VERSION ""

NS_ :

BS_:
BU_: ACC GW LAS BDC

BO_ 943 GW_3AF: 64 GW
 SG_ HU_RampInfo_EU : 263|2@0+ (1.0000000000,0.0000000000) [0.0000000000|3.0000000000] ""  ACC,LAS,mADC
 SG_ HU_MaxNavSpeed : 127|8@0+ (1.0000000000,0.0000000000) [0.0000000000|255.0000000000] ""  ACC,LAS,mADC
 SG_ HU_MapStatus : 114|3@0+ (1.0000000000,0.0000000000) [0.0000000000|7.0000000000] ""  ACC,LAS,mADC
 SG_ HU_NavSpeedLimit_EU : 487|8@0+ (1.0000000000,0.0000000000) [0.0000000000|255.0000000000] ""  ACC,LAS,mADC
 SG_ HU_ForwardRoadType_EU : 287|3@0+ (1.0000000000,0.0000000000) [0.0000000000|7.0000000000] ""  ACC,LAS,mADC
 SG_ HU_NavCurrentRoadType_EU : 284|3@0+ (1.0000000000,0.0000000000) [0.0000000000|7.0000000000] ""  ACC,LAS,mADC
 SG_ HU_NavCountryCode_EU : 447|8@0+ (1.0000000000,0.0000000000) [0.0000000000|255.0000000000] ""  ACC,LAS,mADC
 SG_ HU_realtimeNavRoadSpeedLimitType : 311|2@0+ (1.0000000000,0.0000000000) [0.0000000000|3.0000000000] ""  ACC,LAS,mADC
 SG_ HU_realtimeNavSpeedLimit : 439|8@0+ (1.0000000000,0.0000000000) [0.0000000000|255.0000000000] ""  ACC,LAS,mADC
 SG_ HU_FogSpeedLimit : 303|8@0+ (1.0000000000,0.0000000000) [0.0000000000|255.0000000000] ""  ACC,LAS,mADC
 SG_ HU_NavRoadSpeedLimitType : 309|2@0+ (1.0000000000,0.0000000000) [0.0000000000|3.0000000000] ""  ACC,LAS,mADC
 SG_ HU_SnowSpeedLimit : 63|8@0+ (1.0000000000,0.0000000000) [0.0000000000|255.0000000000] ""  ACC,LAS,mADC
 SG_ HU_RainSpeedLimit : 55|8@0+ (1.0000000000,0.0000000000) [0.0000000000|255.0000000000] ""  ACC,LAS,mADC
 SG_ HU_CRCCheck_3AF : 503|16@0+ (1.0000000000,0.0000000000) [0.0000000000|65535.0000000000] ""  ACC,LAS
 SG_ HU_RollingCounter_3AF : 491|4@0+ (1.0000000000,0.0000000000) [0.0000000000|15.0000000000] ""  ACC,LAS
 SG_ HU_ADAS_Posn_Offset : 353|13@0+ (1.0000000000,0.0000000000) [0.0000000000|8191.0000000000] "m"  ACC,LAS,mADC
 SG_ HU_ADAS_Posn_Pathldx : 359|6@0+ (1.0000000000,0.0000000000) [0.0000000000|63.0000000000] ""  ACC,LAS,mADC
 SG_ HU_LaneConfluenceDis : 155|6@0+ (10.0000000000,0.0000000000) [0.0000000000|600.0000000000] "m"  ACC,LAS,mADC
 SG_ HU_LaneConfluence : 157|2@0+ (1.0000000000,0.0000000000) [0.0000000000|3.0000000000] ""  ACC,LAS,mADC
 SG_ HU_IntervalVelocityDis : 139|6@0+ (10.0000000000,0.0000000000) [0.0000000000|600.0000000000] "m"  ACC,LAS,mADC
 SG_ HU_IntervalVelocityInfo : 141|2@0+ (1.0000000000,0.0000000000) [0.0000000000|3.0000000000] ""  ACC,LAS,mADC
 SG_ HU_CRCCheck_3AF_3 : 255|8@0+ (1.0000000000,0.0000000000) [0.0000000000|255.0000000000] ""  LAS,ACC,mADC
 SG_ HU_RollingCounter_3AF_3 : 243|4@0+ (1.0000000000,0.0000000000) [0.0000000000|15.0000000000] ""  LAS,ACC,mADC
 SG_ HU_RampDistance : 239|10@0+ (10.0000000000,0.0000000000) [0.0000000000|3000.0000000000] "m"  LAS,ACC,mADC
 SG_ HU_CurveDistance : 229|6@0+ (10.0000000000,0.0000000000) [0.0000000000|600.0000000000] "m"  LAS,ACC,mADC
 SG_ HU_EnterCurveInfo : 220|2@0+ (1.0000000000,0.0000000000) [0.0000000000|3.0000000000] ""  LAS,ACC,mADC
 SG_ HU_EnterRampInfo : 215|2@0+ (1.0000000000,0.0000000000) [0.0000000000|3.0000000000] ""  LAS,ACC,mADC
 SG_ HU_NavStatus : 223|1@0+ (1.0000000000,0.0000000000) [0.0000000000|1.0000000000] ""  LAS,ACC,mADC
 SG_ HU_NavSpeedLimitUnits : 213|2@0+ (1.0000000000,0.0000000000) [0.0000000000|3.0000000000] ""  ACC,LAS,mADC
 SG_ HU_NavSpeedLimitStatus : 211|2@0+ (1.0000000000,0.0000000000) [0.0000000000|3.0000000000] ""  ACC,LAS,mADC
 SG_ HU_CRCCheck_3BB : 319|8@0+ (1.0000000000,0.0000000000) [0.0000000000|255.0000000000] ""  ACC,LAS
 SG_ HU_RollingCounter_3BB : 307|4@0+ (1.0000000000,0.0000000000) [0.0000000000|15.0000000000] ""  ACC,LAS
 SG_ HU_SlopeGradientFar : 281|10@0+ (0.1000000000,-51.1000000000) [-51.1000000000|51.1000000000] "%"  ACC,LAS,mADC
 SG_ HU_SlopeGradient : 265|10@0+ (0.1000000000,-51.1000000000) [-51.1000000000|51.1000000000] "%"  ACC,LAS,mADC
 SG_ HU_SpeedLimitDistance : 261|6@0+ (10.0000000000,0.0000000000) [0.0000000000|600.0000000000] "m"  ACC,LAS,mADC

BO_ 947 GW_3B3: 8 GW
 SG_ BCM_BrakeLampError : 31|1@0+ (1.0000000000,0.0000000000) [0.0000000000|1.0000000000] ""  ACC,LAS,mADC
 SG_ BCM_RearFoglampStatus : 11|2@0+ (1.0000000000,0.0000000000) [0.0000000000|3.0000000000] ""  ACC,LAS,mADC

BO_ 957 GW_3BD: 64 GW
 SG_ HU_SentryModeSt : 424|3@0+ (1.0000000000,0.0000000000) [0.0000000000|5.0000000000] ""  APA,ACC,LAS,mADC
 SG_ HU_CSLAEnable : 7|2@0+ (1.0000000000,0.0000000000) [0.0000000000|3.0000000000] ""  ACC,LAS
 SG_ HU_TLAEnable : 9|2@0+ (1.0000000000,0.0000000000) [0.0000000000|3.0000000000] ""  LAS,mADC

BO_ 964 GW_3C4: 64 GW
 SG_ HU_BSDLCAMode : 183|3@0+ (1.0000000000,0.0000000000) [0.0000000000|7.0000000000] ""  ACC,LAS,mADC
 SG_ HU_CRCCheck_3C4 : 503|16@0+ (1.0000000000,0.0000000000) [0.0000000000|65535.0000000000] ""  ACC,LAS,mADC
 SG_ HU_RollingCounter_3C4 : 491|4@0+ (1.0000000000,0.0000000000) [0.0000000000|15.0000000000] ""  ACC,LAS,mADC
 SG_ HU_CRCCheck_3C7 : 319|8@0+ (1.0000000000,0.0000000000) [0.0000000000|255.0000000000] ""  LAS,ACC
 SG_ HU_RollingCounter_3C7 : 307|4@0+ (1.0000000000,0.0000000000) [0.0000000000|15.0000000000] ""  LAS,ACC
 SG_ HU_CRCCheck_3C6 : 255|8@0+ (1.0000000000,0.0000000000) [0.0000000000|255.0000000000] ""  LAS,ACC
 SG_ HU_RollingCounter_3C6 : 243|4@0+ (1.0000000000,0.0000000000) [0.0000000000|15.0000000000] ""  LAS,ACC
 SG_ HU_CRCCheck_3C4_2 : 191|8@0+ (1.0000000000,0.0000000000) [0.0000000000|255.0000000000] ""  LAS,ACC
 SG_ HU_RollingCounter_3C4_2 : 179|4@0+ (1.0000000000,0.0000000000) [0.0000000000|15.0000000000] ""  LAS,ACC
 SG_ HU_CRCCheck_3C2 : 127|8@0+ (1.0000000000,0.0000000000) [0.0000000000|255.0000000000] ""  LAS,ACC
 SG_ HU_RollingCounter_3C2 : 115|4@0+ (1.0000000000,0.0000000000) [0.0000000000|15.0000000000] ""  LAS,ACC
 SG_ HU_MapDataUpdateStatus : 118|3@0+ (1.0000000000,0.0000000000) [0.0000000000|7.0000000000] ""  LAS,ACC,mADC
 SG_ HU_RoadCurvature_600m : 281|10@0+ (1.0000000000,0.0000000000) [0.0000000000|1023.0000000000] "1/m"  LAS,ACC,mADC
 SG_ HU_RoadCurvature_400m : 275|10@0+ (1.0000000000,0.0000000000) [0.0000000000|1023.0000000000] "1/m"  LAS,ACC,mADC
 SG_ HU_RoadCurvature_300m : 269|10@0+ (1.0000000000,0.0000000000) [0.0000000000|1023.0000000000] "1/m"  LAS,ACC,mADC
 SG_ HU_RoadCurvature_100m : 263|10@0+ (1.0000000000,0.0000000000) [0.0000000000|1023.0000000000] "1/m"  LAS,ACC,mADC
 SG_ HU_RoadCurvature_90m : 239|10@0+ (1.0000000000,0.0000000000) [0.0000000000|1023.0000000000] "1/m"  LAS,ACC,mADC
 SG_ HU_RoadCurvature_80m : 217|10@0+ (1.0000000000,0.0000000000) [0.0000000000|1023.0000000000] "1/m"  LAS,ACC,mADC
 SG_ HU_RoadCurvature_70m : 211|10@0+ (1.0000000000,0.0000000000) [0.0000000000|1023.0000000000] "1/m"  LAS,ACC,mADC
 SG_ HU_RoadCurvature_60m : 205|10@0+ (1.0000000000,0.0000000000) [0.0000000000|1023.0000000000] "1/m"  LAS,ACC,mADC
 SG_ HU_RoadCurvature_50m : 199|10@0+ (1.0000000000,0.0000000000) [0.0000000000|1023.0000000000] "1/m"  LAS,ACC,mADC
 SG_ HU_RoadCurvature_40m : 161|10@0+ (1.0000000000,0.0000000000) [0.0000000000|1023.0000000000] "1/m"  LAS,ACC,mADC
 SG_ HU_RoadCurvature_30m : 155|10@0+ (1.0000000000,0.0000000000) [0.0000000000|1023.0000000000] "1/m"  LAS,ACC,mADC
 SG_ HU_RoadCurvature_20m : 149|10@0+ (1.0000000000,0.0000000000) [0.0000000000|1023.0000000000] "1/m"  LAS,ACC,mADC
 SG_ HU_RoadCurvature_10m : 143|10@0+ (1.0000000000,0.0000000000) [0.0000000000|1023.0000000000] "1/m"  LAS,ACC,mADC
 SG_ HU_Road_TrafficFlow : 105|3@0+ (1.0000000000,0.0000000000) [0.0000000000|7.0000000000] ""  LAS,ACC,mADC
 SG_ HU_To_Construction_Dis : 93|6@0+ (10.0000000000,0.0000000000) [0.0000000000|600.0000000000] "m"  LAS,ACC,mADC
 SG_ HU_Construction_Info : 95|2@0+ (1.0000000000,0.0000000000) [0.0000000000|3.0000000000] ""  LAS,ACC,mADC
 SG_ HU_RampSide : 71|2@0+ (1.0000000000,0.0000000000) [0.0000000000|3.0000000000] ""  LAS,ACC,mADC
 SG_ HU_CRCCheck_3B8 : 63|8@0+ (1.0000000000,0.0000000000) [0.0000000000|255.0000000000] ""  LAS,ACC
 SG_ HU_RollingCounter_3B8 : 51|4@0+ (1.0000000000,0.0000000000) [0.0000000000|15.0000000000] ""  LAS,ACC
 SG_ HU_NavGuiganceStatus : 47|2@0+ (1.0000000000,0.0000000000) [0.0000000000|3.0000000000] ""  LAS,ACC,mADC
 SG_ HU_TunnelLength : 37|6@0+ (1.0000000000,0.0000000000) [0.0000000000|63.0000000000] "m"  LAS,ACC,mADC
 SG_ HU_RoadCurvatureFar : 17|10@0+ (1.0000000000,0.0000000000) [0.0000000000|1023.0000000000] ""  LAS,ACC,mADC
 SG_ HU_TunnelDistance : 23|6@0+ (10.0000000000,0.0000000000) [0.0000000000|600.0000000000] "m"  LAS,ACC,mADC
 SG_ HU_RoadCurvature : 1|10@0+ (1.0000000000,0.0000000000) [0.0000000000|1023.0000000000] ""  LAS,ACC,mADC
 SG_ HU_EnterTunnelInfo : 3|2@0+ (1.0000000000,0.0000000000) [0.0000000000|3.0000000000] ""  LAS,ACC,mADC

BO_ 1021 GW_3FD: 8 GW
 SG_ BCM_DriveMode : 7|4@0+ (1.0000000000,0.0000000000) [0.0000000000|15.0000000000] ""  ACC,LAS,mADC
 SG_ BCM_PowerManageLevel : 8|3@0+ (1.0000000000,0.0000000000) [0.0000000000|7.0000000000] ""  mADC,ACC,LAS,APA

BO_ 1023 GW_3FF: 8 GW
 SG_ BCM_AutoHeadlightSts : 22|1@0+ (1.0000000000,0.0000000000) [0.0000000000|1.0000000000] ""  ACC,LAS,mADC
 SG_ BCM_FrontFoglampStatus : 21|2@0+ (1.0000000000,0.0000000000) [0.0000000000|3.0000000000] ""  ACC,LAS,mADC

BO_ 1310 GW_51E: 8 GW
 SG_ TPMS_TireTemperature : 15|8@0+ (1.0000000000,-40.0000000000) [-40.0000000000|215.0000000000] "°C"  ACC,LAS
 SG_ TPMS_TirePosition : 2|3@0+ (1.0000000000,0.0000000000) [0.0000000000|4.0000000000] ""  ACC,LAS

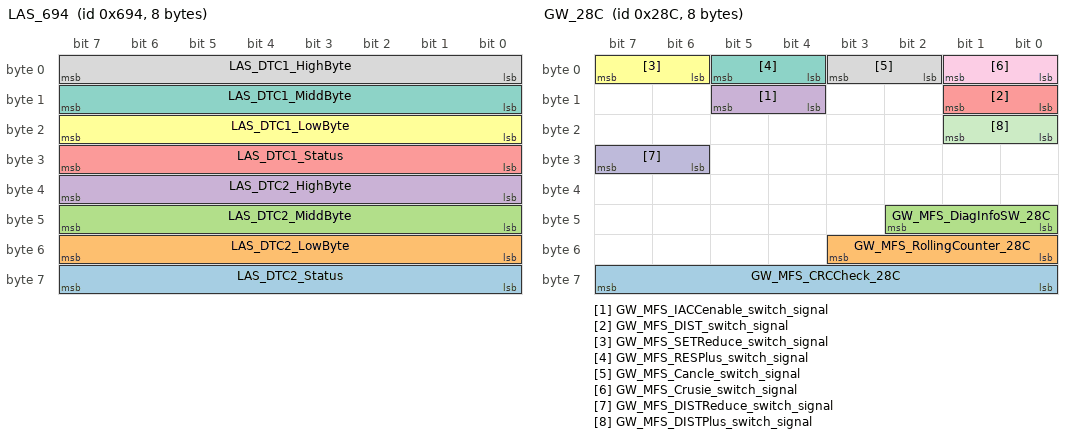
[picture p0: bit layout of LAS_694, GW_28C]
BO_ 1684 LAS_694: 8 LAS
 SG_ LAS_DTC2_Status : 63|8@0+ (1.0000000000,0.0000000000) [0.0000000000|255.0000000000] ""  GW
 SG_ LAS_DTC2_LowByte : 55|8@0+ (1.0000000000,0.0000000000) [0.0000000000|255.0000000000] ""  GW
 SG_ LAS_DTC2_MiddByte : 47|8@0+ (1.0000000000,0.0000000000) [0.0000000000|255.0000000000] ""  GW
 SG_ LAS_DTC2_HighByte : 39|8@0+ (1.0000000000,0.0000000000) [0.0000000000|255.0000000000] ""  GW
 SG_ LAS_DTC1_Status : 31|8@0+ (1.0000000000,0.0000000000) [0.0000000000|255.0000000000] ""  GW
 SG_ LAS_DTC1_LowByte : 23|8@0+ (1.0000000000,0.0000000000) [0.0000000000|255.0000000000] ""  GW
 SG_ LAS_DTC1_MiddByte : 15|8@0+ (1.0000000000,0.0000000000) [0.0000000000|255.0000000000] ""  GW
 SG_ LAS_DTC1_HighByte : 7|8@0+ (1.0000000000,0.0000000000) [0.0000000000|255.0000000000] ""  GW

BO_ 1106 LAS_452: 8 LAS
 SG_ NM_message452 : 0|1@0+ (1.0000000000,0.0000000000) [1.0000000000|1.0000000000] ""  GW,BDC

BO_ 652 GW_28C: 8 GW
 SG_ GW_MFS_CRCCheck_28C : 63|8@0+ (1.0000000000,0.0000000000) [0.0000000000|255.0000000000] ""  ACC,LAS,mADC
 SG_ GW_MFS_RollingCounter_28C : 51|4@0+ (1.0000000000,0.0000000000) [0.0000000000|15.0000000000] ""  ACC,LAS,mADC
 SG_ GW_MFS_DiagInfoSW_28C : 42|3@0+ (1.0000000000,0.0000000000) [0.0000000000|7.0000000000] ""  ACC,LAS,mADC
 SG_ GW_MFS_IACCenable_switch_signal : 13|2@0+ (1.0000000000,0.0000000000) [0.0000000000|3.0000000000] ""  ACC,LAS,mADC
 SG_ GW_MFS_DIST_switch_signal : 9|2@0+ (1.0000000000,0.0000000000) [0.0000000000|3.0000000000] ""  ACC,LAS,mADC
 SG_ GW_MFS_SETReduce_switch_signal : 7|2@0+ (1.0000000000,0.0000000000) [0.0000000000|3.0000000000] ""  ACC,LAS,mADC
 SG_ GW_MFS_RESPlus_switch_signal : 5|2@0+ (1.0000000000,0.0000000000) [0.0000000000|3.0000000000] ""  ACC,LAS,mADC
 SG_ GW_MFS_Cancle_switch_signal : 3|2@0+ (1.0000000000,0.0000000000) [0.0000000000|3.0000000000] ""  ACC,LAS,mADC
 SG_ GW_MFS_Crusie_switch_signal : 1|2@0+ (1.0000000000,0.0000000000) [0.0000000000|3.0000000000] ""  ACC,LAS,mADC
 SG_ GW_MFS_DISTReduce_switch_signal : 31|2@0+ (1.0000000000,0.0000000000) [0.0000000000|3.0000000000] ""  LAS,ACC
 SG_ GW_MFS_DISTPlus_switch_signal : 17|2@0+ (1.0000000000,0.0000000000) [0.0000000000|3.0000000000] ""  LAS,ACC

BO_ 817 GW_331: 8 GW
 SG_ TCU_TransFaultLevel : 54|3@0+ (1.0000000000,0.0000000000) [0.0000000000|7.0000000000] ""  ACC,LAS,APA

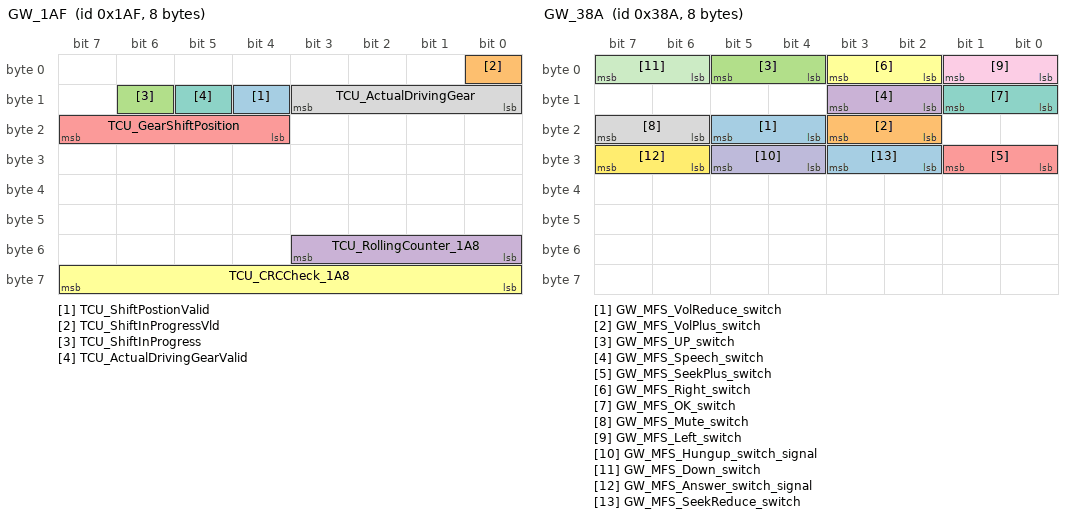
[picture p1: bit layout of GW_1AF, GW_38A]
BO_ 431 GW_1AF: 8 GW
 SG_ TCU_ShiftPostionValid : 12|1@0+ (1.0000000000,0.0000000000) [0.0000000000|1.0000000000] ""  ACC,LAS,APA,mADC
 SG_ TCU_ShiftInProgressVld : 0|1@0+ (1.0000000000,0.0000000000) [0.0000000000|1.0000000000] ""  ACC,LAS
 SG_ TCU_ShiftInProgress : 14|1@0+ (1.0000000000,0.0000000000) [0.0000000000|1.0000000000] ""  ACC,LAS
 SG_ TCU_RollingCounter_1A8 : 51|4@0+ (1.0000000000,0.0000000000) [0.0000000000|15.0000000000] ""  mADC,APA,ACC,LAS
 SG_ TCU_GearShiftPosition : 23|4@0+ (1.0000000000,0.0000000000) [0.0000000000|15.0000000000] ""  APA,ACC,LAS,mADC
 SG_ TCU_CRCCheck_1A8 : 63|8@0+ (1.0000000000,0.0000000000) [0.0000000000|255.0000000000] ""  mADC,APA,ACC,LAS
 SG_ TCU_ActualDrivingGearValid : 13|1@0+ (1.0000000000,0.0000000000) [0.0000000000|1.0000000000] ""  APA,ACC,LAS,mADC
 SG_ TCU_ActualDrivingGear : 11|4@0+ (1.0000000000,0.0000000000) [0.0000000000|15.0000000000] ""  APA,ACC,LAS,mADC

BO_ 800 GW_320: 8 GW
 SG_ GW_ResetReq : 31|7@0+ (1.0000000000,0.0000000000) [0.0000000000|127.0000000000] ""  ACC,LAS,APA,mADC

BO_ 922 LAS_39A: 64 LAS
 SG_ LAS_RoadFeature : 395|4@0+ (1.0000000000,0.0000000000) [0.0000000000|15.0000000000] ""  GW,mADC
 SG_ LAS_RD4LongDistence : 407|8@0+ (1.0000000000,0.0000000000) [0.0000000000|255.0000000000] ""  GW,mADC
 SG_ LAS_RD3LongDistence : 415|8@0+ (1.0000000000,0.0000000000) [0.0000000000|255.0000000000] ""  GW,mADC
 SG_ LAS_RD2LongDistence : 423|8@0+ (1.0000000000,0.0000000000) [0.0000000000|255.0000000000] ""  GW,mADC
 SG_ LAS_RD1LongDistence : 431|8@0+ (1.0000000000,0.0000000000) [0.0000000000|255.0000000000] ""  GW,mADC
 SG_ LAS_RD4RoadInforAvailable : 399|2@0+ (1.0000000000,0.0000000000) [0.0000000000|3.0000000000] ""  GW,mADC
 SG_ LAS_RD3RoadInforAvailable : 439|2@0+ (1.0000000000,0.0000000000) [0.0000000000|3.0000000000] ""  GW,mADC
 SG_ LAS_RD2RoadInforAvailable : 397|2@0+ (1.0000000000,0.0000000000) [0.0000000000|3.0000000000] ""  GW,mADC
 SG_ LAS_RD1RoadInforAvailable : 437|2@0+ (1.0000000000,0.0000000000) [0.0000000000|3.0000000000] ""  GW,mADC
 SG_ LAS_RollingCounter_579 : 435|4@0+ (1.0000000000,0.0000000000) [0.0000000000|15.0000000000] ""  GW,mADC
 SG_ LAS_CRCCheck_579 : 447|8@0+ (1.0000000000,0.0000000000) [0.0000000000|255.0000000000] ""  GW,mADC
 SG_ LAS_TSRSpeedLimitType : 7|2@0+ (1.0000000000,0.0000000000) [0.0000000000|3.0000000000] ""  GW
 SG_ ACC_RollingCounter_39A : 491|4@0+ (1.0000000000,0.0000000000) [0.0000000000|15.0000000000] ""  GW,mADC
 SG_ ACC_CRCCheck_39A : 503|16@0+ (1.0000000000,0.0000000000) [0.0000000000|65535.0000000000] ""  GW,mADC
 SG_ LAS_TSRRightLaneStatus : 55|3@0+ (1.0000000000,0.0000000000) [0.0000000000|7.0000000000] ""  GW,mADC
 SG_ LAS_TSRLeftLaneStatus : 47|3@0+ (1.0000000000,0.0000000000) [0.0000000000|7.0000000000] ""  GW,mADC
 SG_ LAS_CRCCheck_3C0 : 191|8@0+ (1.0000000000,0.0000000000) [0.0000000000|255.0000000000] ""  GW,mADC
 SG_ LAS_RollingCounter_3C0 : 179|4@0+ (1.0000000000,0.0000000000) [0.0000000000|15.0000000000] ""  GW,mADC
 SG_ LAS_TSRRightLaneSpdLimit : 143|8@0+ (1.0000000000,0.0000000000) [0.0000000000|255.0000000000] ""  GW,mADC
 SG_ LAS_TSRLeftLaneSpdLimit : 135|8@0+ (1.0000000000,0.0000000000) [0.0000000000|255.0000000000] ""  GW,mADC
 SG_ LAS_CRCCheck_3D4 : 127|8@0+ (1.0000000000,0.0000000000) [0.0000000000|255.0000000000] ""  GW,mADC
 SG_ LAS_RollingCounter_3D4 : 115|4@0+ (1.0000000000,0.0000000000) [0.0000000000|15.0000000000] ""  GW,mADC
 SG_ LAS_TLAStopLine_HostLane : 111|8@0+ (1.0000000000,0.0000000000) [0.0000000000|255.0000000000] ""  GW,mADC
 SG_ LAS_TLADistance_HostLane : 103|8@0+ (1.0000000000,0.0000000000) [0.0000000000|255.0000000000] ""  GW,mADC
 SG_ LAS_TLACountDownTime_HostLane : 94|7@0+ (1.0000000000,0.0000000000) [0.0000000000|127.0000000000] ""  GW,mADC
 SG_ LAS_TSRMandatorySign : 70|4@0+ (1.0000000000,0.0000000000) [0.0000000000|15.0000000000] ""  GW,mADC
 SG_ LAS_TSRWarningSign : 84|5@0+ (1.0000000000,0.0000000000) [0.0000000000|31.0000000000] ""  GW,mADC
 SG_ LAS_TSRProhibitionSign : 66|5@0+ (1.0000000000,0.0000000000) [0.0000000000|31.0000000000] ""  GW,mADC
 SG_ LAS_CRCCheck_332 : 63|8@0+ (1.0000000000,0.0000000000) [0.0000000000|255.0000000000] ""  GW,mADC
 SG_ LAS_RollingCounter_332 : 51|4@0+ (1.0000000000,0.0000000000) [0.0000000000|15.0000000000] ""  GW,mADC
 SG_ LAS_OverspeedSoundWarningEnSt : 27|1@0+ (1.0000000000,0.0000000000) [0.0000000000|1.0000000000] ""  GW,mADC
 SG_ LAS_TSREnable : 30|1@0+ (1.0000000000,0.0000000000) [0.0000000000|1.0000000000] ""  GW,mADC
 SG_ LAS_HMAEnableStatus : 22|1@0+ (1.0000000000,0.0000000000) [0.0000000000|1.0000000000] ""  GW,mADC
 SG_ LAS_HMALightDistribution : 8|1@0+ (1.0000000000,0.0000000000) [0.0000000000|1.0000000000] ""  GW,mADC
 SG_ LAS_HMAStatus : 44|2@0+ (1.0000000000,0.0000000000) [0.0000000000|3.0000000000] ""  GW,mADC
 SG_ LAS_TSRHostSpdLimitUnits : 41|2@0+ (1.0000000000,0.0000000000) [0.0000000000|3.0000000000] ""  GW,mADC
 SG_ LAS_TSRHostSpdLimit : 39|8@0+ (1.0000000000,0.0000000000) [0.0000000000|255.0000000000] ""  GW,mADC
 SG_ LAS_TSRStatus : 26|3@0+ (1.0000000000,0.0000000000) [0.0000000000|7.0000000000] ""  GW,mADC
 SG_ LAS_FrontCameraCalibrationStatus : 20|2@0+ (1.0000000000,0.0000000000) [0.0000000000|3.0000000000] ""  GW,mADC
 SG_ LAS_FrontCameraFailureStatus : 17|2@0+ (1.0000000000,0.0000000000) [0.0000000000|3.0000000000] ""  GW,mADC
 SG_ LAS_OverspeedWarningOffset : 14|6@0+ (1.0000000000,-10.0000000000) [-10.0000000000|47.0000000000] "km/h"  GW,mADC
 SG_ LAS_OverspeedWarningEnableStatus : 15|1@0+ (1.0000000000,0.0000000000) [0.0000000000|1.0000000000] ""  GW,mADC
 SG_ LAS_OverspeedSoundWarning : 2|1@0+ (1.0000000000,0.0000000000) [0.0000000000|1.0000000000] ""  GW,mADC
 SG_ LAS_OverspeedVisualWarning : 5|1@0+ (1.0000000000,0.0000000000) [0.0000000000|1.0000000000] ""  GW,mADC
 SG_ LAS_CRCCheck_37D : 255|8@0+ (1.0000000000,0.0000000000) [0.0000000000|255.0000000000] ""  GW,mADC
 SG_ LAS_RollingCounter_37D : 243|4@0+ (1.0000000000,0.0000000000) [0.0000000000|15.0000000000] ""  GW,mADC
 SG_ LAS_TLAArrowDirection_RightLane : 236|3@0+ (1.0000000000,0.0000000000) [0.0000000000|7.0000000000] ""  GW,mADC
 SG_ LAS_TLAObjectType_RightLane : 239|3@0+ (1.0000000000,0.0000000000) [0.0000000000|7.0000000000] ""  GW,mADC
 SG_ LAS_TLAObjectStatus_RightLane : 247|2@0+ (1.0000000000,0.0000000000) [0.0000000000|3.0000000000] ""  GW,mADC
 SG_ LAS_TLAObjectColour_RightLane : 225|2@0+ (1.0000000000,0.0000000000) [0.0000000000|3.0000000000] ""  GW,mADC
 SG_ LAS_TLAObjectDetection_RightLane : 227|1@0+ (1.0000000000,0.0000000000) [0.0000000000|1.0000000000] ""  GW,mADC
 SG_ LAS_TLAArrowDirection_LeftLane : 216|3@0+ (1.0000000000,0.0000000000) [0.0000000000|7.0000000000] ""  GW,mADC
 SG_ LAS_TLAObjectType_LeftLane : 219|3@0+ (1.0000000000,0.0000000000) [0.0000000000|7.0000000000] ""  GW,mADC
 SG_ LAS_TLAObjectStatus_LeftLane : 245|2@0+ (1.0000000000,0.0000000000) [0.0000000000|3.0000000000] ""  GW,mADC
 SG_ LAS_TLAObjectColour_LeftLane : 221|2@0+ (1.0000000000,0.0000000000) [0.0000000000|3.0000000000] ""  GW,mADC
 SG_ LAS_TLAObjectDetection_LeftLane : 223|1@0+ (1.0000000000,0.0000000000) [0.0000000000|1.0000000000] ""  GW,mADC
 SG_ LAS_TLAArrowDirection_HostLane : 215|3@0+ (1.0000000000,0.0000000000) [0.0000000000|7.0000000000] ""  GW,mADC
 SG_ LAS_TLAObjectStatus_HostLane : 199|2@0+ (1.0000000000,0.0000000000) [0.0000000000|3.0000000000] ""  GW,mADC
 SG_ LAS_TLAObjectType_HostLane : 212|3@0+ (1.0000000000,0.0000000000) [0.0000000000|7.0000000000] ""  GW,mADC
 SG_ LAS_TLAObjectColour_HostLane : 204|2@0+ (1.0000000000,0.0000000000) [0.0000000000|3.0000000000] ""  GW,mADC
 SG_ LAS_TLAObjectDetection_HostLane : 200|1@0+ (1.0000000000,0.0000000000) [0.0000000000|1.0000000000] ""  GW,mADC
 SG_ LAS_TLAWarninglevel : 197|2@0+ (1.0000000000,0.0000000000) [0.0000000000|3.0000000000] ""  GW,mADC
 SG_ LAS_TLAStatus : 193|2@0+ (1.0000000000,0.0000000000) [0.0000000000|3.0000000000] ""  GW,mADC
 SG_ LAS_TLAEnable : 194|1@0+ (1.0000000000,0.0000000000) [0.0000000000|1.0000000000] ""  GW,mADC
 SG_ LAS_RoadSignCenterLatRange_RLane : 306|9@0+ (0.0500000000,-8.0000000000) [-8.0000000000|17.5500000000] "m"  GW,mADC
 SG_ LAS_RoadSignCenterLngRange_RLane : 299|9@0+ (0.1000000000,0.0000000000) [0.0000000000|51.1000000000] "m"  GW,mADC
 SG_ LAS_RoadSignCenterLatRange_LLane : 292|9@0+ (0.0500000000,-8.0000000000) [-8.0000000000|17.5500000000] "m"  GW,mADC
 SG_ LAS_RoadSignCenterLngRange_LLane : 285|9@0+ (0.1000000000,0.0000000000) [0.0000000000|51.1000000000] "m"  GW,mADC
 SG_ LAS_RoadSignCenterLatRange_HLane : 278|9@0+ (0.0500000000,-8.0000000000) [-8.0000000000|17.5500000000] "m"  GW,mADC
 SG_ LAS_RoadSignCenterLngRange_HLane : 271|9@0+ (0.1000000000,0.0000000000) [0.0000000000|51.1000000000] "m"  GW,mADC
 SG_ LAS_CrosswalkLngRange_HLane : 263|8@0+ (1.0000000000,0.0000000000) [0.0000000000|255.0000000000] ""  GW,mADC
 SG_ LAS_RoadSignType_RLane : 157|5@0+ (1.0000000000,0.0000000000) [0.0000000000|15.0000000000] ""  GW,mADC
 SG_ LAS_RoadSignType_LLane : 146|5@0+ (1.0000000000,0.0000000000) [0.0000000000|15.0000000000] ""  GW,mADC
 SG_ LAS_RoadSignType_HLane : 151|5@0+ (1.0000000000,0.0000000000) [0.0000000000|15.0000000000] ""  GW,mADC

BO_ 784 GW_310: 8 GW
 SG_ AMP_AllAlarmFailureStatus : 38|1@0+ (1.0000000000,0.0000000000) [0.0000000000|1.0000000000] ""  ACC,LAS
 SG_ AMP_IPEnableAlarmFailureStatus : 39|1@0+ (1.0000000000,0.0000000000) [0.0000000000|1.0000000000] ""  ACC,LAS

BO_ 1000 GW_3E8: 8 GW
 SG_ BCM_SOF_Q_STATE : 51|2@0+ (1.0000000000,0.0000000000) [0.0000000000|3.0000000000] ""  ACC,LAS
 SG_ BCM_SOF_Q : 15|8@0+ (0.5000000000,0.0000000000) [0.0000000000|127.5000000000] "Ah"  ACC,LAS,APA

BO_ 999 GW_3E7: 8 GW
 SG_ BCM_Status_Temp : 51|2@0+ (1.0000000000,0.0000000000) [0.0000000000|3.0000000000] ""  ACC,LAS
 SG_ BCM_T_BATT : 39|8@0+ (1.0000000000,-40.0000000000) [-40.0000000000|215.0000000000] "°C"  ACC,LAS

BO_ 906 GW_38A: 8 GW
 SG_ GW_MFS_VolReduce_switch : 21|2@0+ (1.0000000000,0.0000000000) [0.0000000000|3.0000000000] ""  LAS,ACC
 SG_ GW_MFS_VolPlus_switch : 19|2@0+ (1.0000000000,0.0000000000) [0.0000000000|3.0000000000] ""  LAS,ACC
 SG_ GW_MFS_UP_switch : 5|2@0+ (1.0000000000,0.0000000000) [0.0000000000|3.0000000000] ""  LAS,ACC
 SG_ GW_MFS_Speech_switch : 11|2@0+ (1.0000000000,0.0000000000) [0.0000000000|3.0000000000] ""  LAS,ACC
 SG_ GW_MFS_SeekPlus_switch : 25|2@0+ (1.0000000000,0.0000000000) [0.0000000000|3.0000000000] ""  LAS,ACC
 SG_ GW_MFS_Right_switch : 3|2@0+ (1.0000000000,0.0000000000) [0.0000000000|3.0000000000] ""  LAS,ACC
 SG_ GW_MFS_OK_switch : 9|2@0+ (1.0000000000,0.0000000000) [0.0000000000|3.0000000000] ""  LAS,ACC
 SG_ GW_MFS_Mute_switch : 23|2@0+ (1.0000000000,0.0000000000) [0.0000000000|3.0000000000] ""  LAS,ACC
 SG_ GW_MFS_Left_switch : 1|2@0+ (1.0000000000,0.0000000000) [0.0000000000|3.0000000000] ""  LAS,ACC
 SG_ GW_MFS_Hungup_switch_signal : 29|2@0+ (1.0000000000,0.0000000000) [0.0000000000|3.0000000000] ""  LAS,ACC
 SG_ GW_MFS_Down_switch : 7|2@0+ (1.0000000000,0.0000000000) [0.0000000000|3.0000000000] ""  LAS,ACC
 SG_ GW_MFS_Answer_switch_signal : 31|2@0+ (1.0000000000,0.0000000000) [0.0000000000|3.0000000000] ""  LAS,ACC
 SG_ GW_MFS_SeekReduce_switch : 27|2@0+ (1.0000000000,0.0000000000) [0.0000000000|3.0000000000] ""  LAS,ACC

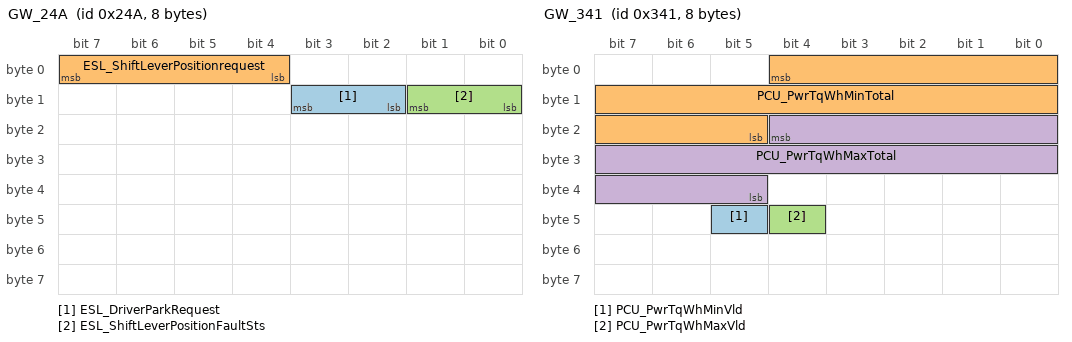
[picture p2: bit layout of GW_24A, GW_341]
BO_ 586 GW_24A: 8 GW
 SG_ ESL_DriverParkRequest : 11|2@0+ (1.0000000000,0.0000000000) [0.0000000000|3.0000000000] ""  BDC,APA,mADC,LAS,ACC
 SG_ ESL_ShiftLeverPositionrequest : 7|4@0+ (1.0000000000,0.0000000000) [0.0000000000|15.0000000000] ""  BDC,APA,ACC,LAS,mADC
 SG_ ESL_ShiftLeverPositionFaultSts : 9|2@0+ (1.0000000000,0.0000000000) [0.0000000000|3.0000000000] ""  BDC,APA,ACC,LAS,mADC

BO_ 833 GW_341: 8 GW
 SG_ PCU_PwrTqWhMinVld : 45|1@0+ (1.0000000000,0.0000000000) [0.0000000000|1.0000000000] ""  APA,ACC,LAS,mADC
 SG_ PCU_PwrTqWhMinTotal : 4|16@0+ (1.0000000000,-32768.0000000000) [-32768.0000000000|32767.0000000000] "Nm"  APA,ACC,LAS,mADC
 SG_ PCU_PwrTqWhMaxVld : 44|1@0+ (1.0000000000,0.0000000000) [0.0000000000|1.0000000000] ""  APA,ACC,LAS,mADC
 SG_ PCU_PwrTqWhMaxTotal : 20|16@0+ (1.0000000000,-32768.0000000000) [-32768.0000000000|32767.0000000000] "Nm"  APA,ACC,LAS,mADC

BO_ 866 GW_362: 8 GW
 SG_ PCU_DrvMod : 21|3@0+ (1.0000000000,0.0000000000) [0.0000000000|7.0000000000] ""  APA,LAS,ACC
 SG_ PCU_DrvModVld : 18|1@0+ (1.0000000000,0.0000000000) [0.0000000000|1.0000000000] ""  ACC,LAS

BO_ 723 ACC_2D3: 64 ACC
 SG_ ACC_CRCCheck_283 : 127|8@0+ (1.0000000000,0.0000000000) [0.0000000000|255.0000000000] ""  GW,LAS
 SG_ ACC_RollingCounter_283 : 115|4@0+ (1.0000000000,0.0000000000) [0.0000000000|15.0000000000] ""  GW,LAS
 SG_ ACC_AEBTargetLatRelSpeed_for_SRS : 77|10@0+ (0.1250000000,-64.0000000000) [-64.0000000000|63.8750000000] "m/s"  GW,LAS,mADC
 SG_ ACC_AEBTargetLatRange_for_SRS : 71|10@0+ (0.1000000000,-50.0000000000) [-50.0000000000|50.0000000000] "m"  GW,LAS,mADC
 SG_ ACC_CRCCheckr_282 : 63|8@0+ (1.0000000000,0.0000000000) [0.0000000000|255.0000000000] ""  GW,LAS
 SG_ ACC_RollingCounter_282 : 51|4@0+ (1.0000000000,0.0000000000) [0.0000000000|15.0000000000] ""  GW,LAS
 SG_ ACC_AEBTargetProb_for_SRS : 38|7@0+ (1.0000000000,0.0000000000) [0.0000000000|100.0000000000] "%"  GW,LAS,mADC
 SG_ ACC_AEBTargetType_for_SRS : 26|4@0+ (1.0000000000,0.0000000000) [0.0000000000|15.0000000000] ""  GW,LAS,mADC
 SG_ ACC_AEBTargetTTC_for_SRS : 18|8@0+ (0.0100000000,0.0100000000) [0.0100000000|2.5000000000] "s"  GW,LAS,mADC
 SG_ ACC_AEBTargetRelSpeed_for_SRS : 11|9@0+ (1.0000000000,-250.0000000000) [-250.0000000000|250.0000000000] "km/h"  GW,LAS,mADC
 SG_ ACC_AEBTargetLngRange_for_SRS : 4|9@0+ (0.5000000000,-70.0000000000) [-70.0000000000|180.0000000000] "m"  GW,LAS,mADC
 SG_ ACC_AEBActive_for_SRS : 5|1@0+ (1.0000000000,0.0000000000) [0.0000000000|1.0000000000] ""  GW,LAS,mADC
 SG_ ACC_AEBStatus_for_SRS : 7|2@0+ (1.0000000000,0.0000000000) [0.0000000000|3.0000000000] ""  GW,LAS,mADC

BO_ 780 LAS_30C: 8 LAS
 SG_ LAS_ResetSts : 7|3@0+ (1.0000000000,0.0000000000) [0.0000000000|7.0000000000] ""  GW

BO_ 738 GW_2E2: 64 GW
 SG_ RLR_CRCCheck_2E2 : 503|16@0+ (1.0000000000,0.0000000000) [0.0000000000|65535.0000000000] ""  LAS
 SG_ RLR_RollingCounter_2E2 : 491|4@0+ (1.0000000000,0.0000000000) [0.0000000000|15.0000000000] ""  LAS
 SG_ RLR_ElkOBJ2_Measured : 313|2@0+ (1.0000000000,0.0000000000) [0.0000000000|3.0000000000] ""  LAS
 SG_ RLR_ElkOBJ2_ExistProb : 319|6@0+ (2.0000000000,0.0000000000) [0.0000000000|100.0000000000] "%"  LAS
 SG_ RLR_ElkOBJ2_Location : 305|2@0+ (1.0000000000,0.0000000000) [0.0000000000|3.0000000000] ""  LAS
 SG_ RLR_ElkOBJ2_RelAx : 298|9@0+ (0.0625000000,-16.0000000000) [-16.0000000000|15.9375000000] "m/s2"  LAS
 SG_ RLR_ElkOBJ2_RelAy : 292|10@0+ (0.0312500000,-16.0000000000) [-16.0000000000|15.9688000000] "m/s2"  LAS
 SG_ RLR_ElkOBJ2_RelVx : 272|12@0+ (0.0625000000,-128.0000000000) [-128.0000000000|127.9380000000] "m/s"  LAS
 SG_ RLR_ElkOBJ2_RelVy : 266|10@0+ (0.1250000000,-64.0000000000) [-64.0000000000|63.8750000000] "m/s"  LAS
 SG_ RLR_ElkOBJ2_Dx : 263|13@0+ (0.0625000000,-256.0000000000) [-256.0000000000|255.9380000000] "m"  LAS
 SG_ RLR_ElkOBJ2_RefPointLoc : 251|3@0+ (1.0000000000,0.0000000000) [0.0000000000|7.0000000000] ""  LAS
 SG_ RLR_ElkOBJ2_Dy : 246|11@0+ (0.1250000000,-128.0000000000) [-128.0000000000|127.8750000000] "m"  LAS
 SG_ RLR_ElkOBJ2_HeadingAngle : 224|10@0+ (0.0100000000,-3.1400000000) [-3.1400000000|3.1400000000] "rad"  LAS
 SG_ RLR_ElkOBJ2_Length : 217|9@0+ (0.0500000000,0.0000000000) [0.0000000000|25.5000000000] "m"  LAS
 SG_ RLR_ElkOBJ2_Height : 210|9@0+ (0.0100000000,0.0000000000) [0.0000000000|5.1100000000] "m"  LAS
 SG_ RLR_ElkOBJ2_Width : 205|11@0+ (0.0100000000,0.0000000000) [0.0000000000|12.0000000000] "m"  LAS
 SG_ RLR_ElkOBJ2_Type : 192|3@0+ (1.0000000000,0.0000000000) [0.0000000000|7.0000000000] ""  LAS
 SG_ RLR_ElkOBJ2_Track_ID : 199|7@0+ (1.0000000000,0.0000000000) [0.0000000000|127.0000000000] ""  LAS
 SG_ RLR_ElkOBJ2_RefPointDx : 168|13@0+ (0.0625000000,-256.0000000000) [-256.0000000000|255.9380000000] "m"  LAS
 SG_ RLR_ElkOBJ2_RefPointDy : 163|11@0+ (0.1250000000,-128.0000000000) [-128.0000000000|127.8750000000] "m"  LAS
 SG_ RLR_ElkOBJ2_ObstacleProb : 153|6@0+ (2.0000000000,0.0000000000) [0.0000000000|100.0000000000] "%"  LAS
 SG_ RLR_ElkOBJ1_RefPointDx : 150|13@0+ (0.0625000000,-256.0000000000) [-256.0000000000|255.9380000000] "m"  LAS
 SG_ RLR_ElkOBJ1_RefPointDy : 129|11@0+ (0.1250000000,-128.0000000000) [-128.0000000000|127.8750000000] "m"  LAS
 SG_ RLR_ElkOBJ1_ObstacleProb : 135|6@0+ (2.0000000000,0.0000000000) [0.0000000000|100.0000000000] "%"  LAS
 SG_ RLR_ElkOBJ1_Measured : 121|2@0+ (1.0000000000,0.0000000000) [0.0000000000|3.0000000000] ""  LAS
 SG_ RLR_ElkOBJ1_ExistProb : 127|6@0+ (2.0000000000,0.0000000000) [0.0000000000|100.0000000000] "%"  LAS
 SG_ RLR_ElkOBJ1_Location : 113|2@0+ (1.0000000000,0.0000000000) [0.0000000000|3.0000000000] ""  LAS
 SG_ RLR_ElkOBJ1_RelAx : 106|9@0+ (0.0625000000,-16.0000000000) [-16.0000000000|15.9375000000] "m/s2"  LAS
 SG_ RLR_ElkOBJ1_RelAy : 100|10@0+ (0.0312500000,-16.0000000000) [-16.0000000000|15.9688000000] "m/s2"  LAS
 SG_ RLR_ElkOBJ1_RelVx : 80|12@0+ (0.0625000000,-128.0000000000) [-128.0000000000|127.9380000000] "m/s"  LAS
 SG_ RLR_ElkOBJ1_RelVy : 74|10@0+ (0.1250000000,-64.0000000000) [-64.0000000000|63.8750000000] "m/s"  LAS
 SG_ RLR_ElkOBJ1_Dx : 71|13@0+ (0.0625000000,-256.0000000000) [-256.0000000000|255.9380000000] "m"  LAS
 SG_ RLR_ElkOBJ1_RefPointLoc : 59|3@0+ (1.0000000000,0.0000000000) [0.0000000000|7.0000000000] ""  LAS
 SG_ RLR_ElkOBJ1_Dy : 54|11@0+ (0.1250000000,-128.0000000000) [-128.0000000000|127.8750000000] "m"  LAS
 SG_ RLR_ElkOBJ1_HeadingAngle : 32|10@0+ (0.0100000000,-3.1400000000) [-3.1400000000|3.1400000000] "rad"  LAS
 SG_ RLR_ElkOBJ1_Length : 25|9@0+ (0.0500000000,0.0000000000) [0.0000000000|25.5000000000] "m"  LAS
 SG_ RLR_ElkOBJ1_Height : 18|9@0+ (0.0100000000,0.0000000000) [0.0000000000|5.1100000000] "m"  LAS
 SG_ RLR_ElkOBJ1_Width : 13|11@0+ (0.0100000000,0.0000000000) [0.0000000000|12.0000000000] "m"  LAS
 SG_ RLR_ElkOBJ1_Type : 0|3@0+ (1.0000000000,0.0000000000) [0.0000000000|7.0000000000] ""  LAS
 SG_ RLR_ElkOBJ1_Track_ID : 7|7@0+ (1.0000000000,0.0000000000) [0.0000000000|127.0000000000] ""  LAS

BO_ 739 GW_2E3: 64 GW
 SG_ RLR_CRCCheck_2E3 : 503|16@0+ (1.0000000000,0.0000000000) [0.0000000000|65535.0000000000] ""  LAS
 SG_ RLR_RollingCounter_2E3 : 491|4@0+ (1.0000000000,0.0000000000) [0.0000000000|15.0000000000] ""  LAS
 SG_ RLR_ElkOBJ4_Measured : 313|2@0+ (1.0000000000,0.0000000000) [0.0000000000|3.0000000000] ""  LAS
 SG_ RLR_ElkOBJ4_ExistProb : 319|6@0+ (2.0000000000,0.0000000000) [0.0000000000|100.0000000000] "%"  LAS
 SG_ RLR_ElkOBJ4_Location : 305|2@0+ (1.0000000000,0.0000000000) [0.0000000000|3.0000000000] ""  LAS
 SG_ RLR_ElkOBJ4_RelAx : 298|9@0+ (0.0625000000,-16.0000000000) [-16.0000000000|15.9375000000] "m/s2"  LAS
 SG_ RLR_ElkOBJ4_RelAy : 292|10@0+ (0.0312500000,-16.0000000000) [-16.0000000000|15.9688000000] "m/s2"  LAS
 SG_ RLR_ElkOBJ4_RelVx : 272|12@0+ (0.0625000000,-128.0000000000) [-128.0000000000|127.9380000000] "m/s"  LAS
 SG_ RLR_ElkOBJ4_RelVy : 266|10@0+ (0.1250000000,-64.0000000000) [-64.0000000000|63.8750000000] "m/s"  LAS
 SG_ RLR_ElkOBJ4_Dx : 263|13@0+ (0.0625000000,-256.0000000000) [-256.0000000000|255.9380000000] "m"  LAS
 SG_ RLR_ElkOBJ4_RefPointLoc : 251|3@0+ (1.0000000000,0.0000000000) [0.0000000000|7.0000000000] ""  LAS
 SG_ RLR_ElkOBJ4_Dy : 246|11@0+ (0.1250000000,-128.0000000000) [-128.0000000000|127.8750000000] "m"  LAS
 SG_ RLR_ElkOBJ4_HeadingAngle : 224|10@0+ (0.0100000000,-3.1400000000) [-3.1400000000|3.1400000000] "rad"  LAS
 SG_ RLR_ElkOBJ4_Length : 217|9@0+ (0.0500000000,0.0000000000) [0.0000000000|25.5000000000] "m"  LAS
 SG_ RLR_ElkOBJ4_Height : 210|9@0+ (0.0100000000,0.0000000000) [0.0000000000|5.1100000000] "m"  LAS
 SG_ RLR_ElkOBJ4_Width : 205|11@0+ (0.0100000000,0.0000000000) [0.0000000000|12.0000000000] "m"  LAS
 SG_ RLR_ElkOBJ4_Type : 192|3@0+ (1.0000000000,0.0000000000) [0.0000000000|7.0000000000] ""  LAS
 SG_ RLR_ElkOBJ4_Track_ID : 199|7@0+ (1.0000000000,0.0000000000) [0.0000000000|127.0000000000] ""  LAS
 SG_ RLR_ElkOBJ4_RefPointDx : 168|13@0+ (0.0625000000,-256.0000000000) [-256.0000000000|255.9380000000] "m"  LAS
 SG_ RLR_ElkOBJ4_RefPointDy : 163|11@0+ (0.1250000000,-128.0000000000) [-128.0000000000|127.8750000000] "m"  LAS
 SG_ RLR_ElkOBJ4_ObstacleProb : 153|6@0+ (2.0000000000,0.0000000000) [0.0000000000|100.0000000000] "%"  LAS
 SG_ RLR_ElkOBJ3_RefPointDx : 150|13@0+ (0.0625000000,-256.0000000000) [-256.0000000000|255.9380000000] "m"  LAS
 SG_ RLR_ElkOBJ3_RefPointDy : 129|11@0+ (0.1250000000,-128.0000000000) [-128.0000000000|127.8750000000] "m"  LAS
 SG_ RLR_ElkOBJ3_ObstacleProb : 135|6@0+ (2.0000000000,0.0000000000) [0.0000000000|100.0000000000] "%"  LAS
 SG_ RLR_ElkOBJ3_Measured : 121|2@0+ (1.0000000000,0.0000000000) [0.0000000000|3.0000000000] ""  LAS
 SG_ RLR_ElkOBJ3_ExistProb : 127|6@0+ (2.0000000000,0.0000000000) [0.0000000000|100.0000000000] "%"  LAS
 SG_ RLR_ElkOBJ3_Location : 113|2@0+ (1.0000000000,0.0000000000) [0.0000000000|3.0000000000] ""  LAS
 SG_ RLR_ElkOBJ3_RelAx : 106|9@0+ (0.0625000000,-16.0000000000) [-16.0000000000|15.9375000000] "m/s2"  LAS
 SG_ RLR_ElkOBJ3_RelAy : 100|10@0+ (0.0312500000,-16.0000000000) [-16.0000000000|15.9688000000] "m/s2"  LAS
 SG_ RLR_ElkOBJ3_RelVx : 80|12@0+ (0.0625000000,-128.0000000000) [-128.0000000000|127.9380000000] "m/s"  LAS
 SG_ RLR_ElkOBJ3_RelVy : 74|10@0+ (0.1250000000,-64.0000000000) [-64.0000000000|63.8750000000] "m/s"  LAS
 SG_ RLR_ElkOBJ3_Dx : 71|13@0+ (0.0625000000,-256.0000000000) [-256.0000000000|255.9380000000] "m"  LAS
 SG_ RLR_ElkOBJ3_RefPointLoc : 59|3@0+ (1.0000000000,0.0000000000) [0.0000000000|7.0000000000] ""  LAS
 SG_ RLR_ElkOBJ3_Dy : 54|11@0+ (0.1250000000,-128.0000000000) [-128.0000000000|127.8750000000] "m"  LAS
 SG_ RLR_ElkOBJ3_HeadingAngle : 32|10@0+ (0.0100000000,-3.1400000000) [-3.1400000000|3.1400000000] "rad"  LAS
 SG_ RLR_ElkOBJ3_Length : 25|9@0+ (0.0500000000,0.0000000000) [0.0000000000|25.5000000000] "m"  LAS
 SG_ RLR_ElkOBJ3_Height : 18|9@0+ (0.0100000000,0.0000000000) [0.0000000000|5.1100000000] "m"  LAS
 SG_ RLR_ElkOBJ3_Width : 13|11@0+ (0.0100000000,0.0000000000) [0.0000000000|12.0000000000] "m"  LAS
 SG_ RLR_ElkOBJ3_Type : 0|3@0+ (1.0000000000,0.0000000000) [0.0000000000|7.0000000000] ""  LAS
 SG_ RLR_ElkOBJ3_Track_ID : 7|7@0+ (1.0000000000,0.0000000000) [0.0000000000|127.0000000000] ""  LAS

BO_ 1304 GW_518: 8 GW
 SG_ BCM_CarMode : 11|2@0+ (1.0000000000,0.0000000000) [0.0000000000|3.0000000000] ""  ACC,LAS,APA

BO_ 686 GW_2AE: 8 GW
 SG_ LCDAL_SystemStatus : 6|3@0+ (1.0000000000,0.0000000000) [0.0000000000|7.0000000000] ""  LAS

BO_ 985 LAS_3D9: 64 LAS
 SG_ ACC_ObsTarget10ID : 306|5@0+ (1.0000000000,0.0000000000) [0.0000000000|31.0000000000] ""  GW
 SG_ ACC_ObsTarget10Type : 309|3@0+ (1.0000000000,0.0000000000) [0.0000000000|7.0000000000] ""  GW
 SG_ ACC_ObsTarget10LatRange : 303|10@0+ (0.1000000000,-50.0000000000) [-50.0000000000|50.0000000000] "m"  GW
 SG_ ACC_ObsTarget10LngRange : 282|11@0+ (0.1000000000,-20.0000000000) [-20.0000000000|120.0000000000] "m"  GW
 SG_ ACC_ObsTarget9ID : 287|5@0+ (1.0000000000,0.0000000000) [0.0000000000|31.0000000000] ""  GW
 SG_ ACC_ObsTarget9Type : 274|3@0+ (1.0000000000,0.0000000000) [0.0000000000|7.0000000000] ""  GW
 SG_ ACC_ObsTarget9LatRange : 268|10@0+ (0.1000000000,-50.0000000000) [-50.0000000000|50.0000000000] "m"  GW
 SG_ ACC_ObsTarget9LngRange : 263|11@0+ (0.1000000000,-20.0000000000) [-20.0000000000|120.0000000000] "m"  GW
 SG_ ACC_ObsTarget8ID : 242|5@0+ (1.0000000000,0.0000000000) [0.0000000000|31.0000000000] ""  GW
 SG_ ACC_ObsTarget8Type : 245|3@0+ (1.0000000000,0.0000000000) [0.0000000000|7.0000000000] ""  GW
 SG_ ACC_ObsTarget8LatRange : 239|10@0+ (0.1000000000,-50.0000000000) [-50.0000000000|50.0000000000] "m"  GW
 SG_ ACC_ObsTarget8LngRange : 218|11@0+ (0.1000000000,-20.0000000000) [-20.0000000000|120.0000000000] "m"  GW
 SG_ ACC_ObsTarget7ID : 223|5@0+ (1.0000000000,0.0000000000) [0.0000000000|31.0000000000] ""  GW
 SG_ ACC_ObsTarget7Type : 210|3@0+ (1.0000000000,0.0000000000) [0.0000000000|7.0000000000] ""  GW
 SG_ ACC_ObsTarget7LatRange : 204|10@0+ (0.1000000000,-50.0000000000) [-50.0000000000|50.0000000000] "m"  GW
 SG_ ACC_ObsTarget7LngRange : 199|11@0+ (0.1000000000,-20.0000000000) [-20.0000000000|120.0000000000] "m"  GW
 SG_ ACC_ObsTarget6ID : 178|5@0+ (1.0000000000,0.0000000000) [0.0000000000|31.0000000000] ""  GW
 SG_ ACC_ObsTarget6Type : 181|3@0+ (1.0000000000,0.0000000000) [0.0000000000|7.0000000000] ""  GW
 SG_ ACC_ObsTarget6LatRange : 175|10@0+ (0.1000000000,-50.0000000000) [-50.0000000000|50.0000000000] "m"  GW
 SG_ ACC_ObsTarget6LngRange : 154|11@0+ (0.1000000000,-20.0000000000) [-20.0000000000|120.0000000000] "m"  GW
 SG_ ACC_ObsTarget5ID : 159|5@0+ (1.0000000000,0.0000000000) [0.0000000000|31.0000000000] ""  GW
 SG_ ACC_ObsTarget5Type : 146|3@0+ (1.0000000000,0.0000000000) [0.0000000000|7.0000000000] ""  GW
 SG_ ACC_ObsTarget5LatRange : 140|10@0+ (0.1000000000,-50.0000000000) [-50.0000000000|50.0000000000] "m"  GW
 SG_ ACC_ObsTarget5LngRange : 135|11@0+ (0.1000000000,-20.0000000000) [-20.0000000000|120.0000000000] "m"  GW
 SG_ ACC_ObsTarget4ID : 114|5@0+ (1.0000000000,0.0000000000) [0.0000000000|31.0000000000] ""  GW
 SG_ ACC_ObsTarget4Type : 117|3@0+ (1.0000000000,0.0000000000) [0.0000000000|7.0000000000] ""  GW
 SG_ ACC_ObsTarget4LatRange : 111|10@0+ (0.1000000000,-50.0000000000) [-50.0000000000|50.0000000000] "m"  GW
 SG_ ACC_ObsTarget4LngRange : 90|11@0+ (0.1000000000,-20.0000000000) [-20.0000000000|120.0000000000] "m"  GW
 SG_ ACC_ObsTarget3ID : 95|5@0+ (1.0000000000,0.0000000000) [0.0000000000|31.0000000000] ""  GW
 SG_ ACC_ObsTarget3Type : 82|3@0+ (1.0000000000,0.0000000000) [0.0000000000|7.0000000000] ""  GW
 SG_ ACC_ObsTarget3LatRange : 76|10@0+ (0.1000000000,-50.0000000000) [-50.0000000000|50.0000000000] "m"  GW
 SG_ ACC_ObsTarget3LngRange : 71|11@0+ (0.1000000000,-20.0000000000) [-20.0000000000|120.0000000000] "m"  GW
 SG_ ACC_ObsTarget2ID : 50|5@0+ (1.0000000000,0.0000000000) [0.0000000000|31.0000000000] ""  GW
 SG_ ACC_ObsTarget2Type : 53|3@0+ (1.0000000000,0.0000000000) [0.0000000000|7.0000000000] ""  GW
 SG_ ACC_ObsTarget2LatRange : 47|10@0+ (0.1000000000,-50.0000000000) [-50.0000000000|50.0000000000] "m"  GW
 SG_ ACC_ObsTarget2LngRange : 26|11@0+ (0.1000000000,-20.0000000000) [-20.0000000000|120.0000000000] "m"  GW
 SG_ ACC_ObsTarget1ID : 31|5@0+ (1.0000000000,0.0000000000) [0.0000000000|31.0000000000] ""  GW
 SG_ ACC_ObsTarget1Type : 18|3@0+ (1.0000000000,0.0000000000) [0.0000000000|7.0000000000] ""  GW
 SG_ ACC_ObsTarget1LatRange : 12|10@0+ (0.1000000000,-50.0000000000) [-50.0000000000|50.0000000000] "m"  GW
 SG_ ACC_ObsTarget1LngRange : 7|11@0+ (0.1000000000,-20.0000000000) [-20.0000000000|120.0000000000] "m"  GW

BO_ 987 LAS_3DB: 64 LAS
 SG_ ACC_ObsTarget20ID : 306|5@0+ (1.0000000000,0.0000000000) [0.0000000000|31.0000000000] ""  GW
 SG_ ACC_ObsTarget20Type : 309|3@0+ (1.0000000000,0.0000000000) [0.0000000000|7.0000000000] ""  GW
 SG_ ACC_ObsTarget20LatRange : 303|10@0+ (0.1000000000,-50.0000000000) [-50.0000000000|50.0000000000] "m"  GW
 SG_ ACC_ObsTarget20LngRange : 282|11@0+ (0.1000000000,-20.0000000000) [-20.0000000000|120.0000000000] "m"  GW
 SG_ ACC_ObsTarget19ID : 287|5@0+ (1.0000000000,0.0000000000) [0.0000000000|31.0000000000] ""  GW
 SG_ ACC_ObsTarget19Type : 274|3@0+ (1.0000000000,0.0000000000) [0.0000000000|7.0000000000] ""  GW
 SG_ ACC_ObsTarget19LatRange : 268|10@0+ (0.1000000000,-50.0000000000) [-50.0000000000|50.0000000000] "m"  GW
 SG_ ACC_ObsTarget19LngRange : 263|11@0+ (0.1000000000,-20.0000000000) [-20.0000000000|120.0000000000] "m"  GW
 SG_ ACC_ObsTarget18ID : 242|5@0+ (1.0000000000,0.0000000000) [0.0000000000|31.0000000000] ""  GW
 SG_ ACC_ObsTarget18Type : 245|3@0+ (1.0000000000,0.0000000000) [0.0000000000|7.0000000000] ""  GW
 SG_ ACC_ObsTarget18LatRange : 239|10@0+ (0.1000000000,-50.0000000000) [-50.0000000000|50.0000000000] "m"  GW
 SG_ ACC_ObsTarget18LngRange : 218|11@0+ (0.1000000000,-20.0000000000) [-20.0000000000|120.0000000000] "m"  GW
 SG_ ACC_ObsTarget17ID : 223|5@0+ (1.0000000000,0.0000000000) [0.0000000000|31.0000000000] ""  GW
 SG_ ACC_ObsTarget17Type : 210|3@0+ (1.0000000000,0.0000000000) [0.0000000000|7.0000000000] ""  GW
 SG_ ACC_ObsTarget17LatRange : 204|10@0+ (0.1000000000,-50.0000000000) [-50.0000000000|50.0000000000] "m"  GW
 SG_ ACC_ObsTarget17LngRange : 199|11@0+ (0.1000000000,-20.0000000000) [-20.0000000000|120.0000000000] "m"  GW
 SG_ ACC_ObsTarget16ID : 178|5@0+ (1.0000000000,0.0000000000) [0.0000000000|31.0000000000] ""  GW
 SG_ ACC_ObsTarget16Type : 181|3@0+ (1.0000000000,0.0000000000) [0.0000000000|7.0000000000] ""  GW
 SG_ ACC_ObsTarget16LatRange : 175|10@0+ (0.1000000000,-50.0000000000) [-50.0000000000|50.0000000000] "m"  GW
 SG_ ACC_ObsTarget16LngRange : 154|11@0+ (0.1000000000,-20.0000000000) [-20.0000000000|120.0000000000] "m"  GW
 SG_ ACC_ObsTarget15ID : 159|5@0+ (1.0000000000,0.0000000000) [0.0000000000|31.0000000000] ""  GW
 SG_ ACC_ObsTarget15Type : 146|3@0+ (1.0000000000,0.0000000000) [0.0000000000|7.0000000000] ""  GW
 SG_ ACC_ObsTarget15LatRange : 140|10@0+ (0.1000000000,-50.0000000000) [-50.0000000000|50.0000000000] "m"  GW
 SG_ ACC_ObsTarget15LngRange : 135|11@0+ (0.1000000000,-20.0000000000) [-20.0000000000|120.0000000000] "m"  GW
 SG_ ACC_ObsTarget14ID : 114|5@0+ (1.0000000000,0.0000000000) [0.0000000000|31.0000000000] ""  GW
 SG_ ACC_ObsTarget14Type : 117|3@0+ (1.0000000000,0.0000000000) [0.0000000000|7.0000000000] ""  GW
 SG_ ACC_ObsTarget14LatRange : 111|10@0+ (0.1000000000,-50.0000000000) [-50.0000000000|50.0000000000] "m"  GW
 SG_ ACC_ObsTarget14LngRange : 90|11@0+ (0.1000000000,-20.0000000000) [-20.0000000000|120.0000000000] "m"  GW
 SG_ ACC_ObsTarget13ID : 95|5@0+ (1.0000000000,0.0000000000) [0.0000000000|31.0000000000] ""  GW
 SG_ ACC_ObsTarget13Type : 82|3@0+ (1.0000000000,0.0000000000) [0.0000000000|7.0000000000] ""  GW
 SG_ ACC_ObsTarget13LatRange : 76|10@0+ (0.1000000000,-50.0000000000) [-50.0000000000|50.0000000000] "m"  GW
 SG_ ACC_ObsTarget13LngRange : 71|11@0+ (0.1000000000,-20.0000000000) [-20.0000000000|120.0000000000] "m"  GW
 SG_ ACC_ObsTarget12ID : 50|5@0+ (1.0000000000,0.0000000000) [0.0000000000|31.0000000000] ""  GW
 SG_ ACC_ObsTarget12Type : 53|3@0+ (1.0000000000,0.0000000000) [0.0000000000|7.0000000000] ""  GW
 SG_ ACC_ObsTarget12LatRange : 47|10@0+ (0.1000000000,-50.0000000000) [-50.0000000000|50.0000000000] "m"  GW
 SG_ ACC_ObsTarget12LngRange : 26|11@0+ (0.1000000000,-20.0000000000) [-20.0000000000|120.0000000000] "m"  GW
 SG_ ACC_ObsTarget11ID : 31|5@0+ (1.0000000000,0.0000000000) [0.0000000000|31.0000000000] ""  GW
 SG_ ACC_ObsTarget11Type : 18|3@0+ (1.0000000000,0.0000000000) [0.0000000000|7.0000000000] ""  GW
 SG_ ACC_ObsTarget11LatRange : 12|10@0+ (0.1000000000,-50.0000000000) [-50.0000000000|50.0000000000] "m"  GW
 SG_ ACC_ObsTarget11LngRange : 7|11@0+ (0.1000000000,-20.0000000000) [-20.0000000000|120.0000000000] "m"  GW

BO_ 881 GW_371: 8 GW
 SG_ PCU_DrvMod2 : 31|3@0+ (1.0000000000,0.0000000000) [0.0000000000|7.0000000000] ""  ACC,LAS,mADC
 SG_ PCU_SpecialModeSetFB : 25|3@0+ (1.0000000000,0.0000000000) [0.0000000000|7.0000000000] ""  ACC,LAS,APA

BO_ 796 GW_31C: 8 GW
 SG_ PCU_VcuRdySts : 16|1@0+ (1.0000000000,0.0000000000) [0.0000000000|1.0000000000] ""  APA,ACC,LAS,mADC
 SG_ PCU_PowerOutputSts : 19|3@0+ (1.0000000000,0.0000000000) [0.0000000000|7.0000000000] ""  ACC,LAS

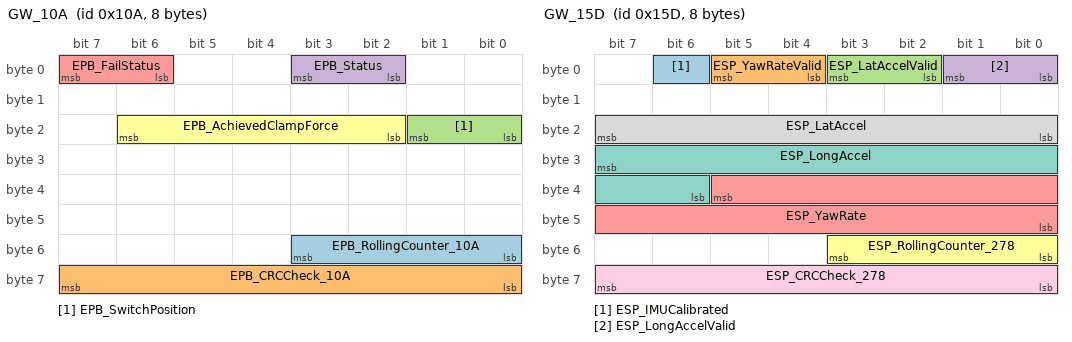
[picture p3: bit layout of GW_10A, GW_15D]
BO_ 266 GW_10A: 8 GW
 SG_ EPB_RollingCounter_10A : 51|4@0+ (1.0000000000,0.0000000000) [0.0000000000|15.0000000000] ""  mADC,ACC,APA,LAS
 SG_ EPB_CRCCheck_10A : 63|8@0+ (1.0000000000,0.0000000000) [0.0000000000|255.0000000000] ""  mADC,ACC,APA,LAS
 SG_ EPB_SwitchPosition : 17|2@0+ (1.0000000000,0.0000000000) [0.0000000000|3.0000000000] ""  ACC,LAS,APA,mADC
 SG_ EPB_Status : 3|2@0+ (1.0000000000,0.0000000000) [0.0000000000|3.0000000000] ""  ACC,LAS,APA,mADC
 SG_ EPB_FailStatus : 7|2@0+ (1.0000000000,0.0000000000) [0.0000000000|3.0000000000] ""  ACC,LAS,APA,mADC
 SG_ EPB_AchievedClampForce : 22|5@0+ (1.0000000000,0.0000000000) [0.0000000000|31.0000000000] "KN"  ACC,LAS,APA,mADC

BO_ 879 LAS_36F: 64 LAS
 SG_ LAS_OverspeedWarningRatioOffset_EU : 397|6@0+ (0.5000000000,-3.0000000000) [-3.0000000000|63.0000000000] "%"  ACC,mADC,GW
 SG_ LAS_TSRSpeedLimitChangeSoundEnSt : 407|2@0+ (1.0000000000,0.0000000000) [0.0000000000|3.0000000000] ""  ACC,mADC,GW
 SG_ LAS_TSRSpeedLimitStatus : 399|2@0+ (1.0000000000,0.0000000000) [0.0000000000|3.0000000000] ""  ACC,mADC,GW
 SG_ LAS_TSRNavCountryCode : 391|8@0+ (1.0000000000,0.0000000000) [0.0000000000|255.0000000000] ""  ACC,mADC,GW

BO_ 349 GW_15D: 8 GW
 SG_ ESP_IMUCalibrated : 6|1@0+ (1.0000000000,0.0000000000) [0.0000000000|1.0000000000] ""  ACC,LAS,mADC
 SG_ ESP_YawRateValid : 5|2@0+ (1.0000000000,0.0000000000) [0.0000000000|3.0000000000] ""  ACC,LAS,mADC
 SG_ ESP_LatAccelValid : 3|2@0+ (1.0000000000,0.0000000000) [0.0000000000|3.0000000000] ""  ACC,LAS,mADC
 SG_ ESP_LongAccelValid : 1|2@0+ (1.0000000000,0.0000000000) [0.0000000000|3.0000000000] ""  ACC,LAS,mADC
 SG_ ESP_YawRate : 37|14@0+ (0.0100000000,-81.9100000000) [-81.9100000000|81.9100000000] "degree/s"  ACC,LAS,mADC
 SG_ ESP_RollingCounter_278 : 51|4@0+ (1.0000000000,0.0000000000) [0.0000000000|15.0000000000] ""  ACC,LAS,mADC
 SG_ ESP_LongAccel : 31|10@0+ (0.0312500000,-16.0000000000) [-16.0000000000|15.9062500000] "m/s2"  ACC,LAS,mADC
 SG_ ESP_LatAccel : 23|8@0+ (0.1000000000,-12.7000000000) [-12.7000000000|12.7000000000] "m/s2"  ACC,LAS,mADC
 SG_ ESP_CRCCheck_278 : 63|8@0+ (1.0000000000,0.0000000000) [0.0000000000|255.0000000000] ""  ACC,LAS,mADC

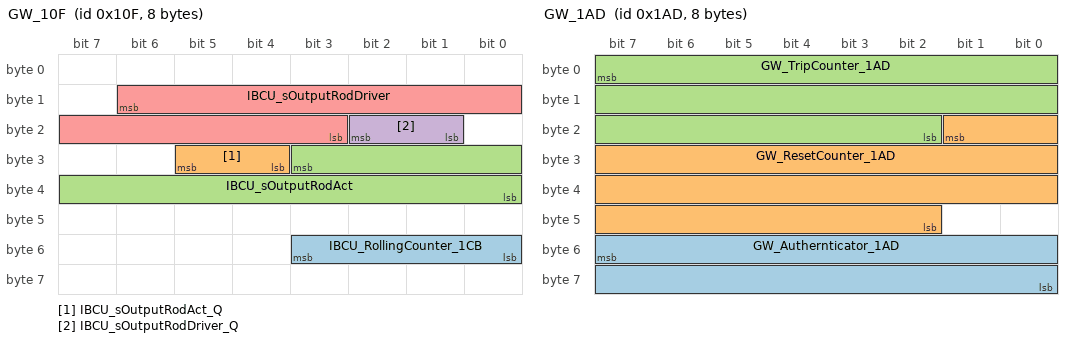
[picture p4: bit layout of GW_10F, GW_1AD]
BO_ 271 GW_10F: 8 GW
 SG_ IBCU_RollingCounter_1CB : 51|4@0+ (1.0000000000,0.0000000000) [0.0000000000|15.0000000000] ""  ACC,LAS,mADC
 SG_ IBCU_sOutputRodAct_Q : 29|2@0+ (1.0000000000,0.0000000000) [0.0000000000|3.0000000000] ""  ACC,LAS,mADC
 SG_ IBCU_sOutputRodAct : 27|12@0+ (0.0156250000,-5.0000000000) [-5.0000000000|47.0000000000] "mm"  ACC,LAS,mADC
 SG_ IBCU_sOutputRodDriver_Q : 18|2@0+ (1.0000000000,0.0000000000) [0.0000000000|2.0000000000] ""  ACC,LAS
 SG_ IBCU_sOutputRodDriver : 14|12@0+ (0.0156250000,-5.0000000000) [-5.0000000000|47.0000000000] "mm"  ACC,LAS

BO_ 810 GW_32A: 8 GW
 SG_ TRM_ConnectSts : 52|1@0+ (1.0000000000,0.0000000000) [0.0000000000|1.0000000000] ""  ACC,LAS,mADC

BO_ 1323 ACC_52B: 64 ACC
 SG_ ACC_Target1LatRelSpeed : 301|10@0+ (0.1250000000,-64.0000000000) [-64.0000000000|63.8750000000] "m/s"  LAS,mADC,GW

BO_ 1330 ACC_532: 64 ACC
 SG_ ACC_Target2LatRelSpeed : 302|10@0+ (0.1250000000,-64.0000000000) [-64.0000000000|63.8750000000] "m/s"  LAS,mADC,GW

BO_ 1331 ACC_533: 64 ACC
 SG_ ADS_IACC_LatTakeOverReason : 473|4@0+ (1.0000000000,0.0000000000) [0.0000000000|15.0000000000] ""  LAS,mADC,GW
 SG_ ACC_RLaneQuality : 479|6@0+ (0.0156250000,0.0000000000) [0.0000000000|0.9843750000] ""  LAS,mADC,GW
 SG_ ACC_DOSECountDown : 469|5@0+ (1.0000000000,0.0000000000) [0.0000000000|31.0000000000] ""  LAS,mADC,GW
 SG_ ACC_Target7LatRelSpeed : 263|10@0+ (0.1250000000,-64.0000000000) [-64.0000000000|63.8750000000] "m/s"  LAS,mADC,GW
 SG_ ACC_Target6LatRelSpeed : 208|10@0+ (0.1250000000,-64.0000000000) [-64.0000000000|63.8750000000] "m/s"  LAS,mADC,GW
 SG_ ACC_Target5LatRelSpeed : 199|10@0+ (0.1250000000,-64.0000000000) [-64.0000000000|63.8750000000] "m/s"  LAS,mADC,GW
 SG_ ACC_Target4LatRelSpeed : 146|10@0+ (0.1250000000,-64.0000000000) [-64.0000000000|63.8750000000] "m/s"  LAS,mADC,GW
 SG_ ACC_Target3LatRelSpeed : 109|10@0+ (0.1250000000,-64.0000000000) [-64.0000000000|63.8750000000] "m/s"  LAS,mADC,GW

BO_ 429 GW_1AD: 8 GW
 SG_ GW_Authernticator_1AD : 55|16@0+ (1.0000000000,0.0000000000) [0.0000000000|65535.0000000000] ""  BDC,ACC,LAS,mADC
 SG_ GW_ResetCounter_1AD : 17|24@0+ (1.0000000000,0.0000000000) [0.0000000000|16777215.0000000000] ""  BDC,ACC,LAS,mADC
 SG_ GW_TripCounter_1AD : 7|22@0+ (1.0000000000,0.0000000000) [0.0000000000|4194303.0000000000] ""  BDC,ACC,LAS,mADC

BO_ 375 LAS_177: 8 LAS
 SG_ LAS_ReqSYNMSG : 1|2@0+ (1.0000000000,0.0000000000) [0.0000000000|3.0000000000] ""  GW

BO_ 1488 GW_5D0: 8 GW
 SG_ KeyLearn_Authernticator_5D0 : 39|32@0+ (1.0000000000,0.0000000000) [1.0000000000|4294967296.0000000000] ""  LAS
 SG_ KeyLearn_Random_5D0 : 7|32@0+ (1.0000000000,0.0000000000) [1.0000000000|4294967296.0000000000] ""  LAS

BO_ 1492 LAS_5D4: 8 LAS
 SG_ KeyLearn_Authernticator_5D4 : 39|32@0+ (1.0000000000,0.0000000000) [1.0000000000|4294967296.0000000000] ""  GW
 SG_ KeyLearn_Random_5D4 : 7|32@0+ (1.0000000000,0.0000000000) [1.0000000000|4294967296.0000000000] ""  GW

BO_ 2015 GW_7DF: 8 GW
 SG_ Diagnose_message7DF : 0|1@0+ (1.0000000000,0.0000000000) [1.0000000000|1.0000000000] ""  ACC,LAS,mADC,APA,MDC,PBOX

BO_ 1891 GW_763: 64 GW
 SG_ Diagnose_message763 : 0|1@0+ (1.0000000000,0.0000000000) [1.0000000000|1.0000000000] ""  LAS

BO_ 1899 LAS_76B: 8 LAS
 SG_ Diagnose_message76B : 0|1@0+ (1.0000000000,0.0000000000) [1.0000000000|1.0000000000] ""  GW

BO_ 583 BDC_247: 32 BDC
 SG_ APA_APAOnOff : 6|1@0+ (1.0000000000,0.0000000000) [0.0000000000|1.0000000000] ""  APA,GW,ACC,LAS,mADC

BO_ 710 BDC_2C6: 64 BDC
 SG_ APA_vehicleFrontdetect : 99|2@0+ (1.0000000000,0.0000000000) [0.0000000000|3.0000000000] ""  GW,LAS,ACC,APA

BO_ 953 GW_3B9: 8 GW
 SG_ BDC_TurnLightSw : 61|3@0+ (1.0000000000,1.0000000000) [0.0000000000|7.0000000000] "1"  APA,LAS,ACC,mADC

BO_ 901 GW_385: 8 GW
 SG_ HU_CDCUnitSystSetStatus : 59|2@0+ (1.0000000000,0.0000000000) [0.0000000000|2.0000000000] ""  ACC,LAS,mADC

BO_ 456 GW_1C8: 8 GW
 SG_ ESP_EngTorqIncRearActive : 8|1@0+ (1.0000000000,0.0000000000) [0.0000000000|1.0000000000] ""  LAS,ACC

CM_ BO_ 943  " ";
CM_ SG_ 943 HU_MaxNavSpeed  " ";
CM_ SG_ 943 HU_MapStatus  " ";
CM_ SG_ 943 HU_ADAS_Posn_Offset  " ";
CM_ SG_ 943 HU_ADAS_Posn_Pathldx  " ";
CM_ SG_ 943 HU_LaneConfluenceDis  " ";
CM_ SG_ 943 HU_LaneConfluence  " ";
CM_ SG_ 943 HU_IntervalVelocityDis  " ";
CM_ SG_ 943 HU_IntervalVelocityInfo  " ";

CM_ BO_ 947  " ";

CM_ BO_ 957  " ";
CM_ SG_ 957 HU_SentryModeSt  " ";
CM_ SG_ 957 HU_CSLAEnable  "ACC 主控则ACC接收，LAS 主控则LAS接收 ";
CM_ SG_ 957 HU_TLAEnable  " ";

CM_ BO_ 964  " ";
CM_ SG_ 964 HU_CRCCheck_3C7  " ";
CM_ SG_ 964 HU_RollingCounter_3C7  " ";
CM_ SG_ 964 HU_CRCCheck_3C6  " ";
CM_ SG_ 964 HU_RollingCounter_3C6  " ";
CM_ SG_ 964 HU_CRCCheck_3C4_2  " ";
CM_ SG_ 964 HU_RollingCounter_3C4_2  " ";
CM_ SG_ 964 HU_CRCCheck_3C2  " ";
CM_ SG_ 964 HU_RollingCounter_3C2  " ";
CM_ SG_ 964 HU_MapDataUpdateStatus  " ";
CM_ SG_ 964 HU_RoadCurvature_600m  " ";
CM_ SG_ 964 HU_RoadCurvature_400m  " ";
CM_ SG_ 964 HU_RoadCurvature_300m  " ";
CM_ SG_ 964 HU_RoadCurvature_100m  " ";
CM_ SG_ 964 HU_RoadCurvature_90m  " ";
CM_ SG_ 964 HU_RoadCurvature_80m  " ";
CM_ SG_ 964 HU_RoadCurvature_70m  " ";
CM_ SG_ 964 HU_RoadCurvature_60m  " ";
CM_ SG_ 964 HU_RoadCurvature_50m  " ";
CM_ SG_ 964 HU_RoadCurvature_40m  " ";
CM_ SG_ 964 HU_RoadCurvature_30m  " ";
CM_ SG_ 964 HU_RoadCurvature_20m  " ";
CM_ SG_ 964 HU_RoadCurvature_10m  " ";
CM_ SG_ 964 HU_Road_TrafficFlow  " ";
CM_ SG_ 964 HU_To_Construction_Dis  " ";
CM_ SG_ 964 HU_Construction_Info  " ";
CM_ SG_ 964 HU_RampSide  " ";

CM_ BO_ 1021  " ";
CM_ SG_ 1021 BCM_DriveMode  "ACC 主控则ACC接收，LAS 主控则LAS接收 ";

CM_ BO_ 1023  " ";

CM_ BO_ 1310  " ";
CM_ SG_ 1310 TPMS_TirePosition  "GW报文转发 ";

CM_ BO_ 1684  " ";
CM_ SG_ 1684 LAS_DTC2_Status  "DTC上传 ";
CM_ SG_ 1684 LAS_DTC2_LowByte  "DTC上传 ";
CM_ SG_ 1684 LAS_DTC2_MiddByte  "DTC上传 ";
CM_ SG_ 1684 LAS_DTC2_HighByte  "DTC上传 ";
CM_ SG_ 1684 LAS_DTC1_Status  "DTC上传 ";
CM_ SG_ 1684 LAS_DTC1_LowByte  "DTC上传 ";
CM_ SG_ 1684 LAS_DTC1_MiddByte  "DTC上传 ";
CM_ SG_ 1684 LAS_DTC1_HighByte  "DTC上传 ";

CM_ BO_ 1106  "Diag--VDC--ADAS1 ";

CM_ BO_ 652  "GW自发MFS_LIN_2 ";
CM_ SG_ 652 GW_MFS_CRCCheck_28C  "GW对LIN的CRC重新计算并发出 ";

CM_ BO_ 817  " ";
CM_ SG_ 817 TCU_TransFaultLevel  "1、Normal= transmission works will;Fault level1(just store DTC)=Transmission some functions are fault but don't need to inform the driver;Fault level2(store DTC&warning)=Transmission some functions are fault and it should inform the driver;Fault level3(Limphome)=Transmission some functions are fault and will limit the torque;Fault level4(No DCT Shaft)= Transmission some functions are fault and it will lead to freeze shaft; Fault level5(Drive open)；Transmission fully broken and it will lead clutchs fully open.
2、P2特有
3、APA配置接收方无BDC ";

CM_ BO_ 431  " ";
CM_ SG_ 431 TCU_ShiftPostionValid  "APA配置接收方无BDC ";
CM_ SG_ 431 TCU_ShiftInProgressVld  " ";
CM_ SG_ 431 TCU_ShiftInProgress  " ";
CM_ SG_ 431 TCU_GearShiftPosition  "TCU receives driver demands gear from ESL and make decisition of actual drive mode based on current vehicle/transmission status.
PCU receives this signals to understand actual drive mode and estimate target gear ";
CM_ SG_ 431 TCU_CRCCheck_1A8  "CRCCheck_SAE_J1850_2001,multinomial is X8+X4+X3+X2+1 ";
CM_ SG_ 431 TCU_ActualDrivingGearValid  "APA配置接收方无BDC ";
CM_ SG_ 431 TCU_ActualDrivingGear  "RMU法规要求
Message relaying what the current engaged gear is (On DCT this will also be the gear on the shaft with the engaged clutch). ";

CM_ BO_ 800  "GW自发 ";
CM_ SG_ 800 GW_ResetReq  " ";

CM_ BO_ 922  " ";
CM_ SG_ 922 LAS_TSRRightLaneStatus  "GW报文转发 ";
CM_ SG_ 922 LAS_TSRLeftLaneStatus  "GW报文转发 ";
CM_ SG_ 922 LAS_CRCCheck_3C0  "
 ";
CM_ SG_ 922 LAS_RollingCounter_3C0  "rolling counter ";
CM_ SG_ 922 LAS_TSRRightLaneSpdLimit  "GW报文转发
0x0=no speed limit detected;
0x1=SL5;
0x2=SL10;
…
0x32=SL160;
0x33~0x253= Reserved;
0x254=Unknown;
0x255=SLEND ";
CM_ SG_ 922 LAS_TSRLeftLaneSpdLimit  "GW报文转发
0x0=no speed limit detected;
0x1=SL5;
0x2=SL10;
…
0x32=SL160;
0x33~0x253= Reserved;
0x254=Unknown;
0x255=SLEND ";
CM_ SG_ 922 LAS_CRCCheck_3D4  "
 ";
CM_ SG_ 922 LAS_RollingCounter_3D4  "rolling counter ";
CM_ SG_ 922 LAS_TLAStopLine_HostLane  " ";
CM_ SG_ 922 LAS_TLADistance_HostLane  " ";
CM_ SG_ 922 LAS_TLACountDownTime_HostLane  " ";
CM_ SG_ 922 LAS_TSRMandatorySign  " ";
CM_ SG_ 922 LAS_TSRWarningSign  " ";
CM_ SG_ 922 LAS_TSRProhibitionSign  " ";
CM_ SG_ 922 LAS_CRCCheck_332  "
 ";
CM_ SG_ 922 LAS_RollingCounter_332  "rolling counter ";
CM_ SG_ 922 LAS_HMALightDistribution  "GW报文转发 ";
CM_ SG_ 922 LAS_HMAStatus  "GW报文转发 ";
CM_ SG_ 922 LAS_TSRHostSpdLimitUnits  "GW报文转发 ";
CM_ SG_ 922 LAS_TSRStatus  "GW报文转发 ";
CM_ SG_ 922 LAS_FrontCameraCalibrationStatus  "有LAS时由LAS发送，其余由APA或AVM发送 ";
CM_ SG_ 922 LAS_FrontCameraFailureStatus  "有LAS时由LAS发送，其余由APA或AVM发送 ";
CM_ SG_ 922 LAS_CRCCheck_37D  " ";
CM_ SG_ 922 LAS_RollingCounter_37D  "rolling counter ";
CM_ SG_ 922 LAS_TLAArrowDirection_RightLane  " ";
CM_ SG_ 922 LAS_TLAObjectType_RightLane  " ";
CM_ SG_ 922 LAS_TLAObjectStatus_RightLane  " ";
CM_ SG_ 922 LAS_TLAObjectColour_RightLane  " ";
CM_ SG_ 922 LAS_TLAObjectDetection_RightLane  " ";
CM_ SG_ 922 LAS_TLAArrowDirection_LeftLane  " ";
CM_ SG_ 922 LAS_TLAObjectType_LeftLane  " ";
CM_ SG_ 922 LAS_TLAObjectStatus_LeftLane  " ";
CM_ SG_ 922 LAS_TLAObjectColour_LeftLane  " ";
CM_ SG_ 922 LAS_TLAObjectDetection_LeftLane  " ";
CM_ SG_ 922 LAS_TLAArrowDirection_HostLane  " ";
CM_ SG_ 922 LAS_TLAObjectStatus_HostLane  " ";
CM_ SG_ 922 LAS_TLAObjectType_HostLane  " ";
CM_ SG_ 922 LAS_TLAObjectColour_HostLane  " ";
CM_ SG_ 922 LAS_TLAObjectDetection_HostLane  " ";
CM_ SG_ 922 LAS_TLAWarninglevel  " ";
CM_ SG_ 922 LAS_TLAStatus  " ";
CM_ SG_ 922 LAS_TLAEnable  " ";

CM_ BO_ 784  "源端INFO_AMP_30E,1 ";

CM_ BO_ 1000  " ";
CM_ SG_ 1000 BCM_SOF_Q_STATE  "GW报文转发 ";
CM_ SG_ 1000 BCM_SOF_Q  "GW报文转发 ";

CM_ BO_ 999  " ";
CM_ SG_ 999 BCM_Status_Temp  "GW报文转发 ";
CM_ SG_ 999 BCM_T_BATT  "GW报文转发 ";

CM_ BO_ 906  "GW自发 ";

CM_ BO_ 586  " ";
CM_ SG_ 586 ESL_DriverParkRequest  "TCU接收为DCT专用
ACM接收为AT专用 ";
CM_ SG_ 586 ESL_ShiftLeverPositionrequest  "ACM接收为AT专用
原信号名称ESL_ShiftLeverPositon，CD569、S202DA使用 ";
CM_ SG_ 586 ESL_ShiftLeverPositionFaultSts  "TCU接收为DCT专用
ACM接收为AT专用
原信号名称ESL_ShiftLeverStatus，CD569、S202DA使用 ";

CM_ BO_ 833  "源端HybridA_PCU_33B,1 ";
CM_ SG_ 833 PCU_PwrTqWhMinVld  "ACC 主控则ACC接收，LAS 主控则LAS接收 ";
CM_ SG_ 833 PCU_PwrTqWhMinTotal  "ACC 主控则ACC接收，LAS 主控则LAS接收 ";
CM_ SG_ 833 PCU_PwrTqWhMaxVld  "ACC 主控则ACC接收，LAS 主控则LAS接收 ";
CM_ SG_ 833 PCU_PwrTqWhMaxTotal  "ACC 主控则ACC接收，LAS 主控则LAS接收 ";

CM_ BO_ 866  "源端HybridA_PCU_33B,2 ";
CM_ SG_ 866 PCU_DrvModVld  "ACC 主控则ACC接收，LAS 主控则LAS接收 ";

CM_ BO_ 723  " ";
CM_ SG_ 723 ACC_CRCCheck_283  " ";
CM_ SG_ 723 ACC_RollingCounter_283  " ";
CM_ SG_ 723 ACC_AEBTargetLatRelSpeed_for_SRS  "向左为正，向右为 ";
CM_ SG_ 723 ACC_AEBTargetLatRange_for_SRS  "向左为正，向右为 ";
CM_ SG_ 723 ACC_CRCCheckr_282  " ";
CM_ SG_ 723 ACC_RollingCounter_282  " ";
CM_ SG_ 723 ACC_AEBTargetProb_for_SRS  " ";
CM_ SG_ 723 ACC_AEBTargetType_for_SRS  " ";
CM_ SG_ 723 ACC_AEBTargetTTC_for_SRS  "碰撞时刻为0 ";
CM_ SG_ 723 ACC_AEBTargetRelSpeed_for_SRS  "前方目标比本车快为正，前方目标比本车慢为负 ";
CM_ SG_ 723 ACC_AEBTargetLngRange_for_SRS  "负数代表向后，正数代表向前，原点为前雷达波束发射 ";
CM_ SG_ 723 ACC_AEBActive_for_SRS  " ";
CM_ SG_ 723 ACC_AEBStatus_for_SRS  " ";

CM_ BO_ 780  " ";

CM_ BO_ 738  " ";

CM_ BO_ 739  " ";

CM_ BO_ 1304  " ";
CM_ SG_ 1304 BCM_CarMode  "无效值是为转DBC ";

CM_ BO_ 686  "源端ADASB_RLR/LCDAL_2AD,0 ";
CM_ SG_ 686 LCDAL_SystemStatus  " ";

CM_ BO_ 985  " ";
CM_ SG_ 985 ACC_ObsTarget10ID  "800W摄像头使用 ";
CM_ SG_ 985 ACC_ObsTarget10Type  "800W摄像头使用 ";
CM_ SG_ 985 ACC_ObsTarget10LatRange  "横向距离向左为负，向右为正
800W摄像头使用 ";
CM_ SG_ 985 ACC_ObsTarget10LngRange  "纵向距离向前为正，向后为负
800W摄像头使用 ";
CM_ SG_ 985 ACC_ObsTarget9ID  "800W摄像头使用 ";
CM_ SG_ 985 ACC_ObsTarget9Type  "800W摄像头使用 ";
CM_ SG_ 985 ACC_ObsTarget9LatRange  "横向距离向左为负，向右为正
800W摄像头使用 ";
CM_ SG_ 985 ACC_ObsTarget9LngRange  "纵向距离向前为正，向后为负
800W摄像头使用 ";
CM_ SG_ 985 ACC_ObsTarget8ID  "800W摄像头使用 ";
CM_ SG_ 985 ACC_ObsTarget8Type  "800W摄像头使用 ";
CM_ SG_ 985 ACC_ObsTarget8LatRange  "横向距离向左为负，向右为正
800W摄像头使用 ";
CM_ SG_ 985 ACC_ObsTarget8LngRange  "纵向距离向前为正，向后为负
800W摄像头使用 ";
CM_ SG_ 985 ACC_ObsTarget7ID  "800W摄像头使用 ";
CM_ SG_ 985 ACC_ObsTarget7Type  "800W摄像头使用 ";
CM_ SG_ 985 ACC_ObsTarget7LatRange  "横向距离向左为负，向右为正
800W摄像头使用 ";
CM_ SG_ 985 ACC_ObsTarget7LngRange  "纵向距离向前为正，向后为负
800W摄像头使用 ";
CM_ SG_ 985 ACC_ObsTarget6ID  "800W摄像头使用 ";
CM_ SG_ 985 ACC_ObsTarget6Type  "800W摄像头使用 ";
CM_ SG_ 985 ACC_ObsTarget6LatRange  "横向距离向左为负，向右为正
800W摄像头使用 ";
CM_ SG_ 985 ACC_ObsTarget6LngRange  "纵向距离向前为正，向后为负
800W摄像头使用 ";
CM_ SG_ 985 ACC_ObsTarget5ID  "800W摄像头使用 ";
CM_ SG_ 985 ACC_ObsTarget5Type  "800W摄像头使用 ";
CM_ SG_ 985 ACC_ObsTarget5LatRange  "横向距离向左为负，向右为正
800W摄像头使用 ";
CM_ SG_ 985 ACC_ObsTarget5LngRange  "纵向距离向前为正，向后为负
800W摄像头使用 ";
CM_ SG_ 985 ACC_ObsTarget4ID  "800W摄像头使用 ";
CM_ SG_ 985 ACC_ObsTarget4Type  "800W摄像头使用 ";
CM_ SG_ 985 ACC_ObsTarget4LatRange  "横向距离向左为负，向右为正
800W摄像头使用 ";
CM_ SG_ 985 ACC_ObsTarget4LngRange  "纵向距离向前为正，向后为负
800W摄像头使用 ";
CM_ SG_ 985 ACC_ObsTarget3ID  "800W摄像头使用 ";
CM_ SG_ 985 ACC_ObsTarget3Type  "800W摄像头使用 ";
CM_ SG_ 985 ACC_ObsTarget3LatRange  "横向距离向左为负，向右为正
800W摄像头使用 ";
CM_ SG_ 985 ACC_ObsTarget3LngRange  "纵向距离向前为正，向后为负
800W摄像头使用 ";
CM_ SG_ 985 ACC_ObsTarget2ID  "800W摄像头使用 ";
CM_ SG_ 985 ACC_ObsTarget2Type  "800W摄像头使用 ";
CM_ SG_ 985 ACC_ObsTarget2LatRange  "横向距离向左为负，向右为正
800W摄像头使用 ";
CM_ SG_ 985 ACC_ObsTarget2LngRange  "纵向距离向前为正，向后为负
800W摄像头使用 ";
CM_ SG_ 985 ACC_ObsTarget1ID  "800W摄像头使用 ";
CM_ SG_ 985 ACC_ObsTarget1Type  "800W摄像头使用 ";
CM_ SG_ 985 ACC_ObsTarget1LatRange  "横向距离向左为负，向右为正
800W摄像头使用 ";
CM_ SG_ 985 ACC_ObsTarget1LngRange  "纵向距离向前为正，向后为负
800W摄像头使用 ";

CM_ BO_ 987  " ";
CM_ SG_ 987 ACC_ObsTarget20ID  "800W摄像头使用 ";
CM_ SG_ 987 ACC_ObsTarget20Type  "800W摄像头使用 ";
CM_ SG_ 987 ACC_ObsTarget20LatRange  "横向距离向左为负，向右为正
800W摄像头使用 ";
CM_ SG_ 987 ACC_ObsTarget20LngRange  "纵向距离向前为正，向后为负
800W摄像头使用 ";
CM_ SG_ 987 ACC_ObsTarget19ID  "800W摄像头使用 ";
CM_ SG_ 987 ACC_ObsTarget19Type  "800W摄像头使用 ";
CM_ SG_ 987 ACC_ObsTarget19LatRange  "横向距离向左为负，向右为正
800W摄像头使用 ";
CM_ SG_ 987 ACC_ObsTarget19LngRange  "纵向距离向前为正，向后为负
800W摄像头使用 ";
CM_ SG_ 987 ACC_ObsTarget18ID  "800W摄像头使用 ";
CM_ SG_ 987 ACC_ObsTarget18Type  "800W摄像头使用 ";
CM_ SG_ 987 ACC_ObsTarget18LatRange  "横向距离向左为负，向右为正
800W摄像头使用 ";
CM_ SG_ 987 ACC_ObsTarget18LngRange  "纵向距离向前为正，向后为负
800W摄像头使用 ";
CM_ SG_ 987 ACC_ObsTarget17ID  "800W摄像头使用 ";
CM_ SG_ 987 ACC_ObsTarget17Type  "800W摄像头使用 ";
CM_ SG_ 987 ACC_ObsTarget17LatRange  "横向距离向左为负，向右为正
800W摄像头使用 ";
CM_ SG_ 987 ACC_ObsTarget17LngRange  "纵向距离向前为正，向后为负
800W摄像头使用 ";
CM_ SG_ 987 ACC_ObsTarget16ID  "800W摄像头使用 ";
CM_ SG_ 987 ACC_ObsTarget16Type  "800W摄像头使用 ";
CM_ SG_ 987 ACC_ObsTarget16LatRange  "横向距离向左为负，向右为正
800W摄像头使用 ";
CM_ SG_ 987 ACC_ObsTarget16LngRange  "纵向距离向前为正，向后为负
800W摄像头使用 ";
CM_ SG_ 987 ACC_ObsTarget15ID  "800W摄像头使用 ";
CM_ SG_ 987 ACC_ObsTarget15Type  "800W摄像头使用 ";
CM_ SG_ 987 ACC_ObsTarget15LatRange  "横向距离向左为负，向右为正
800W摄像头使用 ";
CM_ SG_ 987 ACC_ObsTarget15LngRange  "纵向距离向前为正，向后为负
800W摄像头使用 ";
CM_ SG_ 987 ACC_ObsTarget14ID  "800W摄像头使用 ";
CM_ SG_ 987 ACC_ObsTarget14Type  "800W摄像头使用 ";
CM_ SG_ 987 ACC_ObsTarget14LatRange  "横向距离向左为负，向右为正
800W摄像头使用 ";
CM_ SG_ 987 ACC_ObsTarget14LngRange  "纵向距离向前为正，向后为负
800W摄像头使用 ";
CM_ SG_ 987 ACC_ObsTarget13ID  "800W摄像头使用 ";
CM_ SG_ 987 ACC_ObsTarget13Type  "800W摄像头使用 ";
CM_ SG_ 987 ACC_ObsTarget13LatRange  "横向距离向左为负，向右为正
800W摄像头使用 ";
CM_ SG_ 987 ACC_ObsTarget13LngRange  "纵向距离向前为正，向后为负
800W摄像头使用 ";
CM_ SG_ 987 ACC_ObsTarget12ID  "800W摄像头使用 ";
CM_ SG_ 987 ACC_ObsTarget12Type  "800W摄像头使用 ";
CM_ SG_ 987 ACC_ObsTarget12LatRange  "横向距离向左为负，向右为正
800W摄像头使用 ";
CM_ SG_ 987 ACC_ObsTarget12LngRange  "纵向距离向前为正，向后为负
800W摄像头使用 ";
CM_ SG_ 987 ACC_ObsTarget11ID  "800W摄像头使用 ";
CM_ SG_ 987 ACC_ObsTarget11Type  "800W摄像头使用 ";
CM_ SG_ 987 ACC_ObsTarget11LatRange  "横向距离向左为负，向右为正
800W摄像头使用 ";
CM_ SG_ 987 ACC_ObsTarget11LngRange  "纵向距离向前为正，向后为负
800W摄像头使用 ";

CM_ BO_ 881  " ";

CM_ BO_ 796  "源端HybridA_PCU/PDCU_3FC.6 ";
CM_ SG_ 796 PCU_VcuRdySts  "APA配置接收方无BDC ";

CM_ BO_ 266  " ";
CM_ SG_ 266 EPB_RollingCounter_10A  " ";
CM_ SG_ 266 EPB_CRCCheck_10A  " ";
CM_ SG_ 266 EPB_Status  "APA配置接收方无BDC ";
CM_ SG_ 266 EPB_FailStatus  "APA配置接收方无BDC ";

CM_ BO_ 879  " ";

CM_ BO_ 349  " ";
CM_ SG_ 349 ESP_YawRate  "右正左负（举例理解=水平路面向
右转弯时，发正值。反之发负值） ";
CM_ SG_ 349 ESP_LongAccel  "举例理解=水平路面直线加速
时，发正值。反之发负值。 ";
CM_ SG_ 349 ESP_LatAccel  "右正左负（举例理解=水平路面向
右转弯时，发正值。反之发负值） ";

CM_ BO_ 271  "源端CHS_IBCU_1CB,0 ";

CM_ BO_ 810  " ";

CM_ BO_ 1323  " ";
CM_ SG_ 1323 ACC_Target1LatRelSpeed  " ";

CM_ BO_ 1330  " ";
CM_ SG_ 1330 ACC_Target2LatRelSpeed  " ";

CM_ BO_ 1331  " ";
CM_ SG_ 1331 ADS_IACC_LatTakeOverReason  " ";
CM_ SG_ 1331 ACC_RLaneQuality  " ";
CM_ SG_ 1331 ACC_DOSECountDown  " ";
CM_ SG_ 1331 ACC_Target7LatRelSpeed  " ";
CM_ SG_ 1331 ACC_Target6LatRelSpeed  " ";
CM_ SG_ 1331 ACC_Target5LatRelSpeed  " ";
CM_ SG_ 1331 ACC_Target4LatRelSpeed  " ";
CM_ SG_ 1331 ACC_Target3LatRelSpeed  " ";

CM_ BO_ 429  "GW自发 ";

CM_ BO_ 375  " ";
CM_ SG_ 375 LAS_ReqSYNMSG  "见《车端消息认证集成规范》
触发时连续发送3帧，帧间隔50ms ";

CM_ BO_ 1488  "GW与LAS消息认证，电检秘钥学习流程的ID ";
CM_ SG_ 1488 KeyLearn_Authernticator_5D0  "见《车端消息认证集成规范》 ";
CM_ SG_ 1488 KeyLearn_Random_5D0  "见《车端消息认证集成规范》 ";

CM_ BO_ 1492  "GW与LAS消息认证，电检秘钥学习流程的ID ";
CM_ SG_ 1492 KeyLearn_Authernticator_5D4  "见《车端消息认证集成规范》 ";
CM_ SG_ 1492 KeyLearn_Random_5D4  "见《车端消息认证集成规范》 ";

CM_ BO_ 2015  "mADC报文路由至ADASB/ADASC/ADASE ";

CM_ BO_ 1891  "使用CAN诊断仪时发送报文DLC长度为8，使用CANFD诊断仪时发送报文DLC长度为8到64 ";

CM_ BO_ 1899  " ";

CM_ BO_ 583  " ";

CM_ BO_ 710  " ";

CM_ BO_ 953  " ";

CM_ BO_ 901  "源端INFO_IP/THU_3D5,0 ";

CM_ BO_ 456  "源端CHS_IBCU/EPBi_17A,3 ";
CM_ SG_ 456 ESP_EngTorqIncRearActive  " ";

BA_DEF_ SG_  "GenSigStartValue" INT 0 0;
BA_DEF_ SG_  "GenSigInvalidValue" STRING  ;
BA_DEF_ SG_  "GenSigCycleTime" INT 0 0;
BA_DEF_ SG_  "GenSigSendType" ENUM  "Cyclic","OnWrite","OnWriteWithRepetition","OnChange","OnChangeWithRepetition","IfActive","IfActiveWithRepetition","NoSigSendType","NotUsed","NotUsed","NotUsed","NotUsed","NotUsed";
BA_DEF_ BO_  "GenMsgSendType" ENUM  "Cyclic","Event","NotUsed","NotUsed","NotUsed","Cyclic","NotUsed","IfActive","NoMsgSendType","NotUsed";
BA_DEF_ BO_  "GenMsgILSupport" ENUM  "No","Yes";
BA_DEF_ BO_  "GenMsgCycleTime" INT 0 65535;
BA_DEF_ BO_  "CANFD_BRS" ENUM  "0","1";
BA_DEF_ BO_  "VFrameFormat" ENUM  "StandardCAN","ExtendedCAN","reserved","reserved","reserved","reserved","reserved","reserved","reserved","reserved","reserved","reserved","reserved","reserved","StandardCAN_FD","ExtendedCAN_FD";
BA_DEF_DEF_  "GenSigStartValue" 0;
BA_DEF_DEF_  "GenSigInvalidValue" "/";
BA_DEF_DEF_  "GenSigCycleTime" 0;
BA_DEF_DEF_  "GenSigSendType" "Cyclic";
BA_DEF_DEF_  "GenMsgSendType" "NoMsgSendType";
BA_DEF_DEF_  "GenMsgILSupport" "Yes";
BA_DEF_DEF_  "GenMsgCycleTime" 0;
BA_DEF_DEF_  "CANFD_BRS" "1";
BA_DEF_DEF_  "VFrameFormat" "StandardCAN";
BA_ "GenMsgCycleTime" BO_ 943 100;
BA_ "GenMsgSendType" BO_ 943 0;
BA_ "VFrameFormat" BO_ 943 14;
BA_ "GenMsgCycleTime" BO_ 947 100;
BA_ "GenMsgSendType" BO_ 947 0;
BA_ "VFrameFormat" BO_ 947 14;
BA_ "GenMsgCycleTime" BO_ 957 100;
BA_ "GenMsgSendType" BO_ 957 0;
BA_ "VFrameFormat" BO_ 957 14;
BA_ "GenMsgCycleTime" BO_ 964 100;
BA_ "GenMsgSendType" BO_ 964 0;
BA_ "VFrameFormat" BO_ 964 14;
BA_ "GenMsgCycleTime" BO_ 1021 100;
BA_ "GenMsgSendType" BO_ 1021 0;
BA_ "VFrameFormat" BO_ 1021 14;
BA_ "GenMsgCycleTime" BO_ 1023 100;
BA_ "GenMsgSendType" BO_ 1023 0;
BA_ "VFrameFormat" BO_ 1023 14;
BA_ "GenMsgCycleTime" BO_ 1310 500;
BA_ "GenMsgSendType" BO_ 1310 0;
BA_ "VFrameFormat" BO_ 1310 14;
BA_ "GenMsgCycleTime" BO_ 1684 500;
BA_ "GenMsgSendType" BO_ 1684 0;
BA_ "VFrameFormat" BO_ 1684 14;
BA_ "GenMsgSendType" BO_ 1106 1;
BA_ "GenMsgCycleTime" BO_ 652 40;
BA_ "GenMsgSendType" BO_ 652 0;
BA_ "VFrameFormat" BO_ 652 14;
BA_ "GenMsgCycleTime" BO_ 817 100;
BA_ "GenMsgSendType" BO_ 817 0;
BA_ "VFrameFormat" BO_ 817 14;
BA_ "GenMsgCycleTime" BO_ 431 10;
BA_ "GenMsgSendType" BO_ 431 0;
BA_ "VFrameFormat" BO_ 431 14;
BA_ "GenMsgCycleTime" BO_ 800 100;
BA_ "GenMsgSendType" BO_ 800 0;
BA_ "VFrameFormat" BO_ 800 14;
BA_ "GenMsgCycleTime" BO_ 922 100;
BA_ "GenMsgSendType" BO_ 922 0;
BA_ "VFrameFormat" BO_ 922 14;
BA_ "GenMsgCycleTime" BO_ 784 100;
BA_ "GenMsgSendType" BO_ 784 0;
BA_ "VFrameFormat" BO_ 784 14;
BA_ "GenMsgCycleTime" BO_ 1000 100;
BA_ "GenMsgSendType" BO_ 1000 0;
BA_ "VFrameFormat" BO_ 1000 14;
BA_ "GenMsgCycleTime" BO_ 999 100;
BA_ "GenMsgSendType" BO_ 999 0;
BA_ "VFrameFormat" BO_ 999 14;
BA_ "GenMsgCycleTime" BO_ 906 40;
BA_ "GenMsgSendType" BO_ 906 0;
BA_ "VFrameFormat" BO_ 906 14;
BA_ "GenMsgCycleTime" BO_ 586 20;
BA_ "GenMsgSendType" BO_ 586 0;
BA_ "VFrameFormat" BO_ 586 14;
BA_ "GenMsgCycleTime" BO_ 833 100;
BA_ "GenMsgSendType" BO_ 833 0;
BA_ "VFrameFormat" BO_ 833 14;
BA_ "GenMsgCycleTime" BO_ 866 100;
BA_ "GenMsgSendType" BO_ 866 0;
BA_ "VFrameFormat" BO_ 866 14;
BA_ "GenMsgCycleTime" BO_ 723 40;
BA_ "GenMsgSendType" BO_ 723 0;
BA_ "VFrameFormat" BO_ 723 14;
BA_ "GenMsgCycleTime" BO_ 780 100;
BA_ "GenMsgSendType" BO_ 780 0;
BA_ "VFrameFormat" BO_ 780 14;
BA_ "GenMsgCycleTime" BO_ 738 50;
BA_ "GenMsgSendType" BO_ 738 0;
BA_ "VFrameFormat" BO_ 738 14;
BA_ "GenMsgCycleTime" BO_ 739 50;
BA_ "GenMsgSendType" BO_ 739 0;
BA_ "VFrameFormat" BO_ 739 14;
BA_ "GenMsgCycleTime" BO_ 1304 500;
BA_ "GenMsgSendType" BO_ 1304 0;
BA_ "VFrameFormat" BO_ 1304 14;
BA_ "GenMsgCycleTime" BO_ 686 50;
BA_ "GenMsgSendType" BO_ 686 0;
BA_ "VFrameFormat" BO_ 686 14;
BA_ "GenMsgCycleTime" BO_ 985 100;
BA_ "GenMsgSendType" BO_ 985 0;
BA_ "VFrameFormat" BO_ 985 14;
BA_ "GenMsgCycleTime" BO_ 987 100;
BA_ "GenMsgSendType" BO_ 987 0;
BA_ "VFrameFormat" BO_ 987 14;
BA_ "GenMsgCycleTime" BO_ 881 100;
BA_ "GenMsgSendType" BO_ 881 0;
BA_ "VFrameFormat" BO_ 881 14;
BA_ "GenMsgCycleTime" BO_ 796 100;
BA_ "GenMsgSendType" BO_ 796 0;
BA_ "VFrameFormat" BO_ 796 14;
BA_ "GenMsgCycleTime" BO_ 266 10;
BA_ "GenMsgSendType" BO_ 266 0;
BA_ "VFrameFormat" BO_ 266 14;
BA_ "GenMsgCycleTime" BO_ 879 100;
BA_ "GenMsgSendType" BO_ 879 0;
BA_ "VFrameFormat" BO_ 879 14;
BA_ "GenMsgCycleTime" BO_ 349 20;
BA_ "GenMsgSendType" BO_ 349 0;
BA_ "VFrameFormat" BO_ 349 14;
BA_ "GenMsgCycleTime" BO_ 271 20;
BA_ "GenMsgSendType" BO_ 271 0;
BA_ "VFrameFormat" BO_ 271 14;
BA_ "GenMsgCycleTime" BO_ 810 100;
BA_ "GenMsgSendType" BO_ 810 0;
BA_ "VFrameFormat" BO_ 810 14;
BA_ "GenMsgCycleTime" BO_ 1323 100;
BA_ "GenMsgSendType" BO_ 1323 0;
BA_ "VFrameFormat" BO_ 1323 14;
BA_ "GenMsgCycleTime" BO_ 1330 100;
BA_ "GenMsgSendType" BO_ 1330 0;
BA_ "VFrameFormat" BO_ 1330 14;
BA_ "GenMsgCycleTime" BO_ 1331 100;
BA_ "GenMsgSendType" BO_ 1331 0;
BA_ "VFrameFormat" BO_ 1331 14;
BA_ "GenMsgSendType" BO_ 429 1;
BA_ "VFrameFormat" BO_ 429 14;
BA_ "GenMsgSendType" BO_ 375 1;
BA_ "VFrameFormat" BO_ 375 14;
BA_ "GenMsgSendType" BO_ 1488 1;
BA_ "VFrameFormat" BO_ 1488 14;
BA_ "GenMsgSendType" BO_ 1492 1;
BA_ "VFrameFormat" BO_ 1492 14;
BA_ "GenMsgSendType" BO_ 2015 1;
BA_ "VFrameFormat" BO_ 2015 14;
BA_ "GenMsgSendType" BO_ 1891 1;
BA_ "VFrameFormat" BO_ 1891 14;
BA_ "GenMsgSendType" BO_ 1899 1;
BA_ "VFrameFormat" BO_ 1899 14;
BA_ "GenMsgCycleTime" BO_ 583 20;
BA_ "GenMsgSendType" BO_ 583 0;
BA_ "VFrameFormat" BO_ 583 14;
BA_ "GenMsgCycleTime" BO_ 710 40;
BA_ "GenMsgSendType" BO_ 710 0;
BA_ "VFrameFormat" BO_ 710 14;
BA_ "GenMsgCycleTime" BO_ 953 100;
BA_ "GenMsgSendType" BO_ 953 0;
BA_ "VFrameFormat" BO_ 953 14;
BA_ "GenMsgCycleTime" BO_ 901 100;
BA_ "GenMsgSendType" BO_ 901 0;
BA_ "VFrameFormat" BO_ 901 14;
BA_ "GenMsgCycleTime" BO_ 456 10;
BA_ "GenMsgSendType" BO_ 456 0;
BA_ "VFrameFormat" BO_ 456 14;

BA_ "GenSigCycleTime" SG_ 943 HU_RampInfo_EU 100;
BA_ "GenSigCycleTime" SG_ 943 HU_MaxNavSpeed 100;
BA_ "GenSigStartValue" SG_ 943 HU_MaxNavSpeed 254.000000;
BA_ "GenSigInvalidValue" SG_ 943 HU_MaxNavSpeed "255";
BA_ "GenSigCycleTime" SG_ 943 HU_MapStatus 100;
BA_ "GenSigInvalidValue" SG_ 943 HU_MapStatus "0";
BA_ "GenSigCycleTime" SG_ 943 HU_NavSpeedLimit_EU 100;
BA_ "GenSigStartValue" SG_ 943 HU_NavSpeedLimit_EU 254.000000;
BA_ "GenSigInvalidValue" SG_ 943 HU_NavSpeedLimit_EU "255";
BA_ "GenSigCycleTime" SG_ 943 HU_ForwardRoadType_EU 100;
BA_ "GenSigInvalidValue" SG_ 943 HU_ForwardRoadType_EU "7";
BA_ "GenSigCycleTime" SG_ 943 HU_NavCurrentRoadType_EU 100;
BA_ "GenSigInvalidValue" SG_ 943 HU_NavCurrentRoadType_EU "7";
BA_ "GenSigCycleTime" SG_ 943 HU_NavCountryCode_EU 100;
BA_ "GenSigInvalidValue" SG_ 943 HU_NavCountryCode_EU "0";
BA_ "GenSigCycleTime" SG_ 943 HU_realtimeNavRoadSpeedLimitType 100;
BA_ "GenSigInvalidValue" SG_ 943 HU_realtimeNavRoadSpeedLimitType "0";
BA_ "GenSigCycleTime" SG_ 943 HU_realtimeNavSpeedLimit 100;
BA_ "GenSigInvalidValue" SG_ 943 HU_realtimeNavSpeedLimit "254";
BA_ "GenSigCycleTime" SG_ 943 HU_FogSpeedLimit 100;
BA_ "GenSigInvalidValue" SG_ 943 HU_FogSpeedLimit "255";
BA_ "GenSigCycleTime" SG_ 943 HU_NavRoadSpeedLimitType 100;
BA_ "GenSigInvalidValue" SG_ 943 HU_NavRoadSpeedLimitType "0";
BA_ "GenSigCycleTime" SG_ 943 HU_SnowSpeedLimit 100;
BA_ "GenSigInvalidValue" SG_ 943 HU_SnowSpeedLimit "255";
BA_ "GenSigCycleTime" SG_ 943 HU_RainSpeedLimit 100;
BA_ "GenSigInvalidValue" SG_ 943 HU_RainSpeedLimit "255";
BA_ "GenSigCycleTime" SG_ 943 HU_CRCCheck_3AF 100;
BA_ "GenSigCycleTime" SG_ 943 HU_RollingCounter_3AF 100;
BA_ "GenSigCycleTime" SG_ 943 HU_ADAS_Posn_Offset 100;
BA_ "GenSigInvalidValue" SG_ 943 HU_ADAS_Posn_Offset "8191";
BA_ "GenSigCycleTime" SG_ 943 HU_ADAS_Posn_Pathldx 100;
BA_ "GenSigInvalidValue" SG_ 943 HU_ADAS_Posn_Pathldx "0";
BA_ "GenSigCycleTime" SG_ 943 HU_LaneConfluenceDis 100;
BA_ "GenSigStartValue" SG_ 943 HU_LaneConfluenceDis 63.000000;
BA_ "GenSigInvalidValue" SG_ 943 HU_LaneConfluenceDis "63";
BA_ "GenSigCycleTime" SG_ 943 HU_LaneConfluence 100;
BA_ "GenSigInvalidValue" SG_ 943 HU_LaneConfluence "3";
BA_ "GenSigCycleTime" SG_ 943 HU_IntervalVelocityDis 100;
BA_ "GenSigStartValue" SG_ 943 HU_IntervalVelocityDis 63.000000;
BA_ "GenSigInvalidValue" SG_ 943 HU_IntervalVelocityDis "63";
BA_ "GenSigCycleTime" SG_ 943 HU_IntervalVelocityInfo 100;
BA_ "GenSigInvalidValue" SG_ 943 HU_IntervalVelocityInfo "0";
BA_ "GenSigCycleTime" SG_ 943 HU_CRCCheck_3AF_3 100;
BA_ "GenSigCycleTime" SG_ 943 HU_RollingCounter_3AF_3 100;
BA_ "GenSigCycleTime" SG_ 943 HU_RampDistance 100;
BA_ "GenSigStartValue" SG_ 943 HU_RampDistance 1023.000000;
BA_ "GenSigInvalidValue" SG_ 943 HU_RampDistance "1023";
BA_ "GenSigCycleTime" SG_ 943 HU_CurveDistance 100;
BA_ "GenSigStartValue" SG_ 943 HU_CurveDistance 63.000000;
BA_ "GenSigInvalidValue" SG_ 943 HU_CurveDistance "63";
BA_ "GenSigCycleTime" SG_ 943 HU_EnterCurveInfo 100;
BA_ "GenSigInvalidValue" SG_ 943 HU_EnterCurveInfo "0";
BA_ "GenSigCycleTime" SG_ 943 HU_EnterRampInfo 100;
BA_ "GenSigInvalidValue" SG_ 943 HU_EnterRampInfo "0";
BA_ "GenSigCycleTime" SG_ 943 HU_NavStatus 100;
BA_ "GenSigInvalidValue" SG_ 943 HU_NavStatus "1";
BA_ "GenSigCycleTime" SG_ 943 HU_NavSpeedLimitUnits 100;
BA_ "GenSigInvalidValue" SG_ 943 HU_NavSpeedLimitUnits "0";
BA_ "GenSigCycleTime" SG_ 943 HU_NavSpeedLimitStatus 100;
BA_ "GenSigInvalidValue" SG_ 943 HU_NavSpeedLimitStatus "1";
BA_ "GenSigCycleTime" SG_ 943 HU_CRCCheck_3BB 100;
BA_ "GenSigCycleTime" SG_ 943 HU_RollingCounter_3BB 100;
BA_ "GenSigCycleTime" SG_ 943 HU_SlopeGradientFar 100;
BA_ "GenSigStartValue" SG_ 943 HU_SlopeGradientFar 1023.000000;
BA_ "GenSigInvalidValue" SG_ 943 HU_SlopeGradientFar "1023";
BA_ "GenSigCycleTime" SG_ 943 HU_SlopeGradient 100;
BA_ "GenSigStartValue" SG_ 943 HU_SlopeGradient 1023.000000;
BA_ "GenSigInvalidValue" SG_ 943 HU_SlopeGradient "1023";
BA_ "GenSigCycleTime" SG_ 943 HU_SpeedLimitDistance 100;
BA_ "GenSigStartValue" SG_ 943 HU_SpeedLimitDistance 63.000000;
BA_ "GenSigInvalidValue" SG_ 943 HU_SpeedLimitDistance "63";

BA_ "GenSigCycleTime" SG_ 947 BCM_BrakeLampError 100;
BA_ "GenSigCycleTime" SG_ 947 BCM_RearFoglampStatus 100;
BA_ "GenSigInvalidValue" SG_ 947 BCM_RearFoglampStatus "3";

BA_ "GenSigCycleTime" SG_ 957 HU_SentryModeSt 100;
BA_ "GenSigCycleTime" SG_ 957 HU_CSLAEnable 100;
BA_ "GenSigStartValue" SG_ 957 HU_CSLAEnable 3.000000;
BA_ "GenSigInvalidValue" SG_ 957 HU_CSLAEnable "3";
BA_ "GenSigCycleTime" SG_ 957 HU_TLAEnable 100;
BA_ "GenSigInvalidValue" SG_ 957 HU_TLAEnable "0";

BA_ "GenSigCycleTime" SG_ 964 HU_BSDLCAMode 100;
BA_ "GenSigCycleTime" SG_ 964 HU_CRCCheck_3C4 100;
BA_ "GenSigCycleTime" SG_ 964 HU_RollingCounter_3C4 100;
BA_ "GenSigCycleTime" SG_ 964 HU_CRCCheck_3C7 100;
BA_ "GenSigCycleTime" SG_ 964 HU_RollingCounter_3C7 100;
BA_ "GenSigCycleTime" SG_ 964 HU_CRCCheck_3C6 100;
BA_ "GenSigCycleTime" SG_ 964 HU_RollingCounter_3C6 100;
BA_ "GenSigCycleTime" SG_ 964 HU_CRCCheck_3C4_2 100;
BA_ "GenSigCycleTime" SG_ 964 HU_RollingCounter_3C4_2 100;
BA_ "GenSigCycleTime" SG_ 964 HU_CRCCheck_3C2 100;
BA_ "GenSigCycleTime" SG_ 964 HU_RollingCounter_3C2 100;
BA_ "GenSigCycleTime" SG_ 964 HU_MapDataUpdateStatus 100;
BA_ "GenSigInvalidValue" SG_ 964 HU_MapDataUpdateStatus "7";
BA_ "GenSigCycleTime" SG_ 964 HU_RoadCurvature_600m 100;
BA_ "GenSigStartValue" SG_ 964 HU_RoadCurvature_600m 511.000000;
BA_ "GenSigInvalidValue" SG_ 964 HU_RoadCurvature_600m "1023";
BA_ "GenSigCycleTime" SG_ 964 HU_RoadCurvature_400m 100;
BA_ "GenSigStartValue" SG_ 964 HU_RoadCurvature_400m 511.000000;
BA_ "GenSigInvalidValue" SG_ 964 HU_RoadCurvature_400m "1023";
BA_ "GenSigCycleTime" SG_ 964 HU_RoadCurvature_300m 100;
BA_ "GenSigStartValue" SG_ 964 HU_RoadCurvature_300m 511.000000;
BA_ "GenSigInvalidValue" SG_ 964 HU_RoadCurvature_300m "1023";
BA_ "GenSigCycleTime" SG_ 964 HU_RoadCurvature_100m 100;
BA_ "GenSigStartValue" SG_ 964 HU_RoadCurvature_100m 511.000000;
BA_ "GenSigInvalidValue" SG_ 964 HU_RoadCurvature_100m "1023";
BA_ "GenSigCycleTime" SG_ 964 HU_RoadCurvature_90m 100;
BA_ "GenSigStartValue" SG_ 964 HU_RoadCurvature_90m 511.000000;
BA_ "GenSigInvalidValue" SG_ 964 HU_RoadCurvature_90m "1023";
BA_ "GenSigCycleTime" SG_ 964 HU_RoadCurvature_80m 100;
BA_ "GenSigStartValue" SG_ 964 HU_RoadCurvature_80m 511.000000;
BA_ "GenSigInvalidValue" SG_ 964 HU_RoadCurvature_80m "1023";
BA_ "GenSigCycleTime" SG_ 964 HU_RoadCurvature_70m 100;
BA_ "GenSigStartValue" SG_ 964 HU_RoadCurvature_70m 511.000000;
BA_ "GenSigInvalidValue" SG_ 964 HU_RoadCurvature_70m "1023";
BA_ "GenSigCycleTime" SG_ 964 HU_RoadCurvature_60m 100;
BA_ "GenSigStartValue" SG_ 964 HU_RoadCurvature_60m 511.000000;
BA_ "GenSigInvalidValue" SG_ 964 HU_RoadCurvature_60m "1023";
BA_ "GenSigCycleTime" SG_ 964 HU_RoadCurvature_50m 100;
BA_ "GenSigStartValue" SG_ 964 HU_RoadCurvature_50m 511.000000;
BA_ "GenSigInvalidValue" SG_ 964 HU_RoadCurvature_50m "1023";
BA_ "GenSigCycleTime" SG_ 964 HU_RoadCurvature_40m 100;
BA_ "GenSigStartValue" SG_ 964 HU_RoadCurvature_40m 511.000000;
BA_ "GenSigInvalidValue" SG_ 964 HU_RoadCurvature_40m "1023";
BA_ "GenSigCycleTime" SG_ 964 HU_RoadCurvature_30m 100;
BA_ "GenSigStartValue" SG_ 964 HU_RoadCurvature_30m 511.000000;
BA_ "GenSigInvalidValue" SG_ 964 HU_RoadCurvature_30m "1023";
BA_ "GenSigCycleTime" SG_ 964 HU_RoadCurvature_20m 100;
BA_ "GenSigStartValue" SG_ 964 HU_RoadCurvature_20m 511.000000;
BA_ "GenSigInvalidValue" SG_ 964 HU_RoadCurvature_20m "1023";
BA_ "GenSigCycleTime" SG_ 964 HU_RoadCurvature_10m 100;
BA_ "GenSigStartValue" SG_ 964 HU_RoadCurvature_10m 511.000000;
BA_ "GenSigInvalidValue" SG_ 964 HU_RoadCurvature_10m "1023";
BA_ "GenSigCycleTime" SG_ 964 HU_Road_TrafficFlow 100;
BA_ "GenSigInvalidValue" SG_ 964 HU_Road_TrafficFlow "7";
BA_ "GenSigCycleTime" SG_ 964 HU_To_Construction_Dis 100;
BA_ "GenSigStartValue" SG_ 964 HU_To_Construction_Dis 63.000000;
BA_ "GenSigInvalidValue" SG_ 964 HU_To_Construction_Dis "63";
BA_ "GenSigCycleTime" SG_ 964 HU_Construction_Info 100;
BA_ "GenSigStartValue" SG_ 964 HU_Construction_Info 3.000000;
BA_ "GenSigInvalidValue" SG_ 964 HU_Construction_Info "3";
BA_ "GenSigCycleTime" SG_ 964 HU_RampSide 100;
BA_ "GenSigInvalidValue" SG_ 964 HU_RampSide "0";
BA_ "GenSigCycleTime" SG_ 964 HU_CRCCheck_3B8 100;
BA_ "GenSigCycleTime" SG_ 964 HU_RollingCounter_3B8 100;
BA_ "GenSigCycleTime" SG_ 964 HU_NavGuiganceStatus 100;
BA_ "GenSigInvalidValue" SG_ 964 HU_NavGuiganceStatus "3";
BA_ "GenSigCycleTime" SG_ 964 HU_TunnelLength 100;
BA_ "GenSigStartValue" SG_ 964 HU_TunnelLength 63.000000;
BA_ "GenSigInvalidValue" SG_ 964 HU_TunnelLength "63";
BA_ "GenSigCycleTime" SG_ 964 HU_RoadCurvatureFar 100;
BA_ "GenSigStartValue" SG_ 964 HU_RoadCurvatureFar 511.000000;
BA_ "GenSigInvalidValue" SG_ 964 HU_RoadCurvatureFar "1023";
BA_ "GenSigCycleTime" SG_ 964 HU_TunnelDistance 100;
BA_ "GenSigStartValue" SG_ 964 HU_TunnelDistance 63.000000;
BA_ "GenSigInvalidValue" SG_ 964 HU_TunnelDistance "63";
BA_ "GenSigCycleTime" SG_ 964 HU_RoadCurvature 100;
BA_ "GenSigStartValue" SG_ 964 HU_RoadCurvature 511.000000;
BA_ "GenSigInvalidValue" SG_ 964 HU_RoadCurvature "1023";
BA_ "GenSigCycleTime" SG_ 964 HU_EnterTunnelInfo 100;
BA_ "GenSigInvalidValue" SG_ 964 HU_EnterTunnelInfo "0";

BA_ "GenSigCycleTime" SG_ 1021 BCM_DriveMode 100;
BA_ "GenSigInvalidValue" SG_ 1021 BCM_DriveMode "15";
BA_ "GenSigCycleTime" SG_ 1021 BCM_PowerManageLevel 100;
BA_ "GenSigInvalidValue" SG_ 1021 BCM_PowerManageLevel "7";

BA_ "GenSigCycleTime" SG_ 1023 BCM_AutoHeadlightSts 100;
BA_ "GenSigInvalidValue" SG_ 1023 BCM_AutoHeadlightSts "0";
BA_ "GenSigCycleTime" SG_ 1023 BCM_FrontFoglampStatus 100;
BA_ "GenSigInvalidValue" SG_ 1023 BCM_FrontFoglampStatus "3";

BA_ "GenSigCycleTime" SG_ 1310 TPMS_TireTemperature 500;
BA_ "GenSigStartValue" SG_ 1310 TPMS_TireTemperature 40.000000;
BA_ "GenSigInvalidValue" SG_ 1310 TPMS_TireTemperature "255";
BA_ "GenSigCycleTime" SG_ 1310 TPMS_TirePosition 500;
BA_ "GenSigInvalidValue" SG_ 1310 TPMS_TirePosition "0";

BA_ "GenSigCycleTime" SG_ 1684 LAS_DTC2_Status 500;
BA_ "GenSigCycleTime" SG_ 1684 LAS_DTC2_LowByte 500;
BA_ "GenSigCycleTime" SG_ 1684 LAS_DTC2_MiddByte 500;
BA_ "GenSigCycleTime" SG_ 1684 LAS_DTC2_HighByte 500;
BA_ "GenSigCycleTime" SG_ 1684 LAS_DTC1_Status 500;
BA_ "GenSigCycleTime" SG_ 1684 LAS_DTC1_LowByte 500;
BA_ "GenSigCycleTime" SG_ 1684 LAS_DTC1_MiddByte 500;
BA_ "GenSigCycleTime" SG_ 1684 LAS_DTC1_HighByte 500;

BA_ "GenSigSendType" SG_ 1106 NM_message452 1;

BA_ "GenSigCycleTime" SG_ 652 GW_MFS_CRCCheck_28C 40;
BA_ "GenSigCycleTime" SG_ 652 GW_MFS_RollingCounter_28C 40;
BA_ "GenSigCycleTime" SG_ 652 GW_MFS_DiagInfoSW_28C 40;
BA_ "GenSigInvalidValue" SG_ 652 GW_MFS_DiagInfoSW_28C "7";
BA_ "GenSigCycleTime" SG_ 652 GW_MFS_IACCenable_switch_signal 40;
BA_ "GenSigInvalidValue" SG_ 652 GW_MFS_IACCenable_switch_signal "3";
BA_ "GenSigCycleTime" SG_ 652 GW_MFS_DIST_switch_signal 40;
BA_ "GenSigInvalidValue" SG_ 652 GW_MFS_DIST_switch_signal "3";
BA_ "GenSigCycleTime" SG_ 652 GW_MFS_SETReduce_switch_signal 40;
BA_ "GenSigInvalidValue" SG_ 652 GW_MFS_SETReduce_switch_signal "3";
BA_ "GenSigCycleTime" SG_ 652 GW_MFS_RESPlus_switch_signal 40;
BA_ "GenSigInvalidValue" SG_ 652 GW_MFS_RESPlus_switch_signal "3";
BA_ "GenSigCycleTime" SG_ 652 GW_MFS_Cancle_switch_signal 40;
BA_ "GenSigInvalidValue" SG_ 652 GW_MFS_Cancle_switch_signal "3";
BA_ "GenSigCycleTime" SG_ 652 GW_MFS_Crusie_switch_signal 40;
BA_ "GenSigInvalidValue" SG_ 652 GW_MFS_Crusie_switch_signal "3";
BA_ "GenSigCycleTime" SG_ 652 GW_MFS_DISTReduce_switch_signal 40;
BA_ "GenSigCycleTime" SG_ 652 GW_MFS_DISTPlus_switch_signal 40;

BA_ "GenSigCycleTime" SG_ 817 TCU_TransFaultLevel 100;
BA_ "GenSigInvalidValue" SG_ 817 TCU_TransFaultLevel "7";

BA_ "GenSigCycleTime" SG_ 431 TCU_ShiftPostionValid 10;
BA_ "GenSigInvalidValue" SG_ 431 TCU_ShiftPostionValid "1";
BA_ "GenSigCycleTime" SG_ 431 TCU_ShiftInProgressVld 10;
BA_ "GenSigCycleTime" SG_ 431 TCU_ShiftInProgress 10;
BA_ "GenSigCycleTime" SG_ 431 TCU_RollingCounter_1A8 10;
BA_ "GenSigCycleTime" SG_ 431 TCU_GearShiftPosition 10;
BA_ "GenSigStartValue" SG_ 431 TCU_GearShiftPosition 13.000000;
BA_ "GenSigInvalidValue" SG_ 431 TCU_GearShiftPosition "15";
BA_ "GenSigCycleTime" SG_ 431 TCU_CRCCheck_1A8 10;
BA_ "GenSigCycleTime" SG_ 431 TCU_ActualDrivingGearValid 10;
BA_ "GenSigInvalidValue" SG_ 431 TCU_ActualDrivingGearValid "1";
BA_ "GenSigCycleTime" SG_ 431 TCU_ActualDrivingGear 10;
BA_ "GenSigInvalidValue" SG_ 431 TCU_ActualDrivingGear "15";

BA_ "GenSigCycleTime" SG_ 800 GW_ResetReq 100;
BA_ "GenSigInvalidValue" SG_ 800 GW_ResetReq "127";

BA_ "GenSigCycleTime" SG_ 922 LAS_RoadFeature 100;
BA_ "GenSigStartValue" SG_ 922 LAS_RoadFeature 15.000000;
BA_ "GenSigInvalidValue" SG_ 922 LAS_RoadFeature "15";
BA_ "GenSigCycleTime" SG_ 922 LAS_RD4LongDistence 100;
BA_ "GenSigStartValue" SG_ 922 LAS_RD4LongDistence 255.000000;
BA_ "GenSigInvalidValue" SG_ 922 LAS_RD4LongDistence "255";
BA_ "GenSigCycleTime" SG_ 922 LAS_RD3LongDistence 100;
BA_ "GenSigStartValue" SG_ 922 LAS_RD3LongDistence 255.000000;
BA_ "GenSigInvalidValue" SG_ 922 LAS_RD3LongDistence "255";
BA_ "GenSigCycleTime" SG_ 922 LAS_RD2LongDistence 100;
BA_ "GenSigStartValue" SG_ 922 LAS_RD2LongDistence 255.000000;
BA_ "GenSigInvalidValue" SG_ 922 LAS_RD2LongDistence "255";
BA_ "GenSigCycleTime" SG_ 922 LAS_RD1LongDistence 100;
BA_ "GenSigStartValue" SG_ 922 LAS_RD1LongDistence 255.000000;
BA_ "GenSigInvalidValue" SG_ 922 LAS_RD1LongDistence "255";
BA_ "GenSigCycleTime" SG_ 922 LAS_RD4RoadInforAvailable 100;
BA_ "GenSigInvalidValue" SG_ 922 LAS_RD4RoadInforAvailable "1";
BA_ "GenSigCycleTime" SG_ 922 LAS_RD3RoadInforAvailable 100;
BA_ "GenSigInvalidValue" SG_ 922 LAS_RD3RoadInforAvailable "1";
BA_ "GenSigCycleTime" SG_ 922 LAS_RD2RoadInforAvailable 100;
BA_ "GenSigInvalidValue" SG_ 922 LAS_RD2RoadInforAvailable "1";
BA_ "GenSigCycleTime" SG_ 922 LAS_RD1RoadInforAvailable 100;
BA_ "GenSigInvalidValue" SG_ 922 LAS_RD1RoadInforAvailable "1";
BA_ "GenSigCycleTime" SG_ 922 LAS_RollingCounter_579 100;
BA_ "GenSigCycleTime" SG_ 922 LAS_CRCCheck_579 100;
BA_ "GenSigCycleTime" SG_ 922 LAS_TSRSpeedLimitType 100;
BA_ "GenSigInvalidValue" SG_ 922 LAS_TSRSpeedLimitType "0";
BA_ "GenSigCycleTime" SG_ 922 ACC_RollingCounter_39A 100;
BA_ "GenSigCycleTime" SG_ 922 ACC_CRCCheck_39A 100;
BA_ "GenSigCycleTime" SG_ 922 LAS_TSRRightLaneStatus 100;
BA_ "GenSigInvalidValue" SG_ 922 LAS_TSRRightLaneStatus "7";
BA_ "GenSigCycleTime" SG_ 922 LAS_TSRLeftLaneStatus 100;
BA_ "GenSigInvalidValue" SG_ 922 LAS_TSRLeftLaneStatus "7";
BA_ "GenSigCycleTime" SG_ 922 LAS_CRCCheck_3C0 100;
BA_ "GenSigCycleTime" SG_ 922 LAS_RollingCounter_3C0 100;
BA_ "GenSigCycleTime" SG_ 922 LAS_TSRRightLaneSpdLimit 100;
BA_ "GenSigInvalidValue" SG_ 922 LAS_TSRRightLaneSpdLimit "254";
BA_ "GenSigCycleTime" SG_ 922 LAS_TSRLeftLaneSpdLimit 100;
BA_ "GenSigInvalidValue" SG_ 922 LAS_TSRLeftLaneSpdLimit "254";
BA_ "GenSigCycleTime" SG_ 922 LAS_CRCCheck_3D4 100;
BA_ "GenSigCycleTime" SG_ 922 LAS_RollingCounter_3D4 100;
BA_ "GenSigCycleTime" SG_ 922 LAS_TLAStopLine_HostLane 100;
BA_ "GenSigStartValue" SG_ 922 LAS_TLAStopLine_HostLane 255.000000;
BA_ "GenSigCycleTime" SG_ 922 LAS_TLADistance_HostLane 100;
BA_ "GenSigStartValue" SG_ 922 LAS_TLADistance_HostLane 255.000000;
BA_ "GenSigCycleTime" SG_ 922 LAS_TLACountDownTime_HostLane 100;
BA_ "GenSigCycleTime" SG_ 922 LAS_TSRMandatorySign 100;
BA_ "GenSigCycleTime" SG_ 922 LAS_TSRWarningSign 100;
BA_ "GenSigCycleTime" SG_ 922 LAS_TSRProhibitionSign 100;
BA_ "GenSigCycleTime" SG_ 922 LAS_CRCCheck_332 100;
BA_ "GenSigCycleTime" SG_ 922 LAS_RollingCounter_332 100;
BA_ "GenSigCycleTime" SG_ 922 LAS_OverspeedSoundWarningEnSt 100;
BA_ "GenSigCycleTime" SG_ 922 LAS_TSREnable 100;
BA_ "GenSigCycleTime" SG_ 922 LAS_HMAEnableStatus 100;
BA_ "GenSigCycleTime" SG_ 922 LAS_HMALightDistribution 100;
BA_ "GenSigCycleTime" SG_ 922 LAS_HMAStatus 100;
BA_ "GenSigInvalidValue" SG_ 922 LAS_HMAStatus "3";
BA_ "GenSigCycleTime" SG_ 922 LAS_TSRHostSpdLimitUnits 100;
BA_ "GenSigInvalidValue" SG_ 922 LAS_TSRHostSpdLimitUnits "0";
BA_ "GenSigCycleTime" SG_ 922 LAS_TSRHostSpdLimit 100;
BA_ "GenSigInvalidValue" SG_ 922 LAS_TSRHostSpdLimit "254";
BA_ "GenSigCycleTime" SG_ 922 LAS_TSRStatus 100;
BA_ "GenSigInvalidValue" SG_ 922 LAS_TSRStatus "7";
BA_ "GenSigCycleTime" SG_ 922 LAS_FrontCameraCalibrationStatus 100;
BA_ "GenSigInvalidValue" SG_ 922 LAS_FrontCameraCalibrationStatus "3";
BA_ "GenSigCycleTime" SG_ 922 LAS_FrontCameraFailureStatus 100;
BA_ "GenSigInvalidValue" SG_ 922 LAS_FrontCameraFailureStatus "3";
BA_ "GenSigCycleTime" SG_ 922 LAS_OverspeedWarningOffset 100;
BA_ "GenSigStartValue" SG_ 922 LAS_OverspeedWarningOffset 10.000000;
BA_ "GenSigCycleTime" SG_ 922 LAS_OverspeedWarningEnableStatus 100;
BA_ "GenSigCycleTime" SG_ 922 LAS_OverspeedSoundWarning 100;
BA_ "GenSigCycleTime" SG_ 922 LAS_OverspeedVisualWarning 100;
BA_ "GenSigCycleTime" SG_ 922 LAS_CRCCheck_37D 100;
BA_ "GenSigCycleTime" SG_ 922 LAS_RollingCounter_37D 100;
BA_ "GenSigCycleTime" SG_ 922 LAS_TLAArrowDirection_RightLane 100;
BA_ "GenSigCycleTime" SG_ 922 LAS_TLAObjectType_RightLane 100;
BA_ "GenSigCycleTime" SG_ 922 LAS_TLAObjectStatus_RightLane 100;
BA_ "GenSigCycleTime" SG_ 922 LAS_TLAObjectColour_RightLane 100;
BA_ "GenSigCycleTime" SG_ 922 LAS_TLAObjectDetection_RightLane 100;
BA_ "GenSigCycleTime" SG_ 922 LAS_TLAArrowDirection_LeftLane 100;
BA_ "GenSigCycleTime" SG_ 922 LAS_TLAObjectType_LeftLane 100;
BA_ "GenSigCycleTime" SG_ 922 LAS_TLAObjectStatus_LeftLane 100;
BA_ "GenSigCycleTime" SG_ 922 LAS_TLAObjectColour_LeftLane 100;
BA_ "GenSigCycleTime" SG_ 922 LAS_TLAObjectDetection_LeftLane 100;
BA_ "GenSigCycleTime" SG_ 922 LAS_TLAArrowDirection_HostLane 100;
BA_ "GenSigCycleTime" SG_ 922 LAS_TLAObjectStatus_HostLane 100;
BA_ "GenSigCycleTime" SG_ 922 LAS_TLAObjectType_HostLane 100;
BA_ "GenSigCycleTime" SG_ 922 LAS_TLAObjectColour_HostLane 100;
BA_ "GenSigCycleTime" SG_ 922 LAS_TLAObjectDetection_HostLane 100;
BA_ "GenSigCycleTime" SG_ 922 LAS_TLAWarninglevel 100;
BA_ "GenSigCycleTime" SG_ 922 LAS_TLAStatus 100;
BA_ "GenSigInvalidValue" SG_ 922 LAS_TLAStatus "3";
BA_ "GenSigCycleTime" SG_ 922 LAS_TLAEnable 100;
BA_ "GenSigCycleTime" SG_ 922 LAS_RoadSignCenterLatRange_RLane 100;
BA_ "GenSigCycleTime" SG_ 922 LAS_RoadSignCenterLngRange_RLane 100;
BA_ "GenSigCycleTime" SG_ 922 LAS_RoadSignCenterLatRange_LLane 100;
BA_ "GenSigCycleTime" SG_ 922 LAS_RoadSignCenterLngRange_LLane 100;
BA_ "GenSigCycleTime" SG_ 922 LAS_RoadSignCenterLatRange_HLane 100;
BA_ "GenSigCycleTime" SG_ 922 LAS_RoadSignCenterLngRange_HLane 100;
BA_ "GenSigCycleTime" SG_ 922 LAS_CrosswalkLngRange_HLane 100;
BA_ "GenSigStartValue" SG_ 922 LAS_CrosswalkLngRange_HLane 255.000000;
BA_ "GenSigCycleTime" SG_ 922 LAS_RoadSignType_RLane 100;
BA_ "GenSigCycleTime" SG_ 922 LAS_RoadSignType_LLane 100;
BA_ "GenSigCycleTime" SG_ 922 LAS_RoadSignType_HLane 100;

BA_ "GenSigCycleTime" SG_ 784 AMP_AllAlarmFailureStatus 100;
BA_ "GenSigCycleTime" SG_ 784 AMP_IPEnableAlarmFailureStatus 100;

BA_ "GenSigCycleTime" SG_ 1000 BCM_SOF_Q_STATE 100;
BA_ "GenSigStartValue" SG_ 1000 BCM_SOF_Q_STATE 3.000000;
BA_ "GenSigInvalidValue" SG_ 1000 BCM_SOF_Q_STATE "3";
BA_ "GenSigCycleTime" SG_ 1000 BCM_SOF_Q 100;
BA_ "GenSigStartValue" SG_ 1000 BCM_SOF_Q 255.000000;
BA_ "GenSigInvalidValue" SG_ 1000 BCM_SOF_Q "255";

BA_ "GenSigCycleTime" SG_ 999 BCM_Status_Temp 100;
BA_ "GenSigInvalidValue" SG_ 999 BCM_Status_Temp "0";
BA_ "GenSigCycleTime" SG_ 999 BCM_T_BATT 100;
BA_ "GenSigStartValue" SG_ 999 BCM_T_BATT 255.000000;
BA_ "GenSigInvalidValue" SG_ 999 BCM_T_BATT "255";

BA_ "GenSigCycleTime" SG_ 906 GW_MFS_VolReduce_switch 40;
BA_ "GenSigInvalidValue" SG_ 906 GW_MFS_VolReduce_switch "3";
BA_ "GenSigCycleTime" SG_ 906 GW_MFS_VolPlus_switch 40;
BA_ "GenSigInvalidValue" SG_ 906 GW_MFS_VolPlus_switch "3";
BA_ "GenSigCycleTime" SG_ 906 GW_MFS_UP_switch 40;
BA_ "GenSigInvalidValue" SG_ 906 GW_MFS_UP_switch "3";
BA_ "GenSigCycleTime" SG_ 906 GW_MFS_Speech_switch 40;
BA_ "GenSigInvalidValue" SG_ 906 GW_MFS_Speech_switch "3";
BA_ "GenSigCycleTime" SG_ 906 GW_MFS_SeekPlus_switch 40;
BA_ "GenSigInvalidValue" SG_ 906 GW_MFS_SeekPlus_switch "3";
BA_ "GenSigCycleTime" SG_ 906 GW_MFS_Right_switch 40;
BA_ "GenSigInvalidValue" SG_ 906 GW_MFS_Right_switch "3";
BA_ "GenSigCycleTime" SG_ 906 GW_MFS_OK_switch 40;
BA_ "GenSigInvalidValue" SG_ 906 GW_MFS_OK_switch "3";
BA_ "GenSigCycleTime" SG_ 906 GW_MFS_Mute_switch 40;
BA_ "GenSigInvalidValue" SG_ 906 GW_MFS_Mute_switch "3";
BA_ "GenSigCycleTime" SG_ 906 GW_MFS_Left_switch 40;
BA_ "GenSigInvalidValue" SG_ 906 GW_MFS_Left_switch "3";
BA_ "GenSigCycleTime" SG_ 906 GW_MFS_Hungup_switch_signal 40;
BA_ "GenSigInvalidValue" SG_ 906 GW_MFS_Hungup_switch_signal "3";
BA_ "GenSigCycleTime" SG_ 906 GW_MFS_Down_switch 40;
BA_ "GenSigInvalidValue" SG_ 906 GW_MFS_Down_switch "3";
BA_ "GenSigCycleTime" SG_ 906 GW_MFS_Answer_switch_signal 40;
BA_ "GenSigInvalidValue" SG_ 906 GW_MFS_Answer_switch_signal "3";
BA_ "GenSigCycleTime" SG_ 906 GW_MFS_SeekReduce_switch 40;
BA_ "GenSigInvalidValue" SG_ 906 GW_MFS_SeekReduce_switch "3";

BA_ "GenSigCycleTime" SG_ 586 ESL_DriverParkRequest 20;
BA_ "GenSigInvalidValue" SG_ 586 ESL_DriverParkRequest "3";
BA_ "GenSigCycleTime" SG_ 586 ESL_ShiftLeverPositionrequest 20;
BA_ "GenSigInvalidValue" SG_ 586 ESL_ShiftLeverPositionrequest "15";
BA_ "GenSigCycleTime" SG_ 586 ESL_ShiftLeverPositionFaultSts 20;

BA_ "GenSigCycleTime" SG_ 833 PCU_PwrTqWhMinVld 100;
BA_ "GenSigCycleTime" SG_ 833 PCU_PwrTqWhMinTotal 100;
BA_ "GenSigCycleTime" SG_ 833 PCU_PwrTqWhMaxVld 100;
BA_ "GenSigCycleTime" SG_ 833 PCU_PwrTqWhMaxTotal 100;

BA_ "GenSigCycleTime" SG_ 866 PCU_DrvMod 100;
BA_ "GenSigCycleTime" SG_ 866 PCU_DrvModVld 100;

BA_ "GenSigCycleTime" SG_ 723 ACC_CRCCheck_283 40;
BA_ "GenSigCycleTime" SG_ 723 ACC_RollingCounter_283 40;
BA_ "GenSigCycleTime" SG_ 723 ACC_AEBTargetLatRelSpeed_for_SRS 40;
BA_ "GenSigCycleTime" SG_ 723 ACC_AEBTargetLatRange_for_SRS 40;
BA_ "GenSigStartValue" SG_ 723 ACC_AEBTargetLatRange_for_SRS 500.000000;
BA_ "GenSigCycleTime" SG_ 723 ACC_CRCCheckr_282 40;
BA_ "GenSigCycleTime" SG_ 723 ACC_RollingCounter_282 40;
BA_ "GenSigCycleTime" SG_ 723 ACC_AEBTargetProb_for_SRS 40;
BA_ "GenSigCycleTime" SG_ 723 ACC_AEBTargetType_for_SRS 40;
BA_ "GenSigStartValue" SG_ 723 ACC_AEBTargetType_for_SRS 15.000000;
BA_ "GenSigCycleTime" SG_ 723 ACC_AEBTargetTTC_for_SRS 40;
BA_ "GenSigStartValue" SG_ 723 ACC_AEBTargetTTC_for_SRS 251.000000;
BA_ "GenSigInvalidValue" SG_ 723 ACC_AEBTargetTTC_for_SRS "254";
BA_ "GenSigCycleTime" SG_ 723 ACC_AEBTargetRelSpeed_for_SRS 40;
BA_ "GenSigStartValue" SG_ 723 ACC_AEBTargetRelSpeed_for_SRS 250.000000;
BA_ "GenSigCycleTime" SG_ 723 ACC_AEBTargetLngRange_for_SRS 40;
BA_ "GenSigStartValue" SG_ 723 ACC_AEBTargetLngRange_for_SRS 500.000000;
BA_ "GenSigCycleTime" SG_ 723 ACC_AEBActive_for_SRS 40;
BA_ "GenSigCycleTime" SG_ 723 ACC_AEBStatus_for_SRS 40;
BA_ "GenSigInvalidValue" SG_ 723 ACC_AEBStatus_for_SRS "3";

BA_ "GenSigCycleTime" SG_ 780 LAS_ResetSts 100;
BA_ "GenSigInvalidValue" SG_ 780 LAS_ResetSts "7";

BA_ "GenSigCycleTime" SG_ 738 RLR_CRCCheck_2E2 50;
BA_ "GenSigCycleTime" SG_ 738 RLR_RollingCounter_2E2 50;
BA_ "GenSigCycleTime" SG_ 738 RLR_ElkOBJ2_Measured 50;
BA_ "GenSigInvalidValue" SG_ 738 RLR_ElkOBJ2_Measured "0";
BA_ "GenSigCycleTime" SG_ 738 RLR_ElkOBJ2_ExistProb 50;
BA_ "GenSigInvalidValue" SG_ 738 RLR_ElkOBJ2_ExistProb "0";
BA_ "GenSigCycleTime" SG_ 738 RLR_ElkOBJ2_Location 50;
BA_ "GenSigInvalidValue" SG_ 738 RLR_ElkOBJ2_Location "0";
BA_ "GenSigCycleTime" SG_ 738 RLR_ElkOBJ2_RelAx 50;
BA_ "GenSigCycleTime" SG_ 738 RLR_ElkOBJ2_RelAy 50;
BA_ "GenSigCycleTime" SG_ 738 RLR_ElkOBJ2_RelVx 50;
BA_ "GenSigCycleTime" SG_ 738 RLR_ElkOBJ2_RelVy 50;
BA_ "GenSigCycleTime" SG_ 738 RLR_ElkOBJ2_Dx 50;
BA_ "GenSigCycleTime" SG_ 738 RLR_ElkOBJ2_RefPointLoc 50;
BA_ "GenSigCycleTime" SG_ 738 RLR_ElkOBJ2_Dy 50;
BA_ "GenSigCycleTime" SG_ 738 RLR_ElkOBJ2_HeadingAngle 50;
BA_ "GenSigCycleTime" SG_ 738 RLR_ElkOBJ2_Length 50;
BA_ "GenSigCycleTime" SG_ 738 RLR_ElkOBJ2_Height 50;
BA_ "GenSigCycleTime" SG_ 738 RLR_ElkOBJ2_Width 50;
BA_ "GenSigCycleTime" SG_ 738 RLR_ElkOBJ2_Type 50;
BA_ "GenSigInvalidValue" SG_ 738 RLR_ElkOBJ2_Type "0";
BA_ "GenSigCycleTime" SG_ 738 RLR_ElkOBJ2_Track_ID 50;
BA_ "GenSigCycleTime" SG_ 738 RLR_ElkOBJ2_RefPointDx 50;
BA_ "GenSigCycleTime" SG_ 738 RLR_ElkOBJ2_RefPointDy 50;
BA_ "GenSigCycleTime" SG_ 738 RLR_ElkOBJ2_ObstacleProb 50;
BA_ "GenSigCycleTime" SG_ 738 RLR_ElkOBJ1_RefPointDx 50;
BA_ "GenSigCycleTime" SG_ 738 RLR_ElkOBJ1_RefPointDy 50;
BA_ "GenSigCycleTime" SG_ 738 RLR_ElkOBJ1_ObstacleProb 50;
BA_ "GenSigCycleTime" SG_ 738 RLR_ElkOBJ1_Measured 50;
BA_ "GenSigInvalidValue" SG_ 738 RLR_ElkOBJ1_Measured "0";
BA_ "GenSigCycleTime" SG_ 738 RLR_ElkOBJ1_ExistProb 50;
BA_ "GenSigInvalidValue" SG_ 738 RLR_ElkOBJ1_ExistProb "0";
BA_ "GenSigCycleTime" SG_ 738 RLR_ElkOBJ1_Location 50;
BA_ "GenSigInvalidValue" SG_ 738 RLR_ElkOBJ1_Location "0";
BA_ "GenSigCycleTime" SG_ 738 RLR_ElkOBJ1_RelAx 50;
BA_ "GenSigCycleTime" SG_ 738 RLR_ElkOBJ1_RelAy 50;
BA_ "GenSigCycleTime" SG_ 738 RLR_ElkOBJ1_RelVx 50;
BA_ "GenSigCycleTime" SG_ 738 RLR_ElkOBJ1_RelVy 50;
BA_ "GenSigCycleTime" SG_ 738 RLR_ElkOBJ1_Dx 50;
BA_ "GenSigCycleTime" SG_ 738 RLR_ElkOBJ1_RefPointLoc 50;
BA_ "GenSigCycleTime" SG_ 738 RLR_ElkOBJ1_Dy 50;
BA_ "GenSigCycleTime" SG_ 738 RLR_ElkOBJ1_HeadingAngle 50;
BA_ "GenSigCycleTime" SG_ 738 RLR_ElkOBJ1_Length 50;
BA_ "GenSigCycleTime" SG_ 738 RLR_ElkOBJ1_Height 50;
BA_ "GenSigCycleTime" SG_ 738 RLR_ElkOBJ1_Width 50;
BA_ "GenSigCycleTime" SG_ 738 RLR_ElkOBJ1_Type 50;
BA_ "GenSigInvalidValue" SG_ 738 RLR_ElkOBJ1_Type "0";
BA_ "GenSigCycleTime" SG_ 738 RLR_ElkOBJ1_Track_ID 50;

BA_ "GenSigCycleTime" SG_ 739 RLR_CRCCheck_2E3 50;
BA_ "GenSigCycleTime" SG_ 739 RLR_RollingCounter_2E3 50;
BA_ "GenSigCycleTime" SG_ 739 RLR_ElkOBJ4_Measured 50;
BA_ "GenSigInvalidValue" SG_ 739 RLR_ElkOBJ4_Measured "0";
BA_ "GenSigCycleTime" SG_ 739 RLR_ElkOBJ4_ExistProb 50;
BA_ "GenSigInvalidValue" SG_ 739 RLR_ElkOBJ4_ExistProb "0";
BA_ "GenSigCycleTime" SG_ 739 RLR_ElkOBJ4_Location 50;
BA_ "GenSigInvalidValue" SG_ 739 RLR_ElkOBJ4_Location "0";
BA_ "GenSigCycleTime" SG_ 739 RLR_ElkOBJ4_RelAx 50;
BA_ "GenSigCycleTime" SG_ 739 RLR_ElkOBJ4_RelAy 50;
BA_ "GenSigCycleTime" SG_ 739 RLR_ElkOBJ4_RelVx 50;
BA_ "GenSigCycleTime" SG_ 739 RLR_ElkOBJ4_RelVy 50;
BA_ "GenSigCycleTime" SG_ 739 RLR_ElkOBJ4_Dx 50;
BA_ "GenSigCycleTime" SG_ 739 RLR_ElkOBJ4_RefPointLoc 50;
BA_ "GenSigCycleTime" SG_ 739 RLR_ElkOBJ4_Dy 50;
BA_ "GenSigCycleTime" SG_ 739 RLR_ElkOBJ4_HeadingAngle 50;
BA_ "GenSigCycleTime" SG_ 739 RLR_ElkOBJ4_Length 50;
BA_ "GenSigCycleTime" SG_ 739 RLR_ElkOBJ4_Height 50;
BA_ "GenSigCycleTime" SG_ 739 RLR_ElkOBJ4_Width 50;
BA_ "GenSigCycleTime" SG_ 739 RLR_ElkOBJ4_Type 50;
BA_ "GenSigInvalidValue" SG_ 739 RLR_ElkOBJ4_Type "0";
BA_ "GenSigCycleTime" SG_ 739 RLR_ElkOBJ4_Track_ID 50;
BA_ "GenSigCycleTime" SG_ 739 RLR_ElkOBJ4_RefPointDx 50;
BA_ "GenSigCycleTime" SG_ 739 RLR_ElkOBJ4_RefPointDy 50;
BA_ "GenSigCycleTime" SG_ 739 RLR_ElkOBJ4_ObstacleProb 50;
BA_ "GenSigCycleTime" SG_ 739 RLR_ElkOBJ3_RefPointDx 50;
BA_ "GenSigCycleTime" SG_ 739 RLR_ElkOBJ3_RefPointDy 50;
BA_ "GenSigCycleTime" SG_ 739 RLR_ElkOBJ3_ObstacleProb 50;
BA_ "GenSigCycleTime" SG_ 739 RLR_ElkOBJ3_Measured 50;
BA_ "GenSigInvalidValue" SG_ 739 RLR_ElkOBJ3_Measured "0";
BA_ "GenSigCycleTime" SG_ 739 RLR_ElkOBJ3_ExistProb 50;
BA_ "GenSigInvalidValue" SG_ 739 RLR_ElkOBJ3_ExistProb "0";
BA_ "GenSigCycleTime" SG_ 739 RLR_ElkOBJ3_Location 50;
BA_ "GenSigInvalidValue" SG_ 739 RLR_ElkOBJ3_Location "0";
BA_ "GenSigCycleTime" SG_ 739 RLR_ElkOBJ3_RelAx 50;
BA_ "GenSigCycleTime" SG_ 739 RLR_ElkOBJ3_RelAy 50;
BA_ "GenSigCycleTime" SG_ 739 RLR_ElkOBJ3_RelVx 50;
BA_ "GenSigCycleTime" SG_ 739 RLR_ElkOBJ3_RelVy 50;
BA_ "GenSigCycleTime" SG_ 739 RLR_ElkOBJ3_Dx 50;
BA_ "GenSigCycleTime" SG_ 739 RLR_ElkOBJ3_RefPointLoc 50;
BA_ "GenSigCycleTime" SG_ 739 RLR_ElkOBJ3_Dy 50;
BA_ "GenSigCycleTime" SG_ 739 RLR_ElkOBJ3_HeadingAngle 50;
BA_ "GenSigCycleTime" SG_ 739 RLR_ElkOBJ3_Length 50;
BA_ "GenSigCycleTime" SG_ 739 RLR_ElkOBJ3_Height 50;
BA_ "GenSigCycleTime" SG_ 739 RLR_ElkOBJ3_Width 50;
BA_ "GenSigCycleTime" SG_ 739 RLR_ElkOBJ3_Type 50;
BA_ "GenSigInvalidValue" SG_ 739 RLR_ElkOBJ3_Type "0";
BA_ "GenSigCycleTime" SG_ 739 RLR_ElkOBJ3_Track_ID 50;

BA_ "GenSigCycleTime" SG_ 1304 BCM_CarMode 500;
BA_ "GenSigInvalidValue" SG_ 1304 BCM_CarMode "0";

BA_ "GenSigCycleTime" SG_ 686 LCDAL_SystemStatus 50;
BA_ "GenSigStartValue" SG_ 686 LCDAL_SystemStatus 1.000000;
BA_ "GenSigInvalidValue" SG_ 686 LCDAL_SystemStatus "7";

BA_ "GenSigCycleTime" SG_ 985 ACC_ObsTarget10ID 100;
BA_ "GenSigCycleTime" SG_ 985 ACC_ObsTarget10Type 100;
BA_ "GenSigCycleTime" SG_ 985 ACC_ObsTarget10LatRange 100;
BA_ "GenSigStartValue" SG_ 985 ACC_ObsTarget10LatRange 1023.000000;
BA_ "GenSigCycleTime" SG_ 985 ACC_ObsTarget10LngRange 100;
BA_ "GenSigStartValue" SG_ 985 ACC_ObsTarget10LngRange 2047.000000;
BA_ "GenSigCycleTime" SG_ 985 ACC_ObsTarget9ID 100;
BA_ "GenSigCycleTime" SG_ 985 ACC_ObsTarget9Type 100;
BA_ "GenSigCycleTime" SG_ 985 ACC_ObsTarget9LatRange 100;
BA_ "GenSigStartValue" SG_ 985 ACC_ObsTarget9LatRange 1023.000000;
BA_ "GenSigCycleTime" SG_ 985 ACC_ObsTarget9LngRange 100;
BA_ "GenSigStartValue" SG_ 985 ACC_ObsTarget9LngRange 2047.000000;
BA_ "GenSigCycleTime" SG_ 985 ACC_ObsTarget8ID 100;
BA_ "GenSigCycleTime" SG_ 985 ACC_ObsTarget8Type 100;
BA_ "GenSigCycleTime" SG_ 985 ACC_ObsTarget8LatRange 100;
BA_ "GenSigStartValue" SG_ 985 ACC_ObsTarget8LatRange 1023.000000;
BA_ "GenSigCycleTime" SG_ 985 ACC_ObsTarget8LngRange 100;
BA_ "GenSigStartValue" SG_ 985 ACC_ObsTarget8LngRange 2047.000000;
BA_ "GenSigCycleTime" SG_ 985 ACC_ObsTarget7ID 100;
BA_ "GenSigCycleTime" SG_ 985 ACC_ObsTarget7Type 100;
BA_ "GenSigCycleTime" SG_ 985 ACC_ObsTarget7LatRange 100;
BA_ "GenSigStartValue" SG_ 985 ACC_ObsTarget7LatRange 1023.000000;
BA_ "GenSigCycleTime" SG_ 985 ACC_ObsTarget7LngRange 100;
BA_ "GenSigStartValue" SG_ 985 ACC_ObsTarget7LngRange 2047.000000;
BA_ "GenSigCycleTime" SG_ 985 ACC_ObsTarget6ID 100;
BA_ "GenSigCycleTime" SG_ 985 ACC_ObsTarget6Type 100;
BA_ "GenSigCycleTime" SG_ 985 ACC_ObsTarget6LatRange 100;
BA_ "GenSigStartValue" SG_ 985 ACC_ObsTarget6LatRange 1023.000000;
BA_ "GenSigCycleTime" SG_ 985 ACC_ObsTarget6LngRange 100;
BA_ "GenSigStartValue" SG_ 985 ACC_ObsTarget6LngRange 2047.000000;
BA_ "GenSigCycleTime" SG_ 985 ACC_ObsTarget5ID 100;
BA_ "GenSigCycleTime" SG_ 985 ACC_ObsTarget5Type 100;
BA_ "GenSigCycleTime" SG_ 985 ACC_ObsTarget5LatRange 100;
BA_ "GenSigStartValue" SG_ 985 ACC_ObsTarget5LatRange 1023.000000;
BA_ "GenSigCycleTime" SG_ 985 ACC_ObsTarget5LngRange 100;
BA_ "GenSigStartValue" SG_ 985 ACC_ObsTarget5LngRange 2047.000000;
BA_ "GenSigCycleTime" SG_ 985 ACC_ObsTarget4ID 100;
BA_ "GenSigCycleTime" SG_ 985 ACC_ObsTarget4Type 100;
BA_ "GenSigCycleTime" SG_ 985 ACC_ObsTarget4LatRange 100;
BA_ "GenSigStartValue" SG_ 985 ACC_ObsTarget4LatRange 1023.000000;
BA_ "GenSigCycleTime" SG_ 985 ACC_ObsTarget4LngRange 100;
BA_ "GenSigStartValue" SG_ 985 ACC_ObsTarget4LngRange 2047.000000;
BA_ "GenSigCycleTime" SG_ 985 ACC_ObsTarget3ID 100;
BA_ "GenSigCycleTime" SG_ 985 ACC_ObsTarget3Type 100;
BA_ "GenSigCycleTime" SG_ 985 ACC_ObsTarget3LatRange 100;
BA_ "GenSigStartValue" SG_ 985 ACC_ObsTarget3LatRange 1023.000000;
BA_ "GenSigCycleTime" SG_ 985 ACC_ObsTarget3LngRange 100;
BA_ "GenSigStartValue" SG_ 985 ACC_ObsTarget3LngRange 2047.000000;
BA_ "GenSigCycleTime" SG_ 985 ACC_ObsTarget2ID 100;
BA_ "GenSigCycleTime" SG_ 985 ACC_ObsTarget2Type 100;
BA_ "GenSigCycleTime" SG_ 985 ACC_ObsTarget2LatRange 100;
BA_ "GenSigStartValue" SG_ 985 ACC_ObsTarget2LatRange 1023.000000;
BA_ "GenSigCycleTime" SG_ 985 ACC_ObsTarget2LngRange 100;
BA_ "GenSigStartValue" SG_ 985 ACC_ObsTarget2LngRange 2047.000000;
BA_ "GenSigCycleTime" SG_ 985 ACC_ObsTarget1ID 100;
BA_ "GenSigCycleTime" SG_ 985 ACC_ObsTarget1Type 100;
BA_ "GenSigCycleTime" SG_ 985 ACC_ObsTarget1LatRange 100;
BA_ "GenSigStartValue" SG_ 985 ACC_ObsTarget1LatRange 1023.000000;
BA_ "GenSigCycleTime" SG_ 985 ACC_ObsTarget1LngRange 100;
BA_ "GenSigStartValue" SG_ 985 ACC_ObsTarget1LngRange 2047.000000;

BA_ "GenSigCycleTime" SG_ 987 ACC_ObsTarget20ID 100;
BA_ "GenSigCycleTime" SG_ 987 ACC_ObsTarget20Type 100;
BA_ "GenSigCycleTime" SG_ 987 ACC_ObsTarget20LatRange 100;
BA_ "GenSigStartValue" SG_ 987 ACC_ObsTarget20LatRange 1023.000000;
BA_ "GenSigCycleTime" SG_ 987 ACC_ObsTarget20LngRange 100;
BA_ "GenSigStartValue" SG_ 987 ACC_ObsTarget20LngRange 2047.000000;
BA_ "GenSigCycleTime" SG_ 987 ACC_ObsTarget19ID 100;
BA_ "GenSigCycleTime" SG_ 987 ACC_ObsTarget19Type 100;
BA_ "GenSigCycleTime" SG_ 987 ACC_ObsTarget19LatRange 100;
BA_ "GenSigStartValue" SG_ 987 ACC_ObsTarget19LatRange 1023.000000;
BA_ "GenSigCycleTime" SG_ 987 ACC_ObsTarget19LngRange 100;
BA_ "GenSigStartValue" SG_ 987 ACC_ObsTarget19LngRange 2047.000000;
BA_ "GenSigCycleTime" SG_ 987 ACC_ObsTarget18ID 100;
BA_ "GenSigCycleTime" SG_ 987 ACC_ObsTarget18Type 100;
BA_ "GenSigCycleTime" SG_ 987 ACC_ObsTarget18LatRange 100;
BA_ "GenSigStartValue" SG_ 987 ACC_ObsTarget18LatRange 1023.000000;
BA_ "GenSigCycleTime" SG_ 987 ACC_ObsTarget18LngRange 100;
BA_ "GenSigStartValue" SG_ 987 ACC_ObsTarget18LngRange 2047.000000;
BA_ "GenSigCycleTime" SG_ 987 ACC_ObsTarget17ID 100;
BA_ "GenSigCycleTime" SG_ 987 ACC_ObsTarget17Type 100;
BA_ "GenSigCycleTime" SG_ 987 ACC_ObsTarget17LatRange 100;
BA_ "GenSigStartValue" SG_ 987 ACC_ObsTarget17LatRange 1023.000000;
BA_ "GenSigCycleTime" SG_ 987 ACC_ObsTarget17LngRange 100;
BA_ "GenSigStartValue" SG_ 987 ACC_ObsTarget17LngRange 2047.000000;
BA_ "GenSigCycleTime" SG_ 987 ACC_ObsTarget16ID 100;
BA_ "GenSigCycleTime" SG_ 987 ACC_ObsTarget16Type 100;
BA_ "GenSigCycleTime" SG_ 987 ACC_ObsTarget16LatRange 100;
BA_ "GenSigStartValue" SG_ 987 ACC_ObsTarget16LatRange 1023.000000;
BA_ "GenSigCycleTime" SG_ 987 ACC_ObsTarget16LngRange 100;
BA_ "GenSigStartValue" SG_ 987 ACC_ObsTarget16LngRange 2047.000000;
BA_ "GenSigCycleTime" SG_ 987 ACC_ObsTarget15ID 100;
BA_ "GenSigCycleTime" SG_ 987 ACC_ObsTarget15Type 100;
BA_ "GenSigCycleTime" SG_ 987 ACC_ObsTarget15LatRange 100;
BA_ "GenSigStartValue" SG_ 987 ACC_ObsTarget15LatRange 1023.000000;
BA_ "GenSigCycleTime" SG_ 987 ACC_ObsTarget15LngRange 100;
BA_ "GenSigStartValue" SG_ 987 ACC_ObsTarget15LngRange 2047.000000;
BA_ "GenSigCycleTime" SG_ 987 ACC_ObsTarget14ID 100;
BA_ "GenSigCycleTime" SG_ 987 ACC_ObsTarget14Type 100;
BA_ "GenSigCycleTime" SG_ 987 ACC_ObsTarget14LatRange 100;
BA_ "GenSigStartValue" SG_ 987 ACC_ObsTarget14LatRange 1023.000000;
BA_ "GenSigCycleTime" SG_ 987 ACC_ObsTarget14LngRange 100;
BA_ "GenSigStartValue" SG_ 987 ACC_ObsTarget14LngRange 2047.000000;
BA_ "GenSigCycleTime" SG_ 987 ACC_ObsTarget13ID 100;
BA_ "GenSigCycleTime" SG_ 987 ACC_ObsTarget13Type 100;
BA_ "GenSigCycleTime" SG_ 987 ACC_ObsTarget13LatRange 100;
BA_ "GenSigStartValue" SG_ 987 ACC_ObsTarget13LatRange 1023.000000;
BA_ "GenSigCycleTime" SG_ 987 ACC_ObsTarget13LngRange 100;
BA_ "GenSigStartValue" SG_ 987 ACC_ObsTarget13LngRange 2047.000000;
BA_ "GenSigCycleTime" SG_ 987 ACC_ObsTarget12ID 100;
BA_ "GenSigCycleTime" SG_ 987 ACC_ObsTarget12Type 100;
BA_ "GenSigCycleTime" SG_ 987 ACC_ObsTarget12LatRange 100;
BA_ "GenSigStartValue" SG_ 987 ACC_ObsTarget12LatRange 1023.000000;
BA_ "GenSigCycleTime" SG_ 987 ACC_ObsTarget12LngRange 100;
BA_ "GenSigStartValue" SG_ 987 ACC_ObsTarget12LngRange 2047.000000;
BA_ "GenSigCycleTime" SG_ 987 ACC_ObsTarget11ID 100;
BA_ "GenSigCycleTime" SG_ 987 ACC_ObsTarget11Type 100;
BA_ "GenSigCycleTime" SG_ 987 ACC_ObsTarget11LatRange 100;
BA_ "GenSigStartValue" SG_ 987 ACC_ObsTarget11LatRange 1023.000000;
BA_ "GenSigCycleTime" SG_ 987 ACC_ObsTarget11LngRange 100;
BA_ "GenSigStartValue" SG_ 987 ACC_ObsTarget11LngRange 2047.000000;

BA_ "GenSigCycleTime" SG_ 881 PCU_DrvMod2 100;
BA_ "GenSigCycleTime" SG_ 881 PCU_SpecialModeSetFB 100;

BA_ "GenSigCycleTime" SG_ 796 PCU_VcuRdySts 100;
BA_ "GenSigInvalidValue" SG_ 796 PCU_VcuRdySts "NA";
BA_ "GenSigCycleTime" SG_ 796 PCU_PowerOutputSts 100;

BA_ "GenSigCycleTime" SG_ 266 EPB_RollingCounter_10A 10;
BA_ "GenSigCycleTime" SG_ 266 EPB_CRCCheck_10A 10;
BA_ "GenSigCycleTime" SG_ 266 EPB_SwitchPosition 10;
BA_ "GenSigInvalidValue" SG_ 266 EPB_SwitchPosition "3";
BA_ "GenSigCycleTime" SG_ 266 EPB_Status 10;
BA_ "GenSigCycleTime" SG_ 266 EPB_FailStatus 10;
BA_ "GenSigCycleTime" SG_ 266 EPB_AchievedClampForce 10;
BA_ "GenSigStartValue" SG_ 266 EPB_AchievedClampForce 29.000000;
BA_ "GenSigInvalidValue" SG_ 266 EPB_AchievedClampForce "31";

BA_ "GenSigCycleTime" SG_ 879 LAS_OverspeedWarningRatioOffset_EU 100;
BA_ "GenSigStartValue" SG_ 879 LAS_OverspeedWarningRatioOffset_EU 47.000000;
BA_ "GenSigCycleTime" SG_ 879 LAS_TSRSpeedLimitChangeSoundEnSt 100;
BA_ "GenSigInvalidValue" SG_ 879 LAS_TSRSpeedLimitChangeSoundEnSt "0";
BA_ "GenSigCycleTime" SG_ 879 LAS_TSRSpeedLimitStatus 100;
BA_ "GenSigCycleTime" SG_ 879 LAS_TSRNavCountryCode 100;
BA_ "GenSigInvalidValue" SG_ 879 LAS_TSRNavCountryCode "0";

BA_ "GenSigCycleTime" SG_ 349 ESP_IMUCalibrated 20;
BA_ "GenSigCycleTime" SG_ 349 ESP_YawRateValid 20;
BA_ "GenSigCycleTime" SG_ 349 ESP_LatAccelValid 20;
BA_ "GenSigCycleTime" SG_ 349 ESP_LongAccelValid 20;
BA_ "GenSigCycleTime" SG_ 349 ESP_YawRate 20;
BA_ "GenSigInvalidValue" SG_ 349 ESP_YawRate "16383";
BA_ "GenSigCycleTime" SG_ 349 ESP_RollingCounter_278 20;
BA_ "GenSigCycleTime" SG_ 349 ESP_LongAccel 20;
BA_ "GenSigInvalidValue" SG_ 349 ESP_LongAccel "1023";
BA_ "GenSigCycleTime" SG_ 349 ESP_LatAccel 20;
BA_ "GenSigInvalidValue" SG_ 349 ESP_LatAccel "255";
BA_ "GenSigCycleTime" SG_ 349 ESP_CRCCheck_278 20;

BA_ "GenSigCycleTime" SG_ 271 IBCU_RollingCounter_1CB 20;
BA_ "GenSigCycleTime" SG_ 271 IBCU_sOutputRodAct_Q 20;
BA_ "GenSigCycleTime" SG_ 271 IBCU_sOutputRodAct 20;
BA_ "GenSigCycleTime" SG_ 271 IBCU_sOutputRodDriver_Q 20;
BA_ "GenSigCycleTime" SG_ 271 IBCU_sOutputRodDriver 20;

BA_ "GenSigCycleTime" SG_ 810 TRM_ConnectSts 100;
BA_ "GenSigInvalidValue" SG_ 810 TRM_ConnectSts "NA";

BA_ "GenSigCycleTime" SG_ 1323 ACC_Target1LatRelSpeed 100;
BA_ "GenSigStartValue" SG_ 1323 ACC_Target1LatRelSpeed 512.000000;
BA_ "GenSigInvalidValue" SG_ 1323 ACC_Target1LatRelSpeed "1024";

BA_ "GenSigCycleTime" SG_ 1330 ACC_Target2LatRelSpeed 100;
BA_ "GenSigStartValue" SG_ 1330 ACC_Target2LatRelSpeed 512.000000;
BA_ "GenSigInvalidValue" SG_ 1330 ACC_Target2LatRelSpeed "1024";

BA_ "GenSigCycleTime" SG_ 1331 ADS_IACC_LatTakeOverReason 100;
BA_ "GenSigCycleTime" SG_ 1331 ACC_RLaneQuality 100;
BA_ "GenSigCycleTime" SG_ 1331 ACC_DOSECountDown 100;
BA_ "GenSigCycleTime" SG_ 1331 ACC_Target7LatRelSpeed 100;
BA_ "GenSigStartValue" SG_ 1331 ACC_Target7LatRelSpeed 512.000000;
BA_ "GenSigInvalidValue" SG_ 1331 ACC_Target7LatRelSpeed "1024";
BA_ "GenSigCycleTime" SG_ 1331 ACC_Target6LatRelSpeed 100;
BA_ "GenSigStartValue" SG_ 1331 ACC_Target6LatRelSpeed 512.000000;
BA_ "GenSigInvalidValue" SG_ 1331 ACC_Target6LatRelSpeed "1024";
BA_ "GenSigCycleTime" SG_ 1331 ACC_Target5LatRelSpeed 100;
BA_ "GenSigStartValue" SG_ 1331 ACC_Target5LatRelSpeed 512.000000;
BA_ "GenSigInvalidValue" SG_ 1331 ACC_Target5LatRelSpeed "1024";
BA_ "GenSigCycleTime" SG_ 1331 ACC_Target4LatRelSpeed 100;
BA_ "GenSigStartValue" SG_ 1331 ACC_Target4LatRelSpeed 512.000000;
BA_ "GenSigInvalidValue" SG_ 1331 ACC_Target4LatRelSpeed "1024";
BA_ "GenSigCycleTime" SG_ 1331 ACC_Target3LatRelSpeed 100;
BA_ "GenSigStartValue" SG_ 1331 ACC_Target3LatRelSpeed 512.000000;
BA_ "GenSigInvalidValue" SG_ 1331 ACC_Target3LatRelSpeed "1024";

BA_ "GenSigSendType" SG_ 429 GW_Authernticator_1AD 1;
BA_ "GenSigSendType" SG_ 429 GW_ResetCounter_1AD 1;
BA_ "GenSigSendType" SG_ 429 GW_TripCounter_1AD 1;

BA_ "GenSigSendType" SG_ 375 LAS_ReqSYNMSG 1;

BA_ "GenSigSendType" SG_ 1488 KeyLearn_Authernticator_5D0 1;
BA_ "GenSigStartValue" SG_ 1488 KeyLearn_Authernticator_5D0 1.000000;
BA_ "GenSigSendType" SG_ 1488 KeyLearn_Random_5D0 1;
BA_ "GenSigStartValue" SG_ 1488 KeyLearn_Random_5D0 1.000000;

BA_ "GenSigSendType" SG_ 1492 KeyLearn_Authernticator_5D4 1;
BA_ "GenSigStartValue" SG_ 1492 KeyLearn_Authernticator_5D4 1.000000;
BA_ "GenSigSendType" SG_ 1492 KeyLearn_Random_5D4 1;
BA_ "GenSigStartValue" SG_ 1492 KeyLearn_Random_5D4 1.000000;

BA_ "GenSigSendType" SG_ 2015 Diagnose_message7DF 1;

BA_ "GenSigSendType" SG_ 1891 Diagnose_message763 1;

BA_ "GenSigSendType" SG_ 1899 Diagnose_message76B 1;

BA_ "GenSigCycleTime" SG_ 583 APA_APAOnOff 20;

BA_ "GenSigCycleTime" SG_ 710 APA_vehicleFrontdetect 40;
BA_ "GenSigInvalidValue" SG_ 710 APA_vehicleFrontdetect "3";

BA_ "GenSigCycleTime" SG_ 953 BDC_TurnLightSw 100;
BA_ "GenSigInvalidValue" SG_ 953 BDC_TurnLightSw "0";

BA_ "GenSigCycleTime" SG_ 901 HU_CDCUnitSystSetStatus 100;
BA_ "GenSigStartValue" SG_ 901 HU_CDCUnitSystSetStatus 1.000000;

BA_ "GenSigCycleTime" SG_ 456 ESP_EngTorqIncRearActive 10;

VAL_ 943 HU_RampInfo_EU 0 "Unknown" 1 "本车通过该匝道" 2 "本车不通过该匝道" 3 "reserved";
VAL_ 943 HU_MaxNavSpeed 0 "Unlimited" 1 "SL 5" 2 "SL 10" 32 "SL 160" 33 "SL 165" 34 "SL 170" 35 "SL 175" 36 "SL 180" 254 "Unknown" 255 "Invalid";
VAL_ 943 HU_MapStatus 0 "Invalid" 1 "Active" 2 "Initiallzation Not Complete" 3 "Map Data Missing" 4 "Vehicle Off Road" 5 " Other Fault" 6 "reserved";
VAL_ 943 HU_NavSpeedLimit_EU 0 "Unlimited" 1 "SL 5" 2 "SL 10" 32 "SL 160" 33 "SL 165" 34 "SL 170" 35 "SL 175" 36 "SL 180" 254 "Unknown" 255 "Invalid";
VAL_ 943 HU_ForwardRoadType_EU 0 "未知" 1 "封闭式高速公路" 2 "高速公路" 3 "城市快速路" 4 "城市主干道" 5 "一般道路、步行道路、小巷道" 6 "预留" 7 "无效";
VAL_ 943 HU_NavCurrentRoadType_EU 0 "未知" 1 "封闭式高速公路" 2 "高速公路" 3 "城市快速路" 4 "城市主干道" 5 "一般道路、步行道路、小巷道" 6 "预留" 7 "无效";
VAL_ 943 HU_NavCountryCode_EU 0 "Unknown" 1 "Afghanistan" 2 "Albania" 3 "Algeria" 4 "American Samoa" 5 "Andorra" 6 "Angola" 7 "Anguilla" 8 "Antarctica" 9 "Antigua and Barbuda" 10 "Argentina" 11 "Armenia" 12 "Aruba" 13 "Australia" 14 "Austria" 15 "Azerbaijan" 16 "Bahamas" 17 "Bahrain" 18 "Bangladesh" 19 "Barbados" 20 "Belarus" 21 "Belgium" 22 "Belize" 23 "Benin" 24 "Bermuda" 25 "Bhutan" 26 "Bolivia" 27 "Bosnia and Herzegovina" 28 "Botswana" 29 "Bouvet Island" 30 "Brazil" 31 "British Indian Ocean Territory" 32 "Brunei Darussalam" 33 "Bulgaria" 34 "Burkina Faso" 35 "Burundi" 36 "Cambodia" 37 "Cameroon" 38 "Canada" 39 "Cabo Verde" 40 "Cayman Islands" 41 "Central African Republic" 42 "Chad" 43 "Chile" 44 "China" 45 "Christmas Island" 46 "Cocos (Keeling) Islands" 47 "Colombia" 48 "Comoros" 49 "Congo" 50 "Congo (Democratic Republic of the)" 51 "Cook Islands" 52 "Costa Rica" 53 "C?te d'Ivoire" 54 "Croatia" 55 "Cuba" 56 "Cyprus" 57 "Czech Republic" 58 "Denmark" 59 "Djibouti" 60 "Dominica" 61 "Dominican Republic" 62 "Timor-Leste (East Timor)" 63 "Ecuador" 64 "Egypt" 65 "El Salvador" 66 "Equatorial Guinea" 67 "Eritrea" 68 "Estonia" 69 "Ethiopia" 70 "Falkland Islands (Malvinas)" 71 "Faroe Islands" 72 "Fiji" 73 "Finland" 74 "France" 75 "FRANCE_METROPOLITAN currently not used France is coded as FRANCE" 76 "French Guiana" 77 "French Polynesia" 78 "French Southern Territories" 79 "Gabon" 80 "Gambia" 81 "Georgia" 82 "Germany" 83 "Ghana" 84 "Gibraltar" 85 "Greece" 86 "Greenland" 87 "Grenada" 88 "Guadeloupe" 89 "Guam" 90 "Guatemala" 91 "Guinea" 92 "Guinea-Bissau" 93 "Guyana" 94 "Haiti" 95 "Heard Island and McDonald Islands" 96 "Honduras" 97 "Hong Kong" 98 "Hungary" 99 "Iceland" 100 "India" 101 "Indonesia" 102 "Iran (Islamic Republic of)" 103 "Iraq" 104 "Ireland" 105 "Israel" 106 "Italy" 107 "Jamaica" 108 "Japan" 109 "Jordan" 110 "Kazakhstan" 111 "Kenya" 112 "Kiribati" 113 "Korea (Democratic People's Republic of)" 114 "Korea (Republic of)" 115 "Kuwait" 116 "Kyrgyzstan" 117 "Lao People's Democratic Republic" 118 "Latvia" 119 "Lebanon" 120 "Lesotho" 121 "Liberia" 122 "Libya" 123 "Liechtenstein" 124 "Lithuania" 125 "Luxembourg" 126 "Macao" 127 "Macedonia (the former Yugoslav Republic of)" 128 "Madagascar" 129 "Malawi" 130 "Malaysia" 131 "Maldives" 132 "Mali" 133 "Malta" 134 "Marshall Islands" 135 "Martinique" 136 "Mauritania" 137 "Mauritius" 138 "Mayotte" 139 "Mexico" 140 "Micronesia (Federated States of)" 141 "Moldova (Republic of)" 142 "Monaco" 143 "Mongolia" 144 "Montserrat" 145 "Morocco" 146 "Mozambique" 147 "Myanmar" 148 "Namibia" 149 "Nauru" 150 "Nepal" 151 "Netherlands" 152 "NETHERLANDS_ANTILLES" 153 "New Caledonia" 154 "New Zealand" 155 "Nicaragua" 156 "Niger" 157 "Nigeria" 158 "Niue" 159 "Norfolk Island" 160 "Northern Mariana Islands" 161 "Norway" 162 "Oman" 163 "Pakistan" 164 "Palau" 165 "Palestine, State of" 166 "Panama" 167 "Papua New Guinea" 168 "Paraguay" 169 "Peru" 170 "Philippines" 171 "Pitcairn" 172 "Poland" 173 "Portugal" 174 "Puerto Rico" 175 "Qatar" 176 "R?union" 177 "Romania" 178 "Russian Federation" 179 "Rwanda" 180 "Saint Kitts and Nevis" 181 "Saint Lucia" 182 "Saint Vincent and the Grenadines" 183 "Samoa" 184 "San Marino" 185 "Sao Tome and Principe" 186 "Saudi Arabia" 187 "Senegal" 188 "Seychelles" 189 "Sierra Leone" 190 "Singapore" 191 "Slovakia" 192 "Slovenia" 193 "Solomon Islands" 194 "Somalia" 195 "South Africa" 196 "South Georgia and the South Sandwich Islands" 197 "Spain" 198 "Sri Lanka" 199 "Saint Helena, Ascension and Tristan da Cunha" 200 "Saint Pierre and Miquelon" 201 "Sudan" 202 "Suriname" 203 "Svalbard and Jan Mayen" 204 "Swaziland" 205 "Sweden" 206 "Switzerland" 207 "Syrian Arab Republic" 208 "Taiwan, Province of China" 209 "Tajikistan" 210 "Tanzania, United Republic of" 211 "Thailand" 212 "Togo" 213 "Tokelau" 214 "Tonga" 215 "Trinidad and Tobago" 216 "Tunisia" 217 "Turkey" 218 "Turkmenistan" 219 "Turks and Caicos Islands" 220 "Tuvalu" 221 "Uganda" 222 "Ukraine" 223 "United Arab Emirates" 224 "United Kingdom of Great Britain and Northern Ireland" 225 "United States of America" 226 "United States Minor Outlying Islands" 227 "Uruguay" 228 "Uzbekistan" 229 "Vanuatu" 230 "VATICAN" 231 "Venezuela (Bolivarian Republic of)" 232 "Viet Nam" 233 "Virgin Islands (British)" 234 "Virgin Islands (U.S.)" 235 "Wallis and Futuna" 236 "Western Sahara" 237 "Yemen" 238 "Serbia" 239 "Zambia" 240 "Zimbabwe" 241 "CROATIA2" 242 "MACEDONIA2" 243 "BOSNIA_HERZEGOVINA" 244 "Montenegro" 245 "South Sudan" 246 "Guernsey" 247 "Jersey" 248 "Isle of Man" 249 "?land Islands" 250 "Kosovo" 251 "reserved";
VAL_ 943 HU_realtimeNavRoadSpeedLimitType 0 "unknown" 1 "显式限速" 2 "隐式限速" 3 "时间限速";
VAL_ 943 HU_realtimeNavSpeedLimit 0 "Unlimited" 1 "SL 5" 2 "SL 10" 32 "SL 160" 33 "SL 165" 34 "SL 170" 35 "SL 175" 36 "SL 180" 254 "Unknown" 255 "Invalid";
VAL_ 943 HU_FogSpeedLimit 0 "Unlimited" 1 "SL 5" 2 "SL 10" 32 "SL 160" 33 "SL 165" 34 "SL 170" 35 "SL 175" 36 "SL 180" 254 "Unknown" 255 "Invalid";
VAL_ 943 HU_NavRoadSpeedLimitType 0 "unknown" 1 "显式限速" 2 "隐式限速" 3 "时间限速";
VAL_ 943 HU_SnowSpeedLimit 0 "Unlimited" 1 "SL 5" 2 "SL 10" 32 "SL 160" 33 "SL 165" 34 "SL 170" 35 "SL 175" 36 "SL 180" 254 "Unknown" 255 "Invalid";
VAL_ 943 HU_RainSpeedLimit 0 "Unlimited" 1 "SL 5" 2 "SL 10" 32 "SL 160" 33 "SL 165" 34 "SL 170" 35 "SL 175" 36 "SL 180" 254 "Unknown" 255 "Invalid";
VAL_ 943 HU_LaneConfluenceDis 0 " 0~600m" 61 "Out of Range" 62 "reserved" 63 "unknown";
VAL_ 943 HU_LaneConfluence 0 "unknown" 1 "前方左侧合流" 2 "前方右侧合流
0x3=invalid";
VAL_ 943 HU_IntervalVelocityDis 0 " 0~600m" 61 "Out of Range" 62 "reserved" 63 "unknown";
VAL_ 943 HU_IntervalVelocityInfo 0 " unknown" 1 "区间测速起始点" 2 "区间测速结束点
0x3=reserved";
VAL_ 943 HU_RampDistance 0 " 0~3000m" 301 "reserved" 1022 "Out of Range" 1023 "unknown";
VAL_ 943 HU_CurveDistance 0 " 0~600m" 61 "Out of Range" 62 "reserved" 63 "unknown";
VAL_ 943 HU_EnterCurveInfo 0 " unknown" 1 "弯道进口" 2 "弯道中" 3 "弯道出口";
VAL_ 943 HU_EnterRampInfo 0 "Unknown" 1 "匝道进口" 2 "匝道中" 3 "匝道出口";
VAL_ 943 HU_NavStatus 0 "Normal" 1 "Error";
VAL_ 943 HU_NavSpeedLimitUnits 3 "reserved" 2 "unit mph" 1 "unit kph" 0 "unknown.";
VAL_ 943 HU_NavSpeedLimitStatus 3 "reserved" 2 "reserved" 1 "invalid" 0 "valid";
VAL_ 943 HU_SlopeGradientFar 1023 " unknown";
VAL_ 943 HU_SlopeGradient 1023 " unknown";
VAL_ 943 HU_SpeedLimitDistance 0 " 0~600m" 61 "Out of Range" 62 "reserved" 63 "unknown";

VAL_ 947 BCM_BrakeLampError 0 "无故障" 1 "有故障";
VAL_ 947 BCM_RearFoglampStatus 0 "OFF" 1 "ON" 2 "Not used" 3 "Error";

VAL_ 957 HU_SentryModeSt 0 "off" 1 "哨兵模式准备" 2 "哨兵模式开启中" 3 "主动哨兵模式开启" 4 "主动哨兵模式激活" 5 "充电哨兵模式激活";
VAL_ 957 HU_CSLAEnable 0 "OFF" 1 "All Speed-Limit" 2 "Road Camera" 3 "invalid";
VAL_ 957 HU_TLAEnable 0 "Inactive" 1 "OFF" 2 "ON" 3 "Reserved";

VAL_ 964 HU_BSDLCAMode 0 "inactive" 1 "Light" 2 "Light+Vibration" 3 "Light+Voice" 4 "OFF" 5 "Reserved" 6 "Reserved" 7 "Invalid";
VAL_ 964 HU_MapDataUpdateStatus 0 "未更新" 1 "1个月内更新" 2 "3个月内更新" 3 "6个月内更新" 4 "1年内更新" 5 " reserved" 7 "Invalid";
VAL_ 964 HU_RoadCurvature_600m 0 " -0.16192 ~ -0.00001，负数代表向左的弯道曲率" 8191 " 0，代表曲率为0的直道" 512 " 0.00001 ~ 0.16192，正数代表向右的弯道曲率" 5631 " unknown";
VAL_ 964 HU_RoadCurvature_400m 0 " -0.16192 ~ -0.00001，负数代表向左的弯道曲率" 8191 " 0，代表曲率为0的直道" 512 " 0.00001 ~ 0.16192，正数代表向右的弯道曲率" 5375 " unknown";
VAL_ 964 HU_RoadCurvature_300m 0 " -0.16192 ~ -0.00001，负数代表向左的弯道曲率" 8191 " 0，代表曲率为0的直道" 512 " 0.00001 ~ 0.16192，正数代表向右的弯道曲率" 5119 " unknown";
VAL_ 964 HU_RoadCurvature_100m 0 " -0.16192 ~ -0.00001，负数代表向左的弯道曲率" 8191 " 0，代表曲率为0的直道" 512 " 0.00001 ~ 0.16192，正数代表向右的弯道曲率" 4863 " unknown";
VAL_ 964 HU_RoadCurvature_90m 0 " -0.16192 ~ -0.00001，负数代表向左的弯道曲率" 8191 " 0，代表曲率为0的直道" 512 " 0.00001 ~ 0.16192，正数代表向右的弯道曲率" 4607 " unknown";
VAL_ 964 HU_RoadCurvature_80m 0 " -0.16192 ~ -0.00001，负数代表向左的弯道曲率" 8191 " 0，代表曲率为0的直道" 512 " 0.00001 ~ 0.16192，正数代表向右的弯道曲率" 4351 " unknown";
VAL_ 964 HU_RoadCurvature_70m 0 " -0.16192 ~ -0.00001，负数代表向左的弯道曲率" 8191 " 0，代表曲率为0的直道" 512 " 0.00001 ~ 0.16192，正数代表向右的弯道曲率" 2559 " unknown";
VAL_ 964 HU_RoadCurvature_60m 0 " -0.16192 ~ -0.00001，负数代表向左的弯道曲率" 8191 " 0，代表曲率为0的直道" 512 " 0.00001 ~ 0.16192，正数代表向右的弯道曲率" 2303 " unknown";
VAL_ 964 HU_RoadCurvature_50m 0 " -0.16192 ~ -0.00001，负数代表向左的弯道曲率" 8191 " 0，代表曲率为0的直道" 512 " 0.00001 ~ 0.16192，正数代表向右的弯道曲率" 2047 " unknown";
VAL_ 964 HU_RoadCurvature_40m 0 " -0.16192 ~ -0.00001，负数代表向左的弯道曲率" 8191 " 0，代表曲率为0的直道" 512 " 0.00001 ~ 0.16192，正数代表向右的弯道曲率" 1791 " unknown";
VAL_ 964 HU_RoadCurvature_30m 0 " -0.16192 ~ -0.00001，负数代表向左的弯道曲率" 8191 " 0，代表曲率为0的直道" 512 " 0.00001 ~ 0.16192，正数代表向右的弯道曲率" 1535 " unknown";
VAL_ 964 HU_RoadCurvature_20m 0 " -0.16192 ~ -0.00001，负数代表向左的弯道曲率" 8191 " 0，代表曲率为0的直道" 512 " 0.00001 ~ 0.16192，正数代表向右的弯道曲率" 1279 " unknown";
VAL_ 964 HU_RoadCurvature_10m 0 " -0.16192 ~ -0.00001，负数代表向左的弯道曲率" 8191 " 0，代表曲率为0的直道" 512 " 0.00001 ~ 0.16192，正数代表向右的弯道曲率" 1023 " unknown";
VAL_ 964 HU_Road_TrafficFlow 0 "unknown" 1 "畅通" 2 "缓行" 3 " 拥堵，0x4=严重拥堵，0x5=无交通流,0x6=reserved.0x7=invalid";
VAL_ 964 HU_To_Construction_Dis 0 " 0~600m" 61 "Out of Range" 62 "reserved" 63 "unknown";
VAL_ 964 HU_Construction_Info 0 "路径无施工区" 1 "路径有施工区" 2 "预留
0x3=invalid";
VAL_ 964 HU_RampSide 0 "Unknown" 1 "道路左边" 2 "道路右边" 3 "直线匝道";
VAL_ 964 HU_NavGuiganceStatus 0 "没有导航引导路径" 1 "有导航引导路径" 2 "Reserved" 3 "Reserved";
VAL_ 964 HU_TunnelLength 0 " 0~600m" 61 "Out of Range" 62 "reserved" 63 "unknown";
VAL_ 964 HU_RoadCurvatureFar 0 " -0.16192 ~ -0.00001，负数代表向左的弯道曲率" 8191 " 0，代表曲率为0的直道" 512 " 0.00001 ~ 0.16192，正数代表向右的弯道曲率" 1023 " unknown";
VAL_ 964 HU_TunnelDistance 0 " 0~600m" 61 "Out of Range" 62 "reserved" 63 "unknown";
VAL_ 964 HU_RoadCurvature 0 " -0.16192 ~ -0.00001，负数代表向左的弯道曲率" 8191 " 0，代表曲率为0的直道" 512 " 0.00001 ~ 0.16192，正数代表向右的弯道曲率" 1023 " unknown";
VAL_ 964 HU_EnterTunnelInfo 0 " unknown" 1 "隧道入口" 2 "隧道中" 3 "隧道出口";

VAL_ 1021 BCM_DriveMode 0 "Normal" 1 "Eco" 2 "Sport  " 3 "Snow" 4 "Sport+" 5 "Smart" 6 "Race" 7 "Reserved" 15 "Invalid";
VAL_ 1021 BCM_PowerManageLevel 0 "Valid" 1 "Level1" 2 " Level2" 3 " Level3" 4 " Level4" 5 "Reserve" 7 "Invalid";

VAL_ 1023 BCM_AutoHeadlightSts 0 "Not Actived" 1 "Actived";
VAL_ 1023 BCM_FrontFoglampStatus 0 "OFF" 1 "ON" 2 "Not used" 3 "Reserved";

VAL_ 1310 TPMS_TirePosition 0 "No any sensor" 1 "Left Front tire.
0x2=Right Front tire" 3 "Right Rear tire.
0x4=Left Rear tire" 5 "reseved.";

VAL_ 652 GW_MFS_DiagInfoSW_28C 0 "复位" 1 "变种信息错误" 2 "电源高于16V" 3 "电源低于9V" 4 "reversed" 7 "invalid";
VAL_ 652 GW_MFS_IACCenable_switch_signal 0 "按键未按下" 1 "按键按下" 2 "假按键" 3 "Error";
VAL_ 652 GW_MFS_DIST_switch_signal 0 "按键未按下" 1 "按键按下" 2 "假按键" 3 "Error";
VAL_ 652 GW_MFS_SETReduce_switch_signal 0 "按键未按下" 1 "按键按下" 2 "假按键" 3 "Error";
VAL_ 652 GW_MFS_RESPlus_switch_signal 0 "按键未按下" 1 "按键按下" 2 "假按键" 3 "Error";
VAL_ 652 GW_MFS_Cancle_switch_signal 0 "按键未按下" 1 "按键按下" 2 "假按键" 3 "Error";
VAL_ 652 GW_MFS_Crusie_switch_signal 0 "按键未按下" 1 "按键按下" 2 "假按键" 3 "Error";
VAL_ 652 GW_MFS_DISTReduce_switch_signal 0 "按键未按下" 1 "按键按下" 2 "假按键" 3 "Error";
VAL_ 652 GW_MFS_DISTPlus_switch_signal 0 "按键未按下" 1 "按键按下" 2 "假按键" 3 "Error";

VAL_ 817 TCU_TransFaultLevel 0 "Normal" 1 "Fault level1(just store DTC)" 2 "Fault level2(store DTC&warning)" 3 "Fault level3(Limphome)" 4 "Fault level4(No DCT Shaft)" 5 "Fault level5(Drive open)";

VAL_ 431 TCU_ShiftPostionValid 0 "valid" 1 "invalid";
VAL_ 431 TCU_ShiftInProgressVld 0 "Invalid" 1 "Valid";
VAL_ 431 TCU_ShiftInProgress 0 "Not shifting" 1 "Shifting";
VAL_ 431 TCU_GearShiftPosition 0 "Parking" 1 "Reverse" 2 "Neutral" 3 "D" 4 "D3" 5 "D2" 6 "L" 7 "M/S" 8 "Reserved" 13 " Initial value" 14 " Unreliable" 15 " Invalid";
VAL_ 431 TCU_ActualDrivingGearValid 0 "valid" 1 "invalid";
VAL_ 431 TCU_ActualDrivingGear 0 "Neutral" 1 "1st gear" 2 "2nd gear" 3 "3rd gear" 4 "4th gear" 5 "5th gear" 6 "6th gear" 7 "7th gear" 8 "8th gear" 9 "Reverse" 10 "Parking" 11 "Reserved" 13 "Reserved" 14 "Reserved" 15 "Invalid";

VAL_ 800 GW_ResetReq 0 "Valid" 1 "THU" 2 " AMP" 3 "ADS/ADC" 4 " FC/LAS" 5 "FR/ACC" 6 "FLR" 7 "FRR" 8 "RLR/LCDAL" 9 "RRR/LCDAR" 10 "LVSM" 11 "INS" 12 "APA" 13 "BCML/BCM" 14 "GW/BCMR" 15 "EMS" 16 "PCU" 17 "BMS" 18 "PEU" 19 "OBC" 20 "TCU" 21 "IPUMP" 22 "ACM" 23 "ESL" 24 "PTS" 25 "ESCL" 26 "TMS/AC" 27 "DKC/RFBT/BLEM" 28 "WLCM" 29 "EPBI" 30 "IBCU" 31 "RBM" 32 "EPS" 33 "EPS2" 34 "DSM" 35 "IP" 36 "SLCM" 37 "HUD" 38 "GPEU" 39 "PDU" 40 "RPEU" 41 "VMC" 43 "DPEU" 44 "NFC-Enter" 45 "PATC" 46 "VMC2" 47 "RCCS" 48 "TRM" 49 "PDCU" 50 "BDCR" 51 "mADC" 52 "EPB" 53 "EVCC" 54 "HLM" 55 "CTMU" 56 "HRM" 57 "RLM" 64 "PSM" 65 "TBOX" 66 "DCDC" 67 "CMS" 68 "ICRF" 69 "ICRR" 70 "EPBi2" 71 "Reserve" 127 "Invalid";

VAL_ 922 LAS_RoadFeature 0 " No Object (无目标)" 1 " Speed Bump  (减速带)" 2 "  Reserved" 3 "  Reserved" 4 "  Reserved" 5 "  Reserved" 6 "  Reserved" 15 " Invalid";
VAL_ 922 LAS_RD4LongDistence 0 "0-250m" 251 "Reserved" 255 "Out of Range";
VAL_ 922 LAS_RD3LongDistence 0 "0-250m" 251 "Reserved" 255 "Out of Range";
VAL_ 922 LAS_RD2LongDistence 0 "0-250m" 251 "Reserved" 255 "Out of Range";
VAL_ 922 LAS_RD1LongDistence 0 "0-250m" 251 "Reserved" 255 "Out of Range";
VAL_ 922 LAS_RD4RoadInforAvailable 0 " Not Available" 1 " Available Measured" 2 " Predicted" 3 " Predicted close-range outside FOV";
VAL_ 922 LAS_RD3RoadInforAvailable 0 " Not Available" 1 " Available Measured" 2 " Predicted" 3 " Predicted close-range outside FOV";
VAL_ 922 LAS_RD2RoadInforAvailable 0 " Not Available" 1 " Available Measured" 2 " Predicted" 3 " Predicted close-range outside FOV";
VAL_ 922 LAS_RD1RoadInforAvailable 0 " Not Available" 1 " Available Measured" 2 " Predicted" 3 " Predicted close-range outside FOV";
VAL_ 922 LAS_TSRSpeedLimitType 0 "Unknown" 1 "Speed-Limit Sign" 2 "Road Camera" 3 "Interval Velocity";
VAL_ 922 LAS_TSRRightLaneStatus 0 " off" 1 " fusion mode" 2 " vision only mode" 3 " navigation only mode" 4 " reserved" 5 " reserved" 6 " reserved" 7 " Invalid";
VAL_ 922 LAS_TSRLeftLaneStatus 0 " off" 1 " fusion mode" 2 " vision only mode" 3 " navigation only mode" 4 " reserved" 5 " reserved" 6 " reserved" 7 " Invalid";
VAL_ 922 LAS_TSRRightLaneSpdLimit 0 "no speed limit detected" 1 "SL5" 2 "SL10" 3 "SL15" 4 "SL20" 5 "SL25" 6 "SL30" 7 "SL35" 8 "SL40" 9 "SL45" 10 "SL50" 11 "SL55" 12 "SL60" 13 "SL65" 14 "SL70" 15 "SL75" 16 "SL80" 17 "SL85" 18 "SL90" 19 "SL95" 20 "SL100" 21 "SL105" 22 "SL110" 23 "SL115" 24 "SL120" 25 "SL125" 26 "SL130" 27 "SL135" 28 "SL140" 29 "SL145" 30 "SL150" 31 "SL155" 32 "SL160" 33 " Reserved" 254 " Unlimited" 255 " SLEND";
VAL_ 922 LAS_TSRLeftLaneSpdLimit 0 "no speed limit detected" 1 "SL5" 2 "SL10" 3 "SL15" 4 "SL20" 5 "SL25" 6 "SL30" 7 "SL35" 8 "SL40" 9 "SL45" 10 "SL50" 11 "SL55" 12 "SL60" 13 "SL65" 14 "SL70" 15 "SL75" 16 "SL80" 17 "SL85" 18 "SL90" 19 "SL95" 20 "SL100" 21 "SL105" 22 "SL110" 23 "SL115" 24 "SL120" 25 "SL125" 26 "SL130" 27 "SL135" 28 "SL140" 29 "SL145" 30 "SL150" 31 "SL155" 32 "SL160" 33 " Reserved" 254 " Unlimited" 255 " SLEND";
VAL_ 922 LAS_TLAStopLine_HostLane 0 "0-250m" 251 "Reserved" 255 "Out of Range";
VAL_ 922 LAS_TLADistance_HostLane 0 "0-250m" 251 "Reserved" 255 "Out of Range";
VAL_ 922 LAS_TLACountDownTime_HostLane 0 "no display" 1 "1-120s倒计时" 121 "reserved" 127 "out of range";
VAL_ 922 LAS_TSRMandatorySign 0 "no display" 1 "单行路(直行)" 2 "步行" 3 "干路先行" 4 "会车先行" 5 "人行横道" 6 "公交线路专用车道" 7 "机动车行驶" 8 "非机动扯行驶" 9 "靠右侧道路行驶" 10 "reserved";
VAL_ 922 LAS_TSRWarningSign 0 "no display" 1 "反向弯路" 2 "连续弯路" 3 "注意行人" 4 "注意儿童" 5 "易滑" 6 "隧道" 7 "慢行" 8 "施工" 9 "向左急转弯" 10 "向右急转弯" 11 "十字交叉路口" 12 "T形交叉右" 13 "T形交叉左" 15 "事故易发生路段" 16 "reserved";
VAL_ 922 LAS_TSRProhibitionSign 0 "no display" 1 "禁止通行" 2 "禁止驶入" 3 "禁止机动车通行" 4 "禁止向左转弯" 5 "禁止向右转弯" 6 "禁止直行" 7 "禁止掉头" 8 "禁止超车" 9 "解除禁止超车" 10 "禁止车辆临时或长时停放" 11 "禁止车辆长时停放" 12 "禁止鸣喇叭" 13 "停车让行" 14 "减速让行" 15 "会车让行" 16 "reserved";
VAL_ 922 LAS_OverspeedSoundWarningEnSt 0 "Off" 1 "On";
VAL_ 922 LAS_TSREnable 0 "off" 1 "on";
VAL_ 922 LAS_HMAEnableStatus 0 "off" 1 "on";
VAL_ 922 LAS_HMALightDistribution 0 " High beam not recommended" 1 " High beam recommended";
VAL_ 922 LAS_HMAStatus 0 " Off" 1 " Standby" 2 " Active" 3 " Failure";
VAL_ 922 LAS_TSRHostSpdLimitUnits 0 "no display" 1 "unit kph" 2 "unit mph" 3 "reserved";
VAL_ 922 LAS_TSRHostSpdLimit 0 "no speed limit detected" 1 "SL5" 2 "SL10" 3 "SL15" 4 "SL20" 5 "SL25" 6 "SL30" 7 "SL35" 8 "SL40" 9 "SL45" 10 "SL50" 11 "SL55" 12 "SL60" 13 "SL65" 14 "SL70" 15 "SL75" 16 "SL80" 17 "SL85" 18 "SL90" 19 "SL95" 20 "SL100" 21 "SL105" 22 "SL110" 23 "SL115" 24 "SL120" 25 "SL125" 26 "SL130" 27 "SL135" 28 "SL140" 29 "SL145" 30 "SL150" 31 "SL155" 32 "SL160" 33 " SL165" 34 " SL170" 35 " SL175" 36 " SL180" 37 "Reserved" 38 "Reserved" 39 "Reserved" 40 "Reserved" 41 "Reserved" 42 " Reserved" 43 " Slend-5" 44 " Slend-15" 45 " Slend-20" 46 " Slend-25" 47 " Slend-30" 48 " Slend-35" 49 " Slend-40" 50 " Slend-45" 51 " Slend-50" 52 " Slend-55" 53 " Slend-60" 54 " Slend-65" 55 " Slend-70" 56 " Slend-75" 57 " Slend-80" 58 " Slend-85" 59 " Slend-90" 60 " Slend-95" 61 " Slend-100" 62 " Slend-105" 63 " Slend-110" 64 " Slend-115" 65 " Slend-120" 66 " Slend-125" 67 " Slend-130" 68 " Slend-135" 69 " Slend-140" 70 " Slend-145" 71 " Slend-150" 72 " Slend-155" 73 " Slend-160" 74 " Slend-165" 75 " Slend-170" 76 " Slend-175" 77 " Slend-180" 78 "Reserved" 254 "Unlimited" 255 "SLEND";
VAL_ 922 LAS_TSRStatus 0 "off" 1 "fusion mode" 2 "vision only mode" 3 "navigation only mode" 4 "Failure" 5 "reserved" 6 "reserved" 7 "Invalid";
VAL_ 922 LAS_FrontCameraCalibrationStatus 0 "Calibration is ok" 1 "Calibration In Process" 2 "Calibration never done" 3 "Calibration Failed";
VAL_ 922 LAS_FrontCameraFailureStatus 0 "No Error" 1 "camera blocked" 2 "temporary failure" 3 "permanent failure";
VAL_ 922 LAS_OverspeedWarningOffset 0 "-10~20km/h" 31 "Reserved" 47 "Invalid";
VAL_ 922 LAS_OverspeedWarningEnableStatus 0 "OFF" 1 "ON";
VAL_ 922 LAS_OverspeedSoundWarning 0 " No Warning" 1 " Warning";
VAL_ 922 LAS_OverspeedVisualWarning 0 " No Warning" 1 " Warning";
VAL_ 922 LAS_TLAArrowDirection_RightLane 0 "no display" 1 "Forward" 2 "Left" 3 " Forward +Left" 4 "Right" 5 " Forward +Right" 6 "Right+Left" 7 "Left+ Forward +Right";
VAL_ 922 LAS_TLAObjectType_RightLane 0 "no display" 1 "Round" 2 "Arrow" 3 "Turn Round" 4 "X-type" 5 "Arrow+Trun
0x6-0x7=reserved";
VAL_ 922 LAS_TLAObjectStatus_RightLane 0 "no display" 1 "Lighting" 2 "Flashing" 3 " Disappear";
VAL_ 922 LAS_TLAObjectColour_RightLane 0 "no display" 1 "Red" 2 "Yellow" 3 "Green";
VAL_ 922 LAS_TLAObjectDetection_RightLane 0 "Not Detected" 1 "Detected";
VAL_ 922 LAS_TLAArrowDirection_LeftLane 0 "no display" 1 "Forward" 2 "Left" 3 " Forward +Left" 4 "Right" 5 " Forward +Right" 6 "Right+Left" 7 "Left+ Forward +Right";
VAL_ 922 LAS_TLAObjectType_LeftLane 0 "no display" 1 "Round" 2 "Arrow" 3 "Turn Round" 4 "X-type" 5 "Arrow+Trun
0x6-0x7=reserved";
VAL_ 922 LAS_TLAObjectStatus_LeftLane 0 "no display" 1 "Lighting" 2 "Flashing" 3 " Disappear";
VAL_ 922 LAS_TLAObjectColour_LeftLane 0 "no display" 1 "Red" 2 "Yellow" 3 "Green";
VAL_ 922 LAS_TLAObjectDetection_LeftLane 0 "Not Detected" 1 "Detected";
VAL_ 922 LAS_TLAArrowDirection_HostLane 0 "no display" 1 "Forward" 2 "Left" 3 " Forward +Left" 4 "Right" 5 " Forward +Right" 6 "Right+Left" 7 "Left+ Forward +Right";
VAL_ 922 LAS_TLAObjectStatus_HostLane 0 "no display" 1 "Lighting" 2 "Flashing" 3 " Disappear";
VAL_ 922 LAS_TLAObjectType_HostLane 0 "no display" 1 "Round" 2 "Arrow" 3 "Turn Round" 4 "X-type" 5 "Arrow+Trun" 6 "reserved";
VAL_ 922 LAS_TLAObjectColour_HostLane 0 "no display" 1 "Red" 2 "Yellow" 3 "Green";
VAL_ 922 LAS_TLAObjectDetection_HostLane 0 "Not Detected" 1 "Detected";
VAL_ 922 LAS_TLAWarninglevel 0 " no warning" 1 " warning level 1" 2 " warning level 2" 3 " warning level 3.";
VAL_ 922 LAS_TLAStatus 0 "OFF" 1 "Standby" 2 "Active" 3 "Failure";
VAL_ 922 LAS_TLAEnable 0 "OFF" 1 "ON";
VAL_ 922 LAS_RoadSignCenterLatRange_RLane 0 "(-8)+(0.05*X)" 321 "Reserved";
VAL_ 922 LAS_RoadSignCenterLngRange_RLane 0 "(0.1*X)m" 501 "Reserved";
VAL_ 922 LAS_RoadSignCenterLatRange_LLane 0 "(-8)+(0.05*X)" 321 "Reserved";
VAL_ 922 LAS_RoadSignCenterLngRange_LLane 0 "(0.1*X)m" 501 "Reserved";
VAL_ 922 LAS_RoadSignCenterLatRange_HLane 0 "(-8)+(0.05*X)" 321 "Reserved";
VAL_ 922 LAS_RoadSignCenterLngRange_HLane 0 "(0.1*X)m" 501 "Reserved";
VAL_ 922 LAS_CrosswalkLngRange_HLane 0 "0-250m" 251 "Reserved" 255 "Out of Range";
VAL_ 922 LAS_RoadSignType_RLane 0 "no detect" 1 "Forward" 2 "Left" 3 "Right" 4 "Turn Round to Left" 5 "Turn Round to Right" 6 "Forward +Left" 7 "Forward +Right" 8 "Forward +TurnRdToLeft" 9 "Forward +TurnRdToRight" 10 "TurnRd To Left or Right" 11 "Left +TurnRd to Left" 12 "Right +TurnRd to Right" 13 "Left +TurnRd to Right" 14 "Right +TurnRd to left" 15 "Left +Forward+Right" 16 "Left +Forward +TurnRd to Right" 17 "Right +Forward +TurnRd to Left" 18 "TurnRd to Rt+Forward +TurnRd to Lt" 19 "Reserved" 31 "invalid";
VAL_ 922 LAS_RoadSignType_LLane 0 "no detect" 1 "Forward" 2 "Left" 3 "Right" 4 "Turn Round to Left" 5 "Turn Round to Right" 6 "Forward +Left" 7 "Forward +Right" 8 "Forward +TurnRdToLeft" 9 "Forward +TurnRdToRight" 10 "TurnRd To Left or Right" 11 "Left +TurnRd to Left" 12 "Right +TurnRd to Right" 13 "Left +TurnRd to Right" 14 "Right +TurnRd to left" 15 "Left +Forward+Right" 16 "Left +Forward +TurnRd to Right" 17 "Right +Forward +TurnRd to Left" 18 "TurnRd to Rt+Forward +TurnRd to Lt" 19 "Reserved" 31 "invalid";
VAL_ 922 LAS_RoadSignType_HLane 0 "no detect" 1 "Forward" 2 "Left" 3 "Right" 4 "Turn Round to Left" 5 "Turn Round to Right" 6 "Forward +Left" 7 "Forward +Right" 8 "Forward +TurnRdToLeft" 9 "Forward +TurnRdToRight" 10 "TurnRd To Left or Right" 11 "Left +TurnRd to Left" 12 "Right +TurnRd to Right" 13 "Left +TurnRd to Right" 14 "Right +TurnRd to left" 15 "Left +Forward+Right" 16 "Left +Forward +TurnRd to Right" 17 "Right +Forward +TurnRd to Left" 18 "TurnRd to Rt+Forward +TurnRd to Lt" 19 "Reserved" 31 "invalid";

VAL_ 784 AMP_AllAlarmFailureStatus 0 "No Failure" 1 "Failure";
VAL_ 784 AMP_IPEnableAlarmFailureStatus 0 "No Failure" 1 "Failure";

VAL_ 1000 BCM_SOF_Q_STATE 0 "deviation > 15%" 1 "deviation <15%" 2 "deviation < 10%" 3 "invalid";
VAL_ 1000 BCM_SOF_Q 255 "Invalid";

VAL_ 999 BCM_Status_Temp 0 "No error" 1 "not used" 2 "HW defect (ADC defect)" 3 "LIN saturation (no HW  defect)";
VAL_ 999 BCM_T_BATT 146 "reserved" 255 "Invalid";

VAL_ 906 GW_MFS_VolReduce_switch 0 "按键未按下" 1 "按键按下" 2 "假按键" 3 "Error";
VAL_ 906 GW_MFS_VolPlus_switch 0 "按键未按下" 1 "按键按下" 2 "假按键" 3 "Error";
VAL_ 906 GW_MFS_UP_switch 0 "按键未按下" 1 "按键按下" 2 "假按键" 3 "Error";
VAL_ 906 GW_MFS_Speech_switch 0 "按键未按下" 1 "按键按下" 2 "假按键" 3 "Error";
VAL_ 906 GW_MFS_SeekPlus_switch 0 "按键未按下" 1 "按键按下" 2 "假按键" 3 "Error";
VAL_ 906 GW_MFS_Right_switch 0 "按键未按下" 1 "按键按下" 2 "假按键" 3 "Error";
VAL_ 906 GW_MFS_OK_switch 0 "按键未按下" 1 "按键按下" 2 "假按键" 3 "Error";
VAL_ 906 GW_MFS_Mute_switch 0 "按键未按下" 1 "按键按下" 2 "假按键" 3 "Error";
VAL_ 906 GW_MFS_Left_switch 0 "按键未按下" 1 "按键按下" 2 "假按键" 3 "Error";
VAL_ 906 GW_MFS_Hungup_switch_signal 0 "按键未按下" 1 "按键按下" 2 "假按键" 3 "Error";
VAL_ 906 GW_MFS_Down_switch 0 "按键未按下" 1 "按键按下" 2 "假按键" 3 "Error";
VAL_ 906 GW_MFS_Answer_switch_signal 0 "按键未按下" 1 "按键按下" 2 "假按键" 3 "Error";
VAL_ 906 GW_MFS_SeekReduce_switch 0 "按键未按下" 1 "按键按下" 2 "假按键" 3 "Error";

VAL_ 586 ESL_DriverParkRequest 0 " Driver Park Not Requested" 1 " Driver Park Requested" 2 "Reserved" 3 "Invalid";
VAL_ 586 ESL_ShiftLeverPositionrequest 0 " Center" 1 " Up" 2 " Down" 3 " Up, Up" 4 " Down, Down" 5 " Reserved" 15 " Invalid";
VAL_ 586 ESL_ShiftLeverPositionFaultSts 0 "normal" 1 "Degraded" 2 "Limphome" 3 "Fault";

VAL_ 833 PCU_PwrTqWhMinVld 0 "invalid" 1 "valid";
VAL_ 833 PCU_PwrTqWhMaxVld 0 "invalid" 1 "valid";

VAL_ 866 PCU_DrvMod 0 "reserved" 1 "纯电驱动" 2 "混合驱动" 3 "Super Race" 4 "i-X" 5 "智能驱动" 6 "特殊场景" 7 "增程模式";
VAL_ 866 PCU_DrvModVld 0 "Invalid" 1 "Valid";

VAL_ 723 ACC_CRCCheck_283 0 "0xFF，XOR value=0xFF，input data reflected=No，Result data reflected=No，check=0x48，Magic check=0xC4）";
VAL_ 723 ACC_AEBTargetLatRange_for_SRS 0 "-50-50m" 1001 "reserved";
VAL_ 723 ACC_CRCCheckr_282 0 "0xFF，XOR value=0xFF，input data reflected=No，Result data reflected=No，check=0x48，Magic check=0xC4）";
VAL_ 723 ACC_AEBTargetType_for_SRS 0 "no display" 1 "sedan" 2 "motorcycle" 3 "pedestrian" 4 "Bicycle" 5 "Bus" 6 "reserved" 7 "truck" 8 "reserved" 15 "other";
VAL_ 723 ACC_AEBTargetTTC_for_SRS 0 "0.01~2.50" 250 "Time to Impact more than 2.5s and valid" 251 "Timeout" 252 "reserve" 254 "Invaild";
VAL_ 723 ACC_AEBTargetRelSpeed_for_SRS 0 "-250-250" 501 "reserved";
VAL_ 723 ACC_AEBTargetLngRange_for_SRS 0 "-70~180" 501 "reserved" 511 "no display";
VAL_ 723 ACC_AEBActive_for_SRS 0 "not Active" 1 "Active.";
VAL_ 723 ACC_AEBStatus_for_SRS 0 "off" 1 "on" 2 " reserved" 3 "failure";

VAL_ 780 LAS_ResetSts 0 "Valid" 1 "GW请求复位" 2 "自身判断复位" 3 "不满足复位条件" 4 "Reserve" 7 "Invalid";

VAL_ 738 RLR_ElkOBJ2_Measured 0 "unknown" 1 "Measured" 2 "Predicted" 3 "Reserved";
VAL_ 738 RLR_ElkOBJ2_Location 0 "unknown" 1 "Left Lane" 2 "Right  Lane" 3 "Ego Lane";
VAL_ 738 RLR_ElkOBJ2_Type 0 "Not Detected" 1 "car" 2 "truck" 3 "bicycle/motorbike" 4 "pedestrian" 5 "general" 6 "animal" 7 "uncertain";
VAL_ 738 RLR_ElkOBJ1_Measured 0 "unknown" 1 "Measured" 2 "Predicted" 3 "Reserved";
VAL_ 738 RLR_ElkOBJ1_Location 0 "unknown" 1 "Left Lane" 2 "Right  Lane" 3 "Ego Lane";
VAL_ 738 RLR_ElkOBJ1_Type 0 "Not Detected" 1 "car" 2 "truck" 3 "bicycle/motorbike" 4 "pedestrian" 5 "general" 6 "animal" 7 "uncertain";

VAL_ 739 RLR_ElkOBJ4_Measured 0 "unknown" 1 "Measured" 2 "Predicted" 3 "Reserved";
VAL_ 739 RLR_ElkOBJ4_Location 0 "unknown" 1 "Left Lane" 2 "Right  Lane" 3 "Ego Lane";
VAL_ 739 RLR_ElkOBJ4_Type 0 "Not Detected" 1 "car" 2 "truck" 3 "bicycle/motorbike" 4 "pedestrian" 5 "general" 6 "animal" 7 "uncertain";
VAL_ 739 RLR_ElkOBJ3_Measured 0 "unknown" 1 "Measured" 2 "Predicted" 3 "Reserved";
VAL_ 739 RLR_ElkOBJ3_Location 0 "unknown" 1 "Left Lane" 2 "Right  Lane" 3 "Ego Lane";
VAL_ 739 RLR_ElkOBJ3_Type 0 "Not Detected" 1 "car" 2 "truck" 3 "bicycle/motorbike" 4 "pedestrian" 5 "general" 6 "animal" 7 "uncertain";

VAL_ 1304 BCM_CarMode 0 "车辆处于用户模式 " 1 " 车辆处于工厂模式" 2 "车辆处于运输模式" 3 " Reserved";

VAL_ 686 LCDAL_SystemStatus 0 "Reserved" 1 "StartUp" 2 "Running" 3 "Blocked" 4 "Calibration" 5 "ShutDown" 6 "Hot" 7 "Failure";

VAL_ 985 ACC_ObsTarget10ID 0 "not detect" 1 "1~30" 31 "invalid";
VAL_ 985 ACC_ObsTarget10Type 0 "no display" 1 "Cone Consideration" 2 "Warning Column" 3 "Water Horse" 4 "Anti-Collision Bucket" 5 "Emergancy Triangles" 6 "others" 7 "reserved";
VAL_ 985 ACC_ObsTarget10LatRange 0 "-50~50" 1001 "reserved";
VAL_ 985 ACC_ObsTarget10LngRange 0 "-20~120" 1401 "reserved";
VAL_ 985 ACC_ObsTarget9ID 0 "not detect" 1 "1~30" 31 "invalid";
VAL_ 985 ACC_ObsTarget9Type 0 "no display" 1 "Cone Consideration" 2 "Warning Column" 3 "Water Horse" 4 "Anti-Collision Bucket" 5 "Emergancy Triangles" 6 "others" 7 "reserved";
VAL_ 985 ACC_ObsTarget9LatRange 0 "-50~50" 1001 "reserved";
VAL_ 985 ACC_ObsTarget9LngRange 0 "-20~120" 1401 "reserved";
VAL_ 985 ACC_ObsTarget8ID 0 "not detect" 1 "1~30" 31 "invalid";
VAL_ 985 ACC_ObsTarget8Type 0 "no display" 1 "Cone Consideration" 2 "Warning Column" 3 "Water Horse" 4 "Anti-Collision Bucket" 5 "Emergancy Triangles" 6 "others" 7 "reserved";
VAL_ 985 ACC_ObsTarget8LatRange 0 "-50~50" 1001 "reserved";
VAL_ 985 ACC_ObsTarget8LngRange 0 "-20~120" 1401 "reserved";
VAL_ 985 ACC_ObsTarget7ID 0 "not detect" 1 "1~30" 31 "invalid";
VAL_ 985 ACC_ObsTarget7Type 0 "no display" 1 "Cone Consideration" 2 "Warning Column" 3 "Water Horse" 4 "Anti-Collision Bucket" 5 "Emergancy Triangles" 6 "others" 7 "reserved";
VAL_ 985 ACC_ObsTarget7LatRange 0 "-50~50" 1001 "reserved";
VAL_ 985 ACC_ObsTarget7LngRange 0 "-20~120" 1401 "reserved";
VAL_ 985 ACC_ObsTarget6ID 0 "not detect" 1 "1~30" 31 "invalid";
VAL_ 985 ACC_ObsTarget6Type 0 "no display" 1 "Cone Consideration" 2 "Warning Column" 3 "Water Horse" 4 "Anti-Collision Bucket" 5 "Emergancy Triangles" 6 "others" 7 "reserved";
VAL_ 985 ACC_ObsTarget6LatRange 0 "-50~50" 1001 "reserved";
VAL_ 985 ACC_ObsTarget6LngRange 0 "-20~120" 1401 "reserved";
VAL_ 985 ACC_ObsTarget5ID 0 "not detect" 1 "1~30" 31 "invalid";
VAL_ 985 ACC_ObsTarget5Type 0 "no display" 1 "Cone Consideration" 2 "Warning Column" 3 "Water Horse" 4 "Anti-Collision Bucket" 5 "Emergancy Triangles" 6 "others" 7 "reserved";
VAL_ 985 ACC_ObsTarget5LatRange 0 "-50~50" 1001 "reserved";
VAL_ 985 ACC_ObsTarget5LngRange 0 "-20~120" 1401 "reserved";
VAL_ 985 ACC_ObsTarget4ID 0 "not detect" 1 "1~30" 31 "invalid";
VAL_ 985 ACC_ObsTarget4Type 0 "no display" 1 "Cone Consideration" 2 "Warning Column" 3 "Water Horse" 4 "Anti-Collision Bucket" 5 "Emergancy Triangles" 6 "others" 7 "reserved";
VAL_ 985 ACC_ObsTarget4LatRange 0 "-50~50" 1001 "reserved";
VAL_ 985 ACC_ObsTarget4LngRange 0 "-20~120" 1401 "reserved";
VAL_ 985 ACC_ObsTarget3ID 0 "not detect" 1 "1~30" 31 "invalid";
VAL_ 985 ACC_ObsTarget3Type 0 "no display" 1 "Cone Consideration" 2 "Warning Column" 3 "Water Horse" 4 "Anti-Collision Bucket" 5 "Emergancy Triangles" 6 "others" 7 "reserved";
VAL_ 985 ACC_ObsTarget3LatRange 0 "-50~50" 1001 "reserved";
VAL_ 985 ACC_ObsTarget3LngRange 0 "-20~120" 1401 "reserved";
VAL_ 985 ACC_ObsTarget2ID 0 "not detect" 1 "1~30" 31 "invalid";
VAL_ 985 ACC_ObsTarget2Type 0 "no display" 1 "Cone Consideration" 2 "Warning Column" 3 "Water Horse" 4 "Anti-Collision Bucket" 5 "Emergancy Triangles" 6 "others" 7 "reserved";
VAL_ 985 ACC_ObsTarget2LatRange 0 "-50~50" 1001 "reserved";
VAL_ 985 ACC_ObsTarget2LngRange 0 "-20~120" 1401 "reserved";
VAL_ 985 ACC_ObsTarget1ID 0 "not detect" 1 "1~30" 31 "invalid";
VAL_ 985 ACC_ObsTarget1Type 0 "no display" 1 "Cone Consideration" 2 "Warning Column" 3 "Water Horse" 4 "Anti-Collision Bucket" 5 "Emergancy Triangles" 6 "others" 7 "reserved";
VAL_ 985 ACC_ObsTarget1LatRange 0 "-50~50" 1001 "reserved";
VAL_ 985 ACC_ObsTarget1LngRange 0 "-20~120" 1401 "reserved";

VAL_ 987 ACC_ObsTarget20ID 0 "not detect" 1 "1~30" 31 "invalid";
VAL_ 987 ACC_ObsTarget20Type 0 "no display" 1 "Cone Consideration" 2 "Warning Column" 3 "Water Horse" 4 "Anti-Collision Bucket" 5 "Emergancy Triangles" 6 "others" 7 "reserved";
VAL_ 987 ACC_ObsTarget20LatRange 0 "-50~50" 1001 "reserved";
VAL_ 987 ACC_ObsTarget20LngRange 0 "-20~120" 1401 "reserved";
VAL_ 987 ACC_ObsTarget19ID 0 "not detect" 1 "1~30" 31 "invalid";
VAL_ 987 ACC_ObsTarget19Type 0 "no display" 1 "Cone Consideration" 2 "Warning Column" 3 "Water Horse" 4 "Anti-Collision Bucket" 5 "Emergancy Triangles" 6 "others" 7 "reserved";
VAL_ 987 ACC_ObsTarget19LatRange 0 "-50~50" 1001 "reserved";
VAL_ 987 ACC_ObsTarget19LngRange 0 "-20~120" 1401 "reserved";
VAL_ 987 ACC_ObsTarget18ID 0 "not detect" 1 "1~30" 31 "invalid";
VAL_ 987 ACC_ObsTarget18Type 0 "no display" 1 "Cone Consideration" 2 "Warning Column" 3 "Water Horse" 4 "Anti-Collision Bucket" 5 "Emergancy Triangles" 6 "others" 7 "reserved";
VAL_ 987 ACC_ObsTarget18LatRange 0 "-50~50" 1001 "reserved";
VAL_ 987 ACC_ObsTarget18LngRange 0 "-20~120" 1401 "reserved";
VAL_ 987 ACC_ObsTarget17ID 0 "not detect" 1 "1~30" 31 "invalid";
VAL_ 987 ACC_ObsTarget17Type 0 "no display" 1 "Cone Consideration" 2 "Warning Column" 3 "Water Horse" 4 "Anti-Collision Bucket" 5 "Emergancy Triangles" 6 "others" 7 "reserved";
VAL_ 987 ACC_ObsTarget17LatRange 0 "-50~50" 1001 "reserved";
VAL_ 987 ACC_ObsTarget17LngRange 0 "-20~120" 1401 "reserved";
VAL_ 987 ACC_ObsTarget16ID 0 "not detect" 1 "1~30" 31 "invalid";
VAL_ 987 ACC_ObsTarget16Type 0 "no display" 1 "Cone Consideration" 2 "Warning Column" 3 "Water Horse" 4 "Anti-Collision Bucket" 5 "Emergancy Triangles" 6 "others" 7 "reserved";
VAL_ 987 ACC_ObsTarget16LatRange 0 "-50~50" 1001 "reserved";
VAL_ 987 ACC_ObsTarget16LngRange 0 "-20~120" 1401 "reserved";
VAL_ 987 ACC_ObsTarget15ID 0 "not detect" 1 "1~30" 31 "invalid";
VAL_ 987 ACC_ObsTarget15Type 0 "no display" 1 "Cone Consideration" 2 "Warning Column" 3 "Water Horse" 4 "Anti-Collision Bucket" 5 "Emergancy Triangles" 6 "others" 7 "reserved";
VAL_ 987 ACC_ObsTarget15LatRange 0 "-50~50" 1001 "reserved";
VAL_ 987 ACC_ObsTarget15LngRange 0 "-20~120" 1401 "reserved";
VAL_ 987 ACC_ObsTarget14ID 0 "not detect" 1 "1~30" 31 "invalid";
VAL_ 987 ACC_ObsTarget14Type 0 "no display" 1 "Cone Consideration" 2 "Warning Column" 3 "Water Horse" 4 "Anti-Collision Bucket" 5 "Emergancy Triangles" 6 "others" 7 "reserved";
VAL_ 987 ACC_ObsTarget14LatRange 0 "-50~50" 1001 "reserved";
VAL_ 987 ACC_ObsTarget14LngRange 0 "-20~120" 1401 "reserved";
VAL_ 987 ACC_ObsTarget13ID 0 "not detect" 1 "1~30" 31 "invalid";
VAL_ 987 ACC_ObsTarget13Type 0 "no display" 1 "Cone Consideration" 2 "Warning Column" 3 "Water Horse" 4 "Anti-Collision Bucket" 5 "Emergancy Triangles" 6 "others" 7 "reserved";
VAL_ 987 ACC_ObsTarget13LatRange 0 "-50~50" 1001 "reserved";
VAL_ 987 ACC_ObsTarget13LngRange 0 "-20~120" 1401 "reserved";
VAL_ 987 ACC_ObsTarget12ID 0 "not detect" 1 "1~30" 31 "invalid";
VAL_ 987 ACC_ObsTarget12Type 0 "no display" 1 "Cone Consideration" 2 "Warning Column" 3 "Water Horse" 4 "Anti-Collision Bucket" 5 "Emergancy Triangles" 6 "others" 7 "reserved";
VAL_ 987 ACC_ObsTarget12LatRange 0 "-50~50" 1001 "reserved";
VAL_ 987 ACC_ObsTarget12LngRange 0 "-20~120" 1401 "reserved";
VAL_ 987 ACC_ObsTarget11ID 0 "not detect" 1 "1~30" 31 "invalid";
VAL_ 987 ACC_ObsTarget11Type 0 "no display" 1 "Cone Consideration" 2 "Warning Column" 3 "Water Horse" 4 "Anti-Collision Bucket" 5 "Emergancy Triangles" 6 "others" 7 "reserved";
VAL_ 987 ACC_ObsTarget11LatRange 0 "-50~50" 1001 "reserved";
VAL_ 987 ACC_ObsTarget11LngRange 0 "-20~120" 1401 "reserved";

VAL_ 881 PCU_DrvMod2 0 "Inactive" 1 "ECO" 2 "normal" 3 "sport" 4 "自定义1" 5 "专属模式" 6 "Reserved";
VAL_ 881 PCU_SpecialModeSetFB 0 "reserved" 1 "reserved" 2 "长途模式" 3 "山地模式" 4 "应急模式" 5 "驻车模式" 6 "Super Race";

VAL_ 796 PCU_VcuRdySts 0 "no Ready" 1 "Ready";
VAL_ 796 PCU_PowerOutputSts 0 "inactive" 1 "佛系" 2 "普通" 3 "激进" 4 "Reserved（保留）" 7 "Invalid";

VAL_ 266 EPB_SwitchPosition 0 "no request" 1 "Release request" 2 "Apply request" 3 "Error";
VAL_ 266 EPB_Status 0 "both brakes released" 1 "both brakes applied" 2 "both brakes in operation (applying/releasing)" 3 "unknown";
VAL_ 266 EPB_FailStatus 0 "no error in EPB – external apply available" 1 "not defined" 2 "not defined" 3 "error in EPB – no external apply allowed";
VAL_ 266 EPB_AchievedClampForce 0 "ClampForce" 30 "Reserved" 31 "Error";

VAL_ 879 LAS_OverspeedWarningRatioOffset_EU 0 "-3%~3%" 13 "Reserved" 47 "Invalid.";
VAL_ 879 LAS_TSRSpeedLimitChangeSoundEnSt 0 "Inactive" 1 "Off" 2 "On" 3 "Reserved";
VAL_ 879 LAS_TSRSpeedLimitStatus 0 " Invalid" 1 "valid" 2 " Uncertain speed limit" 3 "Reserved";
VAL_ 879 LAS_TSRNavCountryCode 0 "Unknown" 1 "Afghanistan" 2 "Albania" 3 "Algeria" 4 "American Samoa" 5 "Andorra" 6 "Angola" 7 "Anguilla" 8 "Antarctica" 9 "Antigua and Barbuda" 10 "Argentina" 11 "Armenia" 12 "Aruba" 13 "Australia" 14 "Austria" 15 "Azerbaijan" 16 "Bahamas" 17 "Bahrain" 18 "Bangladesh" 19 "Barbados" 20 "Belarus" 21 "Belgium" 22 "Belize" 23 "Benin" 24 "Bermuda" 25 "Bhutan" 26 "Bolivia" 27 "Bosnia and Herzegovina" 28 "Botswana" 29 "Bouvet Island" 30 "Brazil" 31 "British Indian Ocean Territory" 32 "Brunei Darussalam" 33 "Bulgaria" 34 "Burkina Faso" 35 "Burundi" 36 "Cambodia" 37 "Cameroon" 38 "Canada" 39 "Cabo Verde" 40 "Cayman Islands" 41 "Central African Republic" 42 "Chad" 43 "Chile" 44 "China" 45 "Christmas Island" 46 "Cocos (Keeling) Islands" 47 "Colombia" 48 "Comoros" 49 "Congo" 50 "Congo (Democratic Republic of the)" 51 "Cook Islands" 52 "Costa Rica" 53 "C?te d'Ivoire" 54 "Croatia" 55 "Cuba" 56 "Cyprus" 57 "Czech Republic" 58 "Denmark" 59 "Djibouti" 60 "Dominica" 61 "Dominican Republic" 62 "Timor-Leste (East Timor)" 63 "Ecuador" 64 "Egypt" 65 "El Salvador" 66 "Equatorial Guinea" 67 "Eritrea" 68 "Estonia" 69 "Ethiopia" 70 "Falkland Islands (Malvinas)" 71 "Faroe Islands" 72 "Fiji" 73 "Finland" 74 "France" 75 "FRANCE_METROPOLITAN currently not used France is coded as FRANCE" 76 "French Guiana" 77 "French Polynesia" 78 "French Southern Territories" 79 "Gabon" 80 "Gambia" 81 "Georgia" 82 "Germany" 83 "Ghana" 84 "Gibraltar" 85 "Greece" 86 "Greenland" 87 "Grenada" 88 "Guadeloupe" 89 "Guam" 90 "Guatemala" 91 "Guinea" 92 "Guinea-Bissau" 93 "Guyana" 94 "Haiti" 95 "Heard Island and McDonald Islands" 96 "Honduras" 97 "Hong Kong" 98 "Hungary" 99 "Iceland" 100 "India" 101 "Indonesia" 102 "Iran (Islamic Republic of)" 103 "Iraq" 104 "Ireland" 105 "Israel" 106 "Italy" 107 "Jamaica" 108 "Japan" 109 "Jordan" 110 "Kazakhstan" 111 "Kenya" 112 "Kiribati" 113 "Korea (Democratic People's Republic of)" 114 "Korea (Republic of)" 115 "Kuwait" 116 "Kyrgyzstan" 117 "Lao People's Democratic Republic" 118 "Latvia" 119 "Lebanon" 120 "Lesotho" 121 "Liberia" 122 "Libya" 123 "Liechtenstein" 124 "Lithuania" 125 "Luxembourg" 126 "Macao" 127 "Macedonia (the former Yugoslav Republic of)" 128 "Madagascar" 129 "Malawi" 130 "Malaysia" 131 "Maldives" 132 "Mali" 133 "Malta" 134 "Marshall Islands" 135 "Martinique" 136 "Mauritania" 137 "Mauritius" 138 "Mayotte" 139 "Mexico" 140 "Micronesia (Federated States of)" 141 "Moldova (Republic of)" 142 "Monaco" 143 "Mongolia" 144 "Montserrat" 145 "Morocco" 146 "Mozambique" 147 "Myanmar" 148 "Namibia" 149 "Nauru" 150 "Nepal" 151 "Netherlands" 152 "NETHERLANDS_ANTILLES" 153 "New Caledonia" 154 "New Zealand" 155 "Nicaragua" 156 "Niger" 157 "Nigeria" 158 "Niue" 159 "Norfolk Island" 160 "Northern Mariana Islands" 161 "Norway" 162 "Oman" 163 "Pakistan" 164 "Palau" 165 "Palestine, State of" 166 "Panama" 167 "Papua New Guinea" 168 "Paraguay" 169 "Peru" 170 "Philippines" 171 "Pitcairn" 172 "Poland" 173 "Portugal" 174 "Puerto Rico" 175 "Qatar" 176 "R?union" 177 "Romania" 178 "Russian Federation" 179 "Rwanda" 180 "Saint Kitts and Nevis" 181 "Saint Lucia" 182 "Saint Vincent and the Grenadines" 183 "Samoa" 184 "San Marino" 185 "Sao Tome and Principe" 186 "Saudi Arabia" 187 "Senegal" 188 "Seychelles" 189 "Sierra Leone" 190 "Singapore" 191 "Slovakia" 192 "Slovenia" 193 "Solomon Islands" 194 "Somalia" 195 "South Africa" 196 "South Georgia and the South Sandwich Islands" 197 "Spain" 198 "Sri Lanka" 199 "Saint Helena, Ascension and Tristan da Cunha" 200 "Saint Pierre and Miquelon" 201 "Sudan" 202 "Suriname" 203 "Svalbard and Jan Mayen" 204 "Swaziland" 205 "Sweden" 206 "Switzerland" 207 "Syrian Arab Republic" 208 "Taiwan, Province of China" 209 "Tajikistan" 210 "Tanzania, United Republic of" 211 "Thailand" 212 "Togo" 213 "Tokelau" 214 "Tonga" 215 "Trinidad and Tobago" 216 "Tunisia" 217 "Turkey" 218 "Turkmenistan" 219 "Turks and Caicos Islands" 220 "Tuvalu" 221 "Uganda" 222 "Ukraine" 223 "United Arab Emirates" 224 "United Kingdom of Great Britain and Northern Ireland" 225 "United States of America" 226 "United States Minor Outlying Islands" 227 "Uruguay" 228 "Uzbekistan" 229 "Vanuatu" 230 "VATICAN" 231 "Venezuela (Bolivarian Republic of)" 232 "Viet Nam" 233 "Virgin Islands (British)" 234 "Virgin Islands (U.S.)" 235 "Wallis and Futuna" 236 "Western Sahara" 237 "Yemen" 238 "Serbia" 239 "Zambia" 240 "Zimbabwe" 241 "CROATIA2" 242 "MACEDONIA2" 243 "BOSNIA_HERZEGOVINA" 244 "Montenegro" 245 "South Sudan" 246 "Guernsey" 247 "Jersey" 248 "Isle of Man" 249 "?land Islands" 250 "Kosovo" 251 "reserved";

VAL_ 349 ESP_IMUCalibrated 0 "Calibrated" 1 "Not Calibrated";
VAL_ 349 ESP_YawRateValid 0 "Initializing" 1 "Valid" 2 "Invalid" 3 "Reserved";
VAL_ 349 ESP_LatAccelValid 0 "Initializing" 1 "Valid" 2 "Invalid" 3 "Reserved";
VAL_ 349 ESP_LongAccelValid 0 "Initializing" 1 "Valid" 2 "Invalid" 3 "Reserved";

VAL_ 271 IBCU_sOutputRodAct_Q 0 "SoutputRodAct_NotInitialized" 1 "SoutputRodAct_Normal" 2 "SoutputRodAct_Faulty";
VAL_ 271 IBCU_sOutputRodDriver_Q 0 "soutputRodDriver_NotInitialized未初始化" 1 "soutputRodDriver_Normal正常" 2 "soutputRodDriver_Faulty错误";

VAL_ 810 TRM_ConnectSts 0 "NoConnected" 1 "Connected";

VAL_ 1323 ACC_Target1LatRelSpeed 0 "-64~63.875
0x400=unknown";

VAL_ 1330 ACC_Target2LatRelSpeed 0 "-64~63.875
0x400=unknown";

VAL_ 1331 ADS_IACC_LatTakeOverReason 0 "无
0x1=异常退出
0x2=安全停车
0x3=车道线丢失
0x4=压线
0x5=前方障碍物
0x6=截止车道
0x7=曲率过大
0x8=IACC故障
0x9=其他
0xA~F=Reserved";
VAL_ 1331 ACC_RLaneQuality 0 "";
VAL_ 1331 ACC_DOSECountDown 1 "0s" 2 "1s" 3 "2s" 4 "3s" 5 "4s" 6 "5s" 7 "6s" 8 "7s" 9 "8s" 10 "9s" 11 "10s" 12 "11s" 13 "12s" 14 "13s" 15 "14s" 16 "15s" 17 "Reserved";
VAL_ 1331 ACC_Target7LatRelSpeed 0 "-64~63.875
0x400=unknown";
VAL_ 1331 ACC_Target6LatRelSpeed 0 "-64~63.875
0x400=unknown";
VAL_ 1331 ACC_Target5LatRelSpeed 0 "-64~63.875
0x400=unknown";
VAL_ 1331 ACC_Target4LatRelSpeed 0 "-64~63.875
0x400=unknown";
VAL_ 1331 ACC_Target3LatRelSpeed 0 "-64~63.875
0x400=unknown";

VAL_ 375 LAS_ReqSYNMSG 0 "NoRequest" 1 "请求25C同步报文加1发送" 2 "Reserved";

VAL_ 583 APA_APAOnOff 0 "OFF" 1 "ON";

VAL_ 710 APA_vehicleFrontdetect 0 "No Detect" 1 "Detect" 2 "Reserved" 3 "Invalid";

VAL_ 953 BDC_TurnLightSw 0 "Initial" 1 "Left 1" 2 "Right 1" 3 "Left 2" 4 "Right 2" 5 "Invalid";

VAL_ 901 HU_CDCUnitSystSetStatus 0 "no req
0x1=kph
0x2=mph";

VAL_ 456 ESP_EngTorqIncRearActive 1 "Active," 0 "NotActive,";
